VERSION "HNNBNNNYNNNNNNNNNNNNNNNNNNNNNNNNNNNNNNNNNN/4/%%%/4/'%**4NNN///"

NS_ :

BS_:

BU_: Airbag BAP_Tester ICAS1_Gateway ICAS1_KommunikationsServer LE1 LE2 Motor_BEV Schaltbetaetigung

BO_ 333 ACC_18: 32 ICAS1_Gateway
 SG_ ACC_18_CRC : 0|8@1+ (1,0) [0|255] "mietek ooo"  Motor_BEV
 SG_ ACC_18_BZ : 8|4@1+ (1,0) [0|15] ""  Motor_BEV
 SG_ ACC_limitierte_Anfahrdyn : 12|1@1+ (1.0,0.0) [0.0|1] ""  Motor_BEV
 SG_ ACC_nachtr_Stopp_Anf : 13|1@1+ (1.0,0.0) [0.0|1] ""  Vector__XXX
 SG_ ACC_DynErhoehung : 14|1@1+ (1.0,0.0) [0.0|1] ""  Motor_BEV
 SG_ ACC_Freilaufstrategie_TSK : 15|1@1+ (1.0,0.0) [0.0|1] ""  Motor_BEV
 SG_ ACC_zul_Regelabw_unten : 16|6@1+ (0.024,0) [0.000|1.512] "Unit_MeterPerSeconSquar"  Motor_BEV
 SG_ ACC_StartStopp_Info : 22|2@1+ (1.0,0.0) [0.0|3] ""  Vector__XXX
 SG_ ACC_Sollbeschleunigung_02 : 24|11@1+ (0.005,-7.22) [-7.220|3.005] "Unit_MeterPerSeconSquar"  Motor_BEV
 SG_ ACC_zul_Regelabw_oben : 35|5@1+ (0.0625,0) [0.0000|1.9375] "Unit_MeterPerSeconSquar"  Motor_BEV
 SG_ ACC_neg_Sollbeschl_Grad_02 : 40|8@1+ (0.05,0) [0.00|12.75] "Unit_MeterPerCubicSecon"  Motor_BEV
 SG_ ACC_pos_Sollbeschl_Grad_02 : 48|8@1+ (0.05,0) [0.00|12.75] "Unit_MeterPerCubicSecon"  Motor_BEV
 SG_ ACC_Anfahren : 56|1@1+ (1.0,0.0) [0.0|1] ""  Motor_BEV
 SG_ ACC_Anhalten : 57|1@1+ (1.0,0.0) [0.0|1] ""  Motor_BEV
 SG_ ACC_Typ : 58|2@1+ (1.0,0.0) [0.0|3] ""  Motor_BEV
 SG_ ACC_Status_ACC : 60|3@1+ (1.0,0.0) [0.0|7] ""  Motor_BEV
 SG_ ACC_Minimale_Bremsung : 63|1@1+ (1.0,0.0) [0.0|1] ""  Motor_BEV
 SG_ ACC_Anhalteweg : 64|11@1+ (0.01,0) [0.00|20.45] "Unit_Meter"  Vector__XXX
 SG_ ACC_Boost : 75|1@1+ (1.0,0.0) [0.0|1] ""  Vector__XXX
 SG_ ACC_Freilauf_Anf : 76|1@1+ (1.0,0.0) [0.0|1] ""  Vector__XXX
 SG_ ACC_Anforderung_HMS : 77|3@1+ (1.0,0.0) [0.0|7] ""  Vector__XXX
 SG_ ACC_Folgebeschl : 80|8@1+ (0.03,-4.6) [-4.60|2.99] "Unit_MeterPerSeconSquar"  Motor_BEV
 SG_ ACC_Freilauf_Info : 88|2@1+ (1.0,0.0) [0.0|3] ""  Motor_BEV
 SG_ ACC_Tempolimitassistent_Ein : 90|1@1+ (1.0,0.0) [0.0|1] ""  Vector__XXX
 SG_ ACC_FoD_Status : 91|2@1+ (1.0,0.0) [0.0|3] ""  Motor_BEV
 SG_ vESC_Verz_Anf : 232|4@1+ (0.5,0) [0.0|3.5] "Unit_MeterPerSeconSquar"  Vector__XXX
 SG_ RDR_v_ueber_Grund : 236|12@1+ (0.1,0) [0.0|409.0] "Unit_KiloMeterPerHour"  Vector__XXX
 SG_ RDR_v_ueber_Grund_Genauigkeit : 248|6@1+ (0.1,0) [0.0|6.0] "Unit_KiloMeterPerHour"  Vector__XXX
 SG_ RDR_v_ueber_Grund_Fahrtrichtung : 254|2@1+ (1.0,0.0) [0.0|3] ""  Vector__XXX

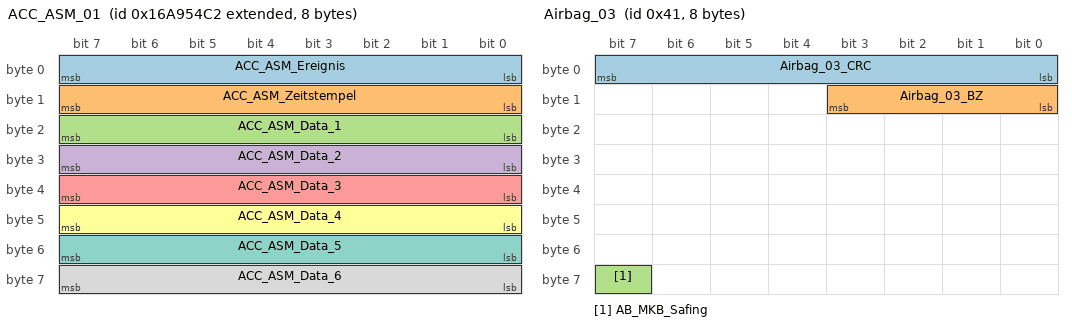
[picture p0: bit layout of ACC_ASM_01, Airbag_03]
BO_ 2527679682 ACC_ASM_01: 8 ICAS1_Gateway
 SG_ ACC_ASM_Ereignis : 0|8@1+ (1,0) [1|254] ""  Airbag
 SG_ ACC_ASM_Zeitstempel : 8|8@1+ (0.08,0) [0.00|20.32] "Unit_Secon"  Airbag
 SG_ ACC_ASM_Data_1 : 16|8@1+ (1,0) [0|255] ""  Airbag
 SG_ ACC_ASM_Data_2 : 24|8@1+ (1,0) [0|255] ""  Airbag
 SG_ ACC_ASM_Data_3 : 32|8@1+ (1,0) [0|255] ""  Airbag
 SG_ ACC_ASM_Data_4 : 40|8@1+ (1,0) [0|255] ""  Airbag
 SG_ ACC_ASM_Data_5 : 48|8@1+ (1,0) [0|255] ""  Airbag
 SG_ ACC_ASM_Data_6 : 56|8@1+ (1,0) [0|255] ""  Airbag

BO_ 64 Airbag_01: 8 Airbag
 SG_ Airbag_01_CRC : 0|8@1+ (1,0) [0|255] ""  ICAS1_Gateway,LE1,LE2,Motor_BEV
 SG_ Airbag_01_BZ : 8|4@1+ (1,0) [0|15] ""  ICAS1_Gateway,LE1,LE2,Motor_BEV
 SG_ AB_RGS_Anst : 12|4@1+ (1.0,0.0) [0.0|15] ""  ICAS1_Gateway,ICAS1_KommunikationsServer
 SG_ AB_Front_Crash : 16|1@1+ (1.0,0.0) [0.0|1] ""  ICAS1_Gateway
 SG_ AB_Heck_Crash : 17|1@1+ (1.0,0.0) [0.0|1] ""  ICAS1_Gateway
 SG_ AB_SF_Crash : 18|1@1+ (1.0,0.0) [0.0|1] ""  ICAS1_Gateway
 SG_ AB_SB_Crash : 19|1@1+ (1.0,0.0) [0.0|1] ""  ICAS1_Gateway
 SG_ AB_Rollover_Crash : 20|1@1+ (1.0,0.0) [0.0|1] ""  ICAS1_Gateway
 SG_ AB_Crash_Int : 21|3@1+ (1.0,0.0) [0.0|7] ""  ICAS1_Gateway,ICAS1_KommunikationsServer,Motor_BEV
 SG_ AB_Lampe : 24|1@1+ (1.0,0.0) [0.0|1] ""  ICAS1_Gateway,ICAS1_KommunikationsServer
 SG_ AB_Deaktiviert : 25|1@1+ (1.0,0.0) [0.0|1] ""  ICAS1_Gateway
 SG_ AB_VB_deaktiviert : 26|1@1+ (1.0,0.0) [0.0|1] ""  ICAS1_Gateway
 SG_ AB_Systemfehler : 27|1@1+ (1.0,0.0) [0.0|1] ""  ICAS1_Gateway,ICAS1_KommunikationsServer
 SG_ AB_Diagnose : 28|1@1+ (1.0,0.0) [0.0|1] ""  ICAS1_Gateway
 SG_ AB_Stellgliedtest : 29|1@1+ (1.0,0.0) [0.0|1] ""  ICAS1_Gateway
 SG_ AB_Erh_Auf_VB : 30|2@1+ (1.0,0.0) [0.0|3] ""  ICAS1_Gateway
 SG_ AB_Gurtwarn_VF : 32|1@1+ (1.0,0.0) [0.0|1] ""  ICAS1_Gateway,ICAS1_KommunikationsServer
 SG_ AB_Gurtwarn_VB : 33|1@1+ (1.0,0.0) [0.0|1] ""  ICAS1_Gateway,ICAS1_KommunikationsServer
 SG_ AB_Anzeige_Fussg : 34|2@1+ (1.0,0.0) [0.0|3] ""  ICAS1_Gateway
 SG_ AB_Texte_AKS : 36|2@1+ (1.0,0.0) [0.0|3] ""  ICAS1_Gateway
 SG_ AB_PAO_Leuchte_Anf : 38|1@1+ (1.0,0.0) [0.0|1] ""  ICAS1_Gateway
 SG_ AB_MKB_gueltig : 39|1@1+ (1.0,0.0) [0.0|1] ""  ICAS1_Gateway
 SG_ AB_MKB_Anforderung : 40|1@1+ (1.0,0.0) [0.0|1] ""  ICAS1_Gateway
 SG_ AB_Versorgungsspannung : 41|1@1+ (1.0,0.0) [0.0|1] ""  ICAS1_Gateway
 SG_ AB_Deaktivierung_HV : 42|3@1+ (1.0,0.0) [0.0|7] ""  ICAS1_Gateway,ICAS1_KommunikationsServer,LE1,LE2,Motor_BEV
 SG_ AB_EDR_Trigger : 45|2@1+ (1.0,0.0) [0.0|3] ""  ICAS1_Gateway
 SG_ AB_Belegung_VF : 47|2@1+ (1.0,0.0) [0.0|3] ""  ICAS1_Gateway
 SG_ AB_Gurtschloss_FA_ext : 49|3@1+ (1.0,0.0) [0.0|7] ""  ICAS1_Gateway
 SG_ AB_Belegung_VF_ext : 52|3@1+ (1.0,0.0) [0.0|7] ""  ICAS1_Gateway
 SG_ ASM_Masterzeit : 56|8@1+ (0.08,0) [0.00|20.32] "Unit_Secon"  ICAS1_Gateway

BO_ 1312 Airbag_02: 8 Airbag
 SG_ Airbag_02_CRC : 0|8@1+ (1,0) [0|255] ""  ICAS1_Gateway,Motor_BEV
 SG_ Airbag_02_BZ : 8|4@1+ (1,0) [0|15] ""  ICAS1_Gateway,Motor_BEV
 SG_ LoGeWa_Event_Kombiwarnung : 12|4@1+ (1.0,0.0) [0.0|15] ""  ICAS1_Gateway
 SG_ AB_Anforderung_eCall : 16|1@1+ (1.0,0.0) [0.0|1] ""  ICAS1_Gateway
 SG_ AB_Anprall_Seite_Beifahrer : 17|1@1+ (1.0,0.0) [0.0|1] ""  ICAS1_Gateway,ICAS1_KommunikationsServer
 SG_ AB_Anprall_Rollover : 18|1@1+ (1.0,0.0) [0.0|1] ""  ICAS1_Gateway,ICAS1_KommunikationsServer
 SG_ AB_Anprall_FGS : 19|1@1+ (1.0,0.0) [0.0|1] ""  ICAS1_Gateway,ICAS1_KommunikationsServer
 SG_ AB_Anprall_Front_Beifahrer : 20|1@1+ (1.0,0.0) [0.0|1] ""  ICAS1_Gateway,ICAS1_KommunikationsServer
 SG_ AB_Anprall_Front_Fahrer : 21|1@1+ (1.0,0.0) [0.0|1] ""  ICAS1_Gateway,ICAS1_KommunikationsServer
 SG_ AB_Anprall_Heck_Beifahrer : 22|1@1+ (1.0,0.0) [0.0|1] ""  ICAS1_Gateway,ICAS1_KommunikationsServer
 SG_ AB_Anprall_Heck_Fahrer : 23|1@1+ (1.0,0.0) [0.0|1] ""  ICAS1_Gateway,ICAS1_KommunikationsServer
 SG_ AB_Wickelklappung_Reihe2_MI : 24|2@1+ (1.0,0.0) [0.0|3] ""  ICAS1_Gateway
 SG_ AB_Belegung_VB : 26|2@1+ (1.0,0.0) [0.0|3] ""  ICAS1_Gateway
 SG_ AB_Abschaltanf_SIH_BF : 28|1@1+ (1.0,0.0) [0.0|1] ""  ICAS1_Gateway
 SG_ AB_Anprall_Seite_Fahrer : 29|1@1+ (1.0,0.0) [0.0|1] ""  ICAS1_Gateway,ICAS1_KommunikationsServer
 SG_ SC_PAO_Schriftzug_Anf : 30|2@1+ (1.0,0.0) [0.0|3] ""  ICAS1_Gateway
 SG_ SC_PAO_ON_Anf : 32|2@1+ (1.0,0.0) [0.0|3] ""  ICAS1_Gateway
 SG_ SC_PAO_OFF_Anf : 34|2@1+ (1.0,0.0) [0.0|3] ""  ICAS1_Gateway
 SG_ AB_Crashschwere : 36|3@1+ (1.0,0.0) [0.0|7] ""  ICAS1_Gateway,ICAS1_KommunikationsServer
 SG_ AB_Anforderung_USM : 39|1@1+ (1.0,0.0) [0.0|1] ""  ICAS1_Gateway
 SG_ AB_Gurtschloss_FA : 40|2@1+ (1.0,0.0) [0.0|3] ""  ICAS1_Gateway,ICAS1_KommunikationsServer,Motor_BEV
 SG_ AB_Gurtschloss_BF : 42|2@1+ (1.0,0.0) [0.0|3] ""  ICAS1_Gateway,ICAS1_KommunikationsServer
 SG_ AB_Gurtschloss_Reihe2_FA : 44|2@1+ (1.0,0.0) [0.0|3] ""  ICAS1_Gateway,ICAS1_KommunikationsServer
 SG_ AB_Gurtschloss_Reihe2_MI : 46|2@1+ (1.0,0.0) [0.0|3] ""  ICAS1_Gateway,ICAS1_KommunikationsServer
 SG_ AB_Gurtschloss_Reihe2_BF : 48|2@1+ (1.0,0.0) [0.0|3] ""  ICAS1_Gateway,ICAS1_KommunikationsServer
 SG_ AB_Gurtschloss_Reihe3_FA : 50|2@1+ (1.0,0.0) [0.0|3] ""  ICAS1_Gateway,ICAS1_KommunikationsServer
 SG_ AB_Gurtschloss_Reihe3_MI : 52|2@1+ (1.0,0.0) [0.0|3] ""  ICAS1_Gateway,ICAS1_KommunikationsServer
 SG_ AB_Gurtschloss_Reihe3_BF : 54|2@1+ (1.0,0.0) [0.0|3] ""  ICAS1_Gateway,ICAS1_KommunikationsServer
 SG_ AB_Sitzpos_Sens_FA : 56|2@1+ (1.0,0.0) [0.0|3] ""  ICAS1_Gateway
 SG_ AB_Sitzpos_Sens_BF : 58|2@1+ (1.0,0.0) [0.0|3] ""  ICAS1_Gateway
 SG_ AB_Wickelklappung_Reihe2_BF : 60|2@1+ (1.0,0.0) [0.0|3] ""  ICAS1_Gateway
 SG_ AB_Wickelklappung_Reihe2_FA : 62|2@1+ (1.0,0.0) [0.0|3] ""  ICAS1_Gateway

BO_ 65 Airbag_03: 8 Airbag
 SG_ Airbag_03_CRC : 0|8@1+ (1,0) [0|255] ""  ICAS1_Gateway
 SG_ Airbag_03_BZ : 8|4@1+ (1,0) [0|15] ""  ICAS1_Gateway
 SG_ AB_MKB_Safing : 63|1@1+ (1.0,0.0) [0.0|1] ""  ICAS1_Gateway

BO_ 1349 Airbag_04: 8 Airbag
 SG_ AB_Gurtwarn_Reihe4_FA : 14|2@1+ (1.0,0.0) [0.0|3] ""  ICAS1_Gateway,ICAS1_KommunikationsServer
 SG_ AB_Gurtwarn_Reihe4_BF : 16|2@1+ (1.0,0.0) [0.0|3] ""  ICAS1_Gateway,ICAS1_KommunikationsServer
 SG_ AB_Gurtwarn_Reihe4_MI : 18|2@1+ (1.0,0.0) [0.0|3] ""  ICAS1_Gateway,ICAS1_KommunikationsServer
 SG_ AB_Gurtwarn_Reihe2_FA : 20|2@1+ (1.0,0.0) [0.0|3] ""  ICAS1_Gateway,ICAS1_KommunikationsServer
 SG_ AB_Gurtwarn_Reihe2_BF : 22|2@1+ (1.0,0.0) [0.0|3] ""  ICAS1_Gateway,ICAS1_KommunikationsServer
 SG_ AbstWarn_MV_FAS_Fkt_Status : 24|2@1+ (1.0,0.0) [0.0|3] ""  ICAS1_Gateway
 SG_ WarnBrems_Charisma_Status : 26|2@1+ (1.0,0.0) [0.0|3] ""  ICAS1_Gateway
 SG_ WarnBrems_Charisma_FahrPr : 28|4@1+ (1.0,0.0) [0.0|15] ""  ICAS1_Gateway
 SG_ AB_Gurtwarn_Reihe2_MI : 32|2@1+ (1.0,0.0) [0.0|3] ""  ICAS1_Gateway,ICAS1_KommunikationsServer
 SG_ AB_Gurtwarn_Reihe3_FA : 34|2@1+ (1.0,0.0) [0.0|3] ""  ICAS1_Gateway,ICAS1_KommunikationsServer
 SG_ AB_Gurtwarn_Reihe3_MI : 36|2@1+ (1.0,0.0) [0.0|3] ""  ICAS1_Gateway,ICAS1_KommunikationsServer
 SG_ AB_Gurtwarn_Reihe3_BF : 38|2@1+ (1.0,0.0) [0.0|3] ""  ICAS1_Gateway,ICAS1_KommunikationsServer
 SG_ LGI_FAS_Fkt_Status : 40|2@1+ (1.0,0.0) [0.0|3] ""  ICAS1_Gateway
 SG_ PreCrash_FAS_Fkt_Status : 42|3@1+ (1.0,0.0) [0.0|7] ""  ICAS1_Gateway
 SG_ AB_SBR_hinten_verbau : 48|2@1+ (1.0,0.0) [0.0|3] ""  ICAS1_Gateway,ICAS1_KommunikationsServer
 SG_ AWV_Einstellung_System_ASG : 51|1@1+ (1.0,0.0) [0.0|1] ""  ICAS1_Gateway
 SG_ AWV_Einstellung_Warnung_ASG : 52|3@1+ (1.0,0.0) [0.0|7] ""  ICAS1_Gateway
 SG_ SC_PreSense_Modus_Warnung_NV : 55|3@1+ (1.0,0.0) [0.0|7] ""  ICAS1_Gateway
 SG_ SC_PreSense_Modus_Warnung_MV : 58|3@1+ (1.0,0.0) [0.0|7] ""  ICAS1_Gateway
 SG_ SC_PreSense_Modus_System_MV : 61|1@1+ (1.0,0.0) [0.0|1] ""  ICAS1_Gateway
 SG_ SC_PreSense_Modus_System_NV : 62|1@1+ (1.0,0.0) [0.0|1] ""  ICAS1_Gateway
 SG_ SC_PreSense_Modus_System_KAS : 63|1@1+ (1.0,0.0) [0.0|1] ""  ICAS1_Gateway

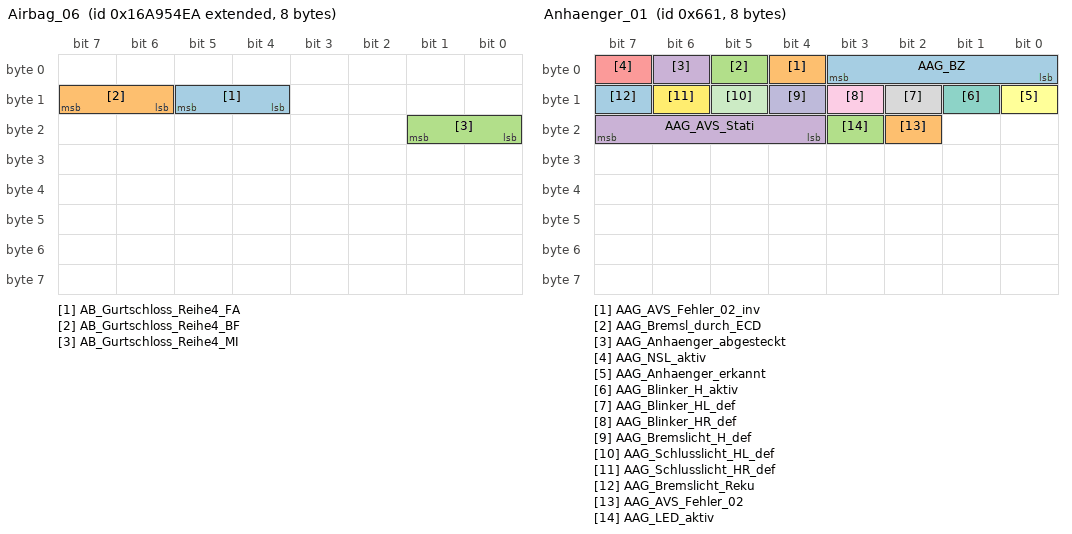
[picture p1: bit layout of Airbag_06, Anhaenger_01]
BO_ 2527679722 Airbag_06: 8 Airbag
 SG_ AB_Gurtschloss_Reihe4_FA : 12|2@1+ (1.0,0.0) [0.0|3] ""  ICAS1_Gateway,ICAS1_KommunikationsServer
 SG_ AB_Gurtschloss_Reihe4_BF : 14|2@1+ (1.0,0.0) [0.0|3] ""  ICAS1_Gateway,ICAS1_KommunikationsServer
 SG_ AB_Gurtschloss_Reihe4_MI : 16|2@1+ (1.0,0.0) [0.0|3] ""  ICAS1_Gateway,ICAS1_KommunikationsServer

BO_ 1633 Anhaenger_01: 8 ICAS1_Gateway
 SG_ AAG_BZ : 0|4@1+ (1,0) [0|15] ""  Vector__XXX
 SG_ AAG_AVS_Fehler_02_inv : 4|1@1+ (1.0,0.0) [0.0|1] ""  Vector__XXX
 SG_ AAG_Bremsl_durch_ECD : 5|1@1+ (1.0,0.0) [0.0|1] ""  Motor_BEV
 SG_ AAG_Anhaenger_abgesteckt : 6|1@1+ (1.0,0.0) [0.0|1] ""  Motor_BEV
 SG_ AAG_NSL_aktiv : 7|1@1+ (1.0,0.0) [0.0|1] ""  Vector__XXX
 SG_ AAG_Anhaenger_erkannt : 8|1@1+ (1.0,0.0) [0.0|1] ""  Motor_BEV
 SG_ AAG_Blinker_H_aktiv : 9|1@1+ (1.0,0.0) [0.0|1] ""  Vector__XXX
 SG_ AAG_Blinker_HL_def : 10|1@1+ (1.0,0.0) [0.0|1] ""  Vector__XXX
 SG_ AAG_Blinker_HR_def : 11|1@1+ (1.0,0.0) [0.0|1] ""  Vector__XXX
 SG_ AAG_Bremslicht_H_def : 12|1@1+ (1.0,0.0) [0.0|1] ""  Motor_BEV
 SG_ AAG_Schlusslicht_HL_def : 13|1@1+ (1.0,0.0) [0.0|1] ""  Vector__XXX
 SG_ AAG_Schlusslicht_HR_def : 14|1@1+ (1.0,0.0) [0.0|1] ""  Vector__XXX
 SG_ AAG_Bremslicht_Reku : 15|1@1+ (1.0,0.0) [0.0|1] ""  Vector__XXX
 SG_ AAG_AVS_Fehler_02 : 18|1@1+ (1.0,0.0) [0.0|1] ""  Vector__XXX
 SG_ AAG_LED_aktiv : 19|1@1+ (1.0,0.0) [0.0|1] ""  Vector__XXX
 SG_ AAG_AVS_Stati : 20|4@1+ (1.0,0.0) [0.0|15] ""  Vector__XXX

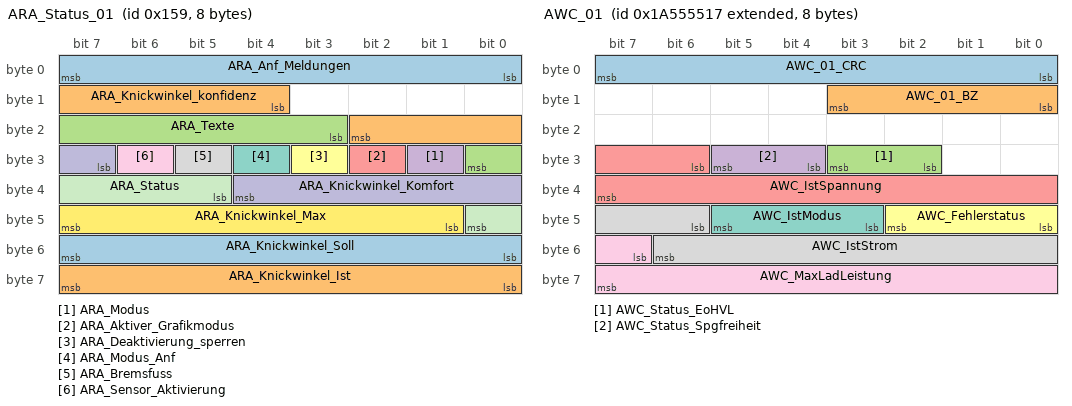
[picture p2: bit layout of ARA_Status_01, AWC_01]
BO_ 345 ARA_Status_01: 8 ICAS1_Gateway
 SG_ ARA_Anf_Meldungen : 0|8@1+ (1.0,0.0) [0.0|255] ""  Vector__XXX
 SG_ ARA_Knickwinkel_konfidenz : 12|7@1+ (1,0) [0|120] "Unit_DegreOfArc"  Vector__XXX
 SG_ ARA_Texte : 19|6@1+ (1.0,0.0) [0.0|63] ""  Vector__XXX
 SG_ ARA_Modus : 25|1@1+ (1.0,0.0) [0.0|1] ""  Vector__XXX
 SG_ ARA_Aktiver_Grafikmodus : 26|1@1+ (1.0,0.0) [0.0|1] ""  Vector__XXX
 SG_ ARA_Deaktivierung_sperren : 27|1@1+ (1.0,0.0) [0.0|1] ""  Vector__XXX
 SG_ ARA_Modus_Anf : 28|1@1+ (1.0,0.0) [0.0|1] ""  Vector__XXX
 SG_ ARA_Bremsfuss : 29|1@1+ (1.0,0.0) [0.0|1] ""  Vector__XXX
 SG_ ARA_Sensor_Aktivierung : 30|1@1+ (1.0,0.0) [0.0|1] ""  Vector__XXX
 SG_ ARA_Knickwinkel_Komfort : 31|6@1+ (1,0) [0|60] "Unit_DegreOfArc"  Vector__XXX
 SG_ ARA_Status : 37|4@1+ (1.0,0.0) [0.0|15] ""  Motor_BEV
 SG_ ARA_Knickwinkel_Max : 41|7@1+ (1,0) [0|120] "Unit_DegreOfArc"  Vector__XXX
 SG_ ARA_Knickwinkel_Soll : 48|8@1+ (1,-125) [-125|126] "Unit_DegreOfArc"  Vector__XXX
 SG_ ARA_Knickwinkel_Ist : 56|8@1+ (1,-125) [-125|126] "Unit_DegreOfArc"  Vector__XXX

BO_ 2589283607 AWC_01: 8 ICAS1_Gateway
 SG_ AWC_01_CRC : 0|8@1+ (1,0) [0|255] ""  Vector__XXX
 SG_ AWC_01_BZ : 8|4@1+ (1,0) [0|15] ""  Vector__XXX
 SG_ AWC_Status_EoHVL : 26|2@1+ (1.0,0.0) [0.0|3] ""  Motor_BEV
 SG_ AWC_Status_Spgfreiheit : 28|2@1+ (1.0,0.0) [0.0|3] ""  Vector__XXX
 SG_ AWC_IstSpannung : 30|10@1+ (1,0) [0|1021] "Unit_Volt"  Vector__XXX
 SG_ AWC_Fehlerstatus : 40|3@1+ (1.0,0.0) [0.0|7] ""  Vector__XXX
 SG_ AWC_IstModus : 43|3@1+ (1.0,0.0) [0.0|7] ""  Vector__XXX
 SG_ AWC_IstStrom : 46|9@1+ (0.1,0) [0.0|50.9] "Unit_Amper"  Vector__XXX
 SG_ AWC_MaxLadLeistung : 55|9@1+ (25,0) [0|12725] "Unit_Watt"  Vector__XXX

BO_ 219 AWV_03: 48 ICAS1_Gateway
 SG_ AWV_03_CRC : 0|8@1+ (1,0) [0|255] ""  Airbag
 SG_ AWV_03_BZ : 8|4@1+ (1,0) [0|15] ""  Airbag
 SG_ PCF_Freigabe : 12|1@1+ (1.0,0.0) [0.0|1] ""  Airbag
 SG_ SDF_PSF_Objektstatus : 13|3@1+ (1.0,0.0) [0.0|7] ""  Airbag
 SG_ SDF_PSF_CU_Status : 16|1@1+ (1.0,0.0) [0.0|1] ""  Airbag
 SG_ SDF_PSF_CW : 17|7@1+ (1,0) [0|100] ""  Airbag
 SG_ SDF_PSF_Fahrer_aktiv : 24|1@1+ (1.0,0.0) [0.0|1] ""  Airbag
 SG_ SDF_PSF_Guete : 25|2@1+ (1.0,0.0) [0.0|3] ""  Airbag
 SG_ SDF_PSF_Kollisionsueberdeckung : 27|5@1+ (0.1,0) [0.1|2.8] "Unit_Meter"  Airbag
 SG_ SDF_PSF_Time_To_Collision : 32|8@1+ (0.01,0) [0.00|2.50] "Unit_Secon"  Vector__XXX
 SG_ SDF_PSF_v_rel : 40|8@1+ (0.4,0) [0.4|101.2] "Unit_MeterPerSecon"  Airbag
 SG_ AWV_Eingriff_Sendeart : 64|1@1+ (1.0,0.0) [0.0|1] ""  Airbag
 SG_ AWV_Verz_Freigabe : 65|1@1+ (1.0,0.0) [0.0|1] ""  Airbag
 SG_ AWV_Verz_Anf : 66|10@1+ (0.024,-20.016) [-20.016|4.512] "Unit_MeterPerSeconSquar"  Airbag
 SG_ AWV_Anf_Prefill : 76|1@1+ (1.0,0.0) [0.0|1] ""  Airbag
 SG_ AWV_Ruckprofil : 77|3@1+ (1.0,0.0) [0.0|7] ""  Vector__XXX
 SG_ AWV_Time_to_collision : 80|8@1+ (0.01,0) [0.00|2.50] "Unit_Secon"  Airbag
 SG_ AWV_HBA_Param : 88|2@1+ (1.0,0.0) [0.0|3] ""  Vector__XXX
 SG_ AWV_Verz_Anf_ASIL : 90|3@1+ (1.0,0.0) [0.0|7] ""  Vector__XXX
 SG_ AWV_Time_to_brake : 93|7@1+ (10,0) [0|1240] "Unit_MilliSecon"  Vector__XXX
 SG_ AWV_Zielobjekttyp : 100|4@1+ (1.0,0.0) [0.0|15] ""  Airbag
 SG_ AWV_QFK_KruemmSoll : 104|15@1+ (0.0000067,0) [0E-7|0.2195389] "Unit_MeterInver"  Vector__XXX
 SG_ AWV_QFK_KruemmSoll_VZ : 119|1@1+ (1.0,0.0) [0.0|1] ""  Vector__XXX
 SG_ AWV_QFK_Spuerb : 120|8@1+ (0.4,0) [0.0|100.0] "Unit_PerCent"  Vector__XXX
 SG_ AWV_QFK_AnfStat : 128|4@1+ (1.0,0.0) [0.0|15] ""  Airbag
 SG_ AWV_QFK_Signal1 : 132|10@1+ (1,0) [0|1023] ""  Vector__XXX
 SG_ AWV_QFK_Art1 : 142|3@1+ (1,0) [0|7] ""  Vector__XXX
 SG_ AWV_QFK_Art2 : 145|3@1+ (1,0) [0|7] ""  Vector__XXX
 SG_ AWV_QFK_Signal2 : 148|10@1+ (1,0) [0|1023] ""  Vector__XXX

BO_ 2536767264 BAP_Debug_Cmd: 8 BAP_Tester
 SG_ BAP_Debug_Cmd : 0|16@1+ (1.0,0.0) [0.0|65535] ""  Motor_BEV

BO_ 2536767280 BAP_Debug_Data: 8 Motor_BEV
 SG_ BAP_Debug_Data : 0|64@1+ (1.0,0.0) [0.0|18446744073709551615] ""  BAP_Tester

BO_ 2536717313 BAP_EfficiencyAssist_ASG_02: 8 ICAS1_Gateway
 SG_ BAP_EfficAssist_ASG_02_Header : 0|64@1+ (1.0,0.0) [0.0|18446744073709551615] ""  Motor_BEV

BO_ 2536717314 BAP_EfficiencyAssist_ASG_03: 8 ICAS1_Gateway
 SG_ BAP_EfficAssist_ASG_03_Header : 0|8@1+ (1.0,0.0) [0.0|255] ""  Motor_BEV

BO_ 2536717328 BAP_EfficiencyAssist_FSG_01: 8 Motor_BEV
 SG_ BAP_EfficAssist_FSG_01_Header : 0|8@1+ (1.0,0.0) [0.0|255] ""  ICAS1_Gateway

BO_ 2536709120 BAP_Hybrid_ASG_01: 8 ICAS1_Gateway
 SG_ BAP_Hybrid_ASG_01_Header : 0|8@1+ (1.0,0.0) [0.0|255] ""  Motor_BEV

BO_ 2536709136 BAP_Hybrid_FSG_01: 8 Motor_BEV
 SG_ BAP_Hybrid_FSG_01_Header : 0|8@1+ (1.0,0.0) [0.0|255] ""  ICAS1_Gateway

BO_ 869 BEM_05: 8 ICAS1_Gateway
 SG_ BEM_UBDM : 0|8@1+ (0.05,5) [5.05|17.70] "Unit_Volt"  Vector__XXX
 SG_ NVEM_Ladefreigabe : 8|2@1+ (1.0,0.0) [0.0|3] ""  Vector__XXX
 SG_ NVEM_FMAus_Info : 10|2@1+ (1.0,0.0) [0.0|3] ""  Vector__XXX
 SG_ NVEM_PTC_Sollstufe : 12|2@1+ (1.0,0.0) [0.0|3] ""  Vector__XXX
 SG_ NVEM_P_Generator_Status : 15|1@1+ (1.0,0.0) [0.0|1] ""  Vector__XXX
 SG_ BEM_P_Generator : 16|8@1+ (50,0) [0|12700] "Unit_Watt"  Vector__XXX
 SG_ BEM_n_LLA : 24|2@1+ (1.0,0.0) [0.0|3] ""  Vector__XXX
 SG_ BEM_01_Abschaltstufen : 26|3@1+ (1.0,0.0) [0.0|7] ""  Vector__XXX
 SG_ BEM_Anf_KL : 29|1@1+ (1.0,0.0) [0.0|1] ""  Vector__XXX
 SG_ BEM_StartStopp_Info : 30|2@1+ (1.0,0.0) [0.0|3] ""  Vector__XXX
 SG_ BEM_DFM : 32|5@1+ (3.225,0.025) [0.025|100.000] ""  Vector__XXX
 SG_ BEM_EMLIN_ungueltig : 37|1@1+ (1.0,0.0) [0.0|1] ""  Vector__XXX
 SG_ BEM_Batt_Ab : 38|1@1+ (1.0,0.0) [0.0|1] ""  Motor_BEV
 SG_ NVEM_FMAus_I_Verbrauch : 39|5@1+ (5,0) [0|145] "Unit_Amper"  Vector__XXX
 SG_ NVEM_Freilauf_Info : 44|2@1+ (1.0,0.0) [0.0|3] ""  Vector__XXX
 SG_ BEM_NV_NachladAnf : 46|2@1+ (1.0,0.0) [0.0|3] ""  Vector__XXX
 SG_ BEM_Segel_Info : 48|2@1+ (1.0,0.0) [0.0|3] ""  Vector__XXX
 SG_ BEM_HYB_DC_uSollLV : 50|6@1+ (0.1,10.6) [10.6|16.0] "Unit_Volt"  Vector__XXX
 SG_ BEM_HYB_DC_uMinLV : 56|8@1+ (0.1,0) [0.0|25.3] "Unit_Volt"  Vector__XXX

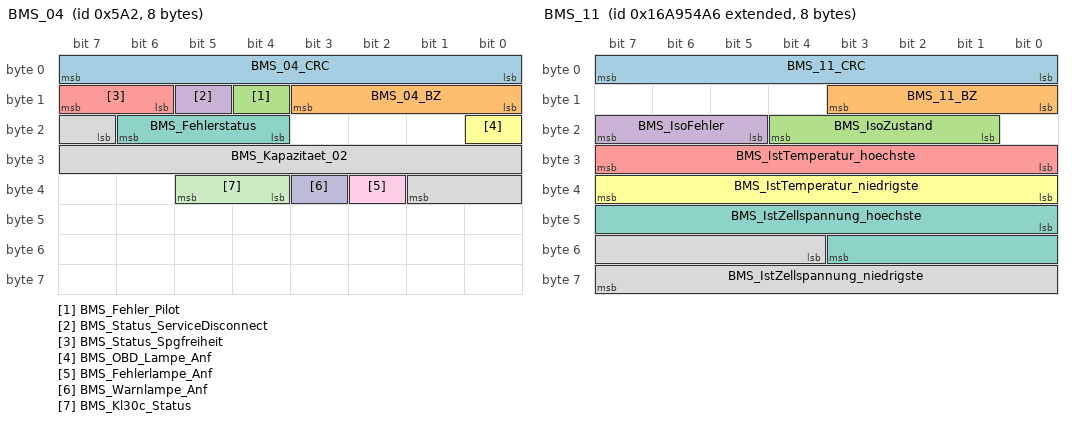
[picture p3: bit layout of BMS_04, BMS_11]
BO_ 1442 BMS_04: 8 ICAS1_Gateway
 SG_ BMS_04_CRC : 0|8@1+ (1,0) [0|255] ""  Vector__XXX
 SG_ BMS_04_BZ : 8|4@1+ (1,0) [0|15] ""  Vector__XXX
 SG_ BMS_Fehler_Pilot : 12|1@1+ (1.0,0.0) [0.0|1] ""  Vector__XXX
 SG_ BMS_Status_ServiceDisconnect : 13|1@1+ (1.0,0.0) [0.0|1] ""  Vector__XXX
 SG_ BMS_Status_Spgfreiheit : 14|2@1+ (1.0,0.0) [0.0|3] ""  Motor_BEV
 SG_ BMS_OBD_Lampe_Anf : 16|1@1+ (1.0,0.0) [0.0|1] ""  Motor_BEV
 SG_ BMS_Fehlerstatus : 20|3@1+ (1.0,0.0) [0.0|7] ""  Vector__XXX
 SG_ BMS_Kapazitaet_02 : 23|11@1+ (0.2,0) [0.0|409.2] "Unit_AmperHour"  Vector__XXX
 SG_ BMS_Fehlerlampe_Anf : 34|1@1+ (1.0,0.0) [0.0|1] ""  Motor_BEV
 SG_ BMS_Warnlampe_Anf : 35|1@1+ (1.0,0.0) [0.0|1] ""  Motor_BEV
 SG_ BMS_Kl30c_Status : 36|2@1+ (1.0,0.0) [0.0|3] ""  Motor_BEV

BO_ 2527679654 BMS_11: 8 ICAS1_Gateway
 SG_ BMS_11_CRC : 0|8@1+ (1,0) [0|255] ""  Motor_BEV
 SG_ BMS_11_BZ : 8|4@1+ (1,0) [0|15] ""  Motor_BEV
 SG_ BMS_IsoZustand : 17|4@1+ (1.0,0.0) [0.0|15] ""  Motor_BEV
 SG_ BMS_IsoFehler : 21|3@1+ (1.0,0.0) [0.0|7] ""  Motor_BEV
 SG_ BMS_IstTemperatur_hoechste : 24|8@1+ (0.5,-40) [-40.0|86.0] "Unit_DegreCelsi"  Vector__XXX
 SG_ BMS_IstTemperatur_niedrigste : 32|8@1+ (0.5,-40) [-40.0|86.0] "Unit_DegreCelsi"  Vector__XXX
 SG_ BMS_IstZellspannung_hoechste : 40|12@1+ (1,1000) [1000|5091] "Unit_MilliVolt"  Vector__XXX
 SG_ BMS_IstZellspannung_niedrigste : 52|12@1+ (1,1000) [1000|5091] "Unit_MilliVolt"  Vector__XXX

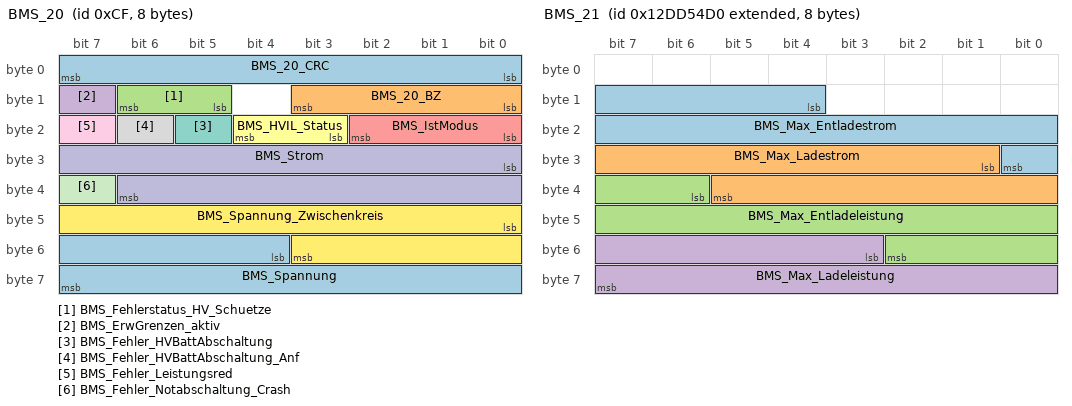
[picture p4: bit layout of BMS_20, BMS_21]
BO_ 207 BMS_20: 8 ICAS1_Gateway
 SG_ BMS_20_CRC : 0|8@1+ (1,0) [0|255] ""  Motor_BEV
 SG_ BMS_20_BZ : 8|4@1+ (1,0) [0|15] ""  Motor_BEV
 SG_ BMS_Fehlerstatus_HV_Schuetze : 13|2@1+ (1.0,0.0) [0.0|3] ""  Motor_BEV
 SG_ BMS_ErwGrenzen_aktiv : 15|1@1+ (1.0,0.0) [0.0|1] ""  Motor_BEV
 SG_ BMS_IstModus : 16|3@1+ (1.0,0.0) [0.0|7] ""  LE1,LE2,Motor_BEV
 SG_ BMS_HVIL_Status : 19|2@1+ (1.0,0.0) [0.0|3] ""  Motor_BEV
 SG_ BMS_Fehler_HVBattAbschaltung : 21|1@1+ (1.0,0.0) [0.0|1] ""  Motor_BEV
 SG_ BMS_Fehler_HVBattAbschaltung_Anf : 22|1@1+ (1.0,0.0) [0.0|1] ""  Motor_BEV
 SG_ BMS_Fehler_Leistungsred : 23|1@1+ (1.0,0.0) [0.0|1] ""  Motor_BEV
 SG_ BMS_Strom : 24|15@1+ (0.1,-1630) [-1630.0|1630.0] "Unit_Amper"  Motor_BEV
 SG_ BMS_Fehler_Notabschaltung_Crash : 39|1@1+ (1.0,0.0) [0.0|1] ""  Vector__XXX
 SG_ BMS_Spannung_Zwischenkreis : 40|12@1+ (0.5,-1000) [-1000.0|1000.0] "Unit_Volt"  Motor_BEV
 SG_ BMS_Spannung : 52|12@1+ (0.25,0) [0.00|1000.00] "Unit_Volt"  Motor_BEV

BO_ 2463978704 BMS_21: 8 ICAS1_Gateway
 SG_ BMS_Max_Entladestrom : 12|13@1+ (0.2,0) [0.0|1630.0] "Unit_Amper"  Motor_BEV
 SG_ BMS_Max_Ladestrom : 25|13@1+ (0.2,0) [0.0|1630.0] "Unit_Amper"  Motor_BEV
 SG_ BMS_Max_Entladeleistung : 38|13@1+ (100,0) [0|818000] "Unit_Watt"  Motor_BEV
 SG_ BMS_Max_Ladeleistung : 51|13@1+ (100,0) [0|818000] "Unit_Watt"  Motor_BEV

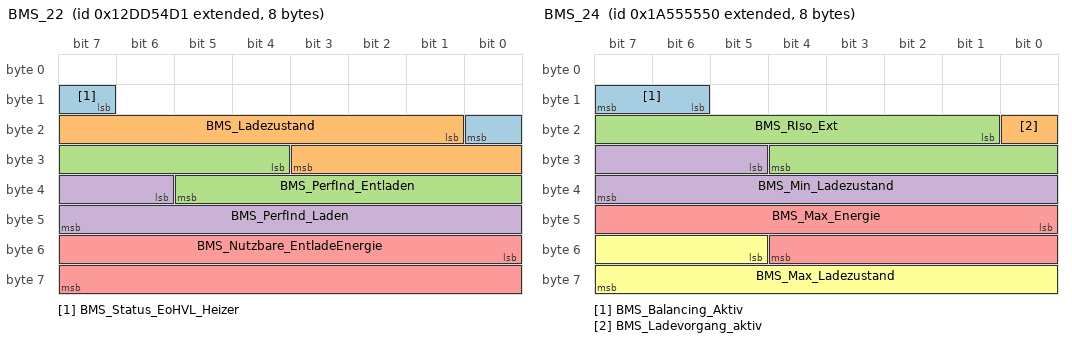
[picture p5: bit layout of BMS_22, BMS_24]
BO_ 2463978705 BMS_22: 8 ICAS1_Gateway
 SG_ BMS_Status_EoHVL_Heizer : 15|2@1+ (1.0,0.0) [0.0|3] ""  Motor_BEV
 SG_ BMS_Ladezustand : 17|11@1+ (0.05,0) [0.00|100.00] "Unit_PerCent"  Motor_BEV
 SG_ BMS_PerfInd_Entladen : 28|10@1+ (0.2,0) [0.0|200.0] "Unit_PerCent"  Motor_BEV
 SG_ BMS_PerfInd_Laden : 38|10@1+ (0.2,0) [0.0|200.0] "Unit_PerCent"  Motor_BEV
 SG_ BMS_Nutzbare_EntladeEnergie : 48|16@1+ (5,0) [0|327400] "Unit_WattHour"  Motor_BEV

BO_ 2589283664 BMS_24: 8 ICAS1_Gateway
 SG_ BMS_Balancing_Aktiv : 14|2@1+ (1.0,0.0) [0.0|3] ""  Vector__XXX
 SG_ BMS_Ladevorgang_aktiv : 16|1@1+ (1.0,0.0) [0.0|1] ""  Vector__XXX
 SG_ BMS_RIso_Ext : 17|12@1+ (5,0) [0|20465] "Unit_KiloOhm"  Motor_BEV
 SG_ BMS_Min_Ladezustand : 29|11@1+ (0.05,0) [0.00|100.00] "Unit_PerCent"  Motor_BEV
 SG_ BMS_Max_Energie : 40|13@1+ (40,0) [0|327400] "Unit_WattHour"  Motor_BEV
 SG_ BMS_Max_Ladezustand : 53|11@1+ (0.05,0) [0.00|100.00] "Unit_PerCent"  Motor_BEV

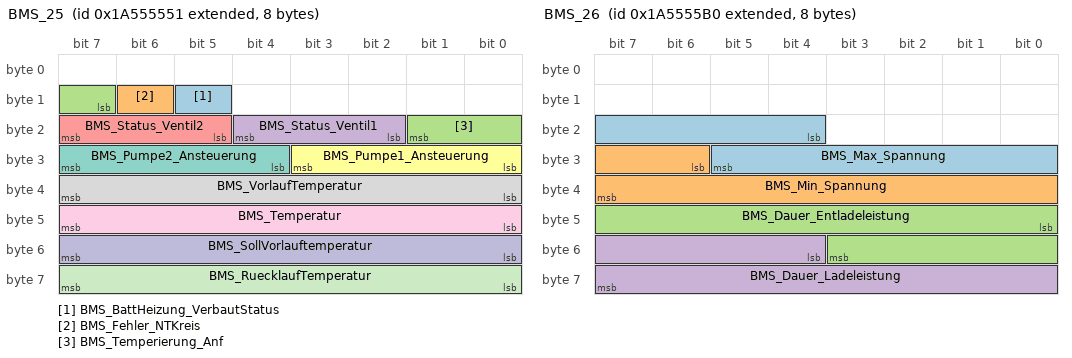
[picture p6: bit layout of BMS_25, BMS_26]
BO_ 2589283665 BMS_25: 8 ICAS1_Gateway
 SG_ BMS_BattHeizung_VerbautStatus : 13|1@1+ (1.0,0.0) [0.0|1] ""  Motor_BEV
 SG_ BMS_Fehler_NTKreis : 14|1@1+ (1.0,0.0) [0.0|1] ""  Vector__XXX
 SG_ BMS_Temperierung_Anf : 15|3@1+ (1.0,0.0) [0.0|7] ""  Motor_BEV
 SG_ BMS_Status_Ventil1 : 18|3@1+ (1.0,0.0) [0.0|7] ""  Motor_BEV
 SG_ BMS_Status_Ventil2 : 21|3@1+ (1.0,0.0) [0.0|7] ""  Motor_BEV
 SG_ BMS_Pumpe1_Ansteuerung : 24|4@1+ (10,0) [0|100] "Unit_PerCent"  Motor_BEV
 SG_ BMS_Pumpe2_Ansteuerung : 28|4@1+ (10,0) [0|100] "Unit_PerCent"  Motor_BEV
 SG_ BMS_VorlaufTemperatur : 32|8@1+ (0.5,-40) [-40.0|86.0] "Unit_DegreCelsi"  Motor_BEV
 SG_ BMS_Temperatur : 40|8@1+ (0.5,-40) [-40.0|86.5] "Unit_DegreCelsi"  Motor_BEV
 SG_ BMS_SollVorlauftemperatur : 48|8@1+ (0.5,-40) [-40.0|86.5] "Unit_DegreCelsi"  Motor_BEV
 SG_ BMS_RuecklaufTemperatur : 56|8@1+ (0.5,-40) [-40.0|86.0] "Unit_DegreCelsi"  Motor_BEV

BO_ 2589283760 BMS_26: 8 ICAS1_Gateway
 SG_ BMS_Max_Spannung : 20|10@1+ (1,0) [0|1000] "Unit_Volt"  Motor_BEV
 SG_ BMS_Min_Spannung : 30|10@1+ (1,0) [0|1000] "Unit_Volt"  Motor_BEV
 SG_ BMS_Dauer_Entladeleistung : 40|12@1+ (200,0) [0|818000] "Unit_Watt"  Motor_BEV
 SG_ BMS_Dauer_Ladeleistung : 52|12@1+ (200,0) [0|818000] "Unit_Watt"  Motor_BEV

BO_ 2463978646 Charisma_11: 24 ICAS1_Gateway
 SG_ CHA_Ziel_FahrPr_AGA : 0|4@1+ (1.0,0.0) [0.0|15] ""  Vector__XXX
 SG_ CHA_Ziel_FahrPr_ESP : 4|4@1+ (1.0,0.0) [0.0|15] ""  Motor_BEV
 SG_ CHA_Ziel_FahrPr_Freilauf : 8|4@1+ (1.0,0.0) [0.0|15] ""  Vector__XXX
 SG_ CHA_Fahrer_Umschaltung : 14|1@1+ (1.0,0.0) [0.0|1] ""  Motor_BEV
 SG_ CHA_Fahrer_Umschaltung_BMA : 15|1@1+ (1.0,0.0) [0.0|1] ""  Vector__XXX
 SG_ CHA_Ziel_FahrPr_MO : 16|4@1+ (1.0,0.0) [0.0|15] ""  Motor_BEV
 SG_ CHA_Ziel_FahrPr_GE : 20|4@1+ (1.0,0.0) [0.0|15] ""  Vector__XXX
 SG_ CHA_Ziel_FahrPr_ALR : 24|4@1+ (1.0,0.0) [0.0|15] ""  Motor_BEV
 SG_ CHA_Ziel_FahrPr_MO_BZS : 28|4@1+ (1.0,0.0) [0.0|15] ""  Vector__XXX
 SG_ CHA_Ziel_FahrPr_DR : 32|4@1+ (1.0,0.0) [0.0|15] ""  Vector__XXX
 SG_ CHA_Ziel_FahrPr_VAQ : 36|4@1+ (1.0,0.0) [0.0|15] ""  Vector__XXX
 SG_ CHA_Ziel_FahrPr_AFS : 40|4@1+ (1.0,0.0) [0.0|15] ""  Vector__XXX
 SG_ CHA_Ziel_FahrPr_PreCrash : 44|4@1+ (1.0,0.0) [0.0|15] ""  Airbag
 SG_ CHA_Ziel_FahrPr_EPS : 48|4@1+ (1.0,0.0) [0.0|15] ""  Vector__XXX
 SG_ CHA_Ziel_FahrPr_ACC : 52|4@1+ (1.0,0.0) [0.0|15] ""  Vector__XXX
 SG_ CHA_Ziel_FahrPr_SAK : 56|4@1+ (1.0,0.0) [0.0|15] ""  Vector__XXX
 SG_ CHA_Ziel_FahrPr_MO_StSt : 60|4@1+ (1.0,0.0) [0.0|15] ""  Vector__XXX
 SG_ CHA_Ziel_FahrPr_EBKV : 64|4@1+ (1.0,0.0) [0.0|15] ""  Vector__XXX
 SG_ CHA_Ziel_FahrPr_IL : 68|4@1+ (1.0,0.0) [0.0|15] ""  Vector__XXX
 SG_ CHA_Current_Mode : 72|4@1+ (1.0,0.0) [0.0|15] ""  Vector__XXX
 SG_ CHA_Ziel_FahrPr_QS : 80|4@1+ (1.0,0.0) [0.0|15] ""  Vector__XXX
 SG_ CHA_Ziel_FahrPr_SCU : 84|4@1+ (1.0,0.0) [0.0|15] ""  Vector__XXX
 SG_ CHA_Ziel_FahrPr_HAL : 88|4@1+ (1.0,0.0) [0.0|15] ""  Vector__XXX
 SG_ CHA_Ziel_FahrPr_NR : 92|4@1+ (1.0,0.0) [0.0|15] ""  Vector__XXX
 SG_ CHA_Ziel_FahrPr_AV : 96|4@1+ (1.0,0.0) [0.0|15] ""  Vector__XXX
 SG_ CHA_Ziel_FahrPr_MXB : 100|4@1+ (1.0,0.0) [0.0|15] ""  Vector__XXX
 SG_ CHA_Ziel_FahrPr_AFR : 104|4@1+ (1.0,0.0) [0.0|15] ""  Vector__XXX
 SG_ CHA_Ziel_FahrPr_HDC : 108|4@1+ (1.0,0.0) [0.0|15] ""  Vector__XXX
 SG_ CHA_Ziel_FahrPr_EAR : 112|4@1+ (1.0,0.0) [0.0|15] ""  Vector__XXX
 SG_ CHA_Ziel_FahrPr_AEB : 116|4@1+ (1.0,0.0) [0.0|15] ""  Vector__XXX
 SG_ CHA_Ziel_FahrPr_FCWO : 120|4@1+ (1.0,0.0) [0.0|15] ""  Vector__XXX
 SG_ CHA_Ziel_FahrPr_FCWP : 124|4@1+ (1.0,0.0) [0.0|15] ""  Vector__XXX
 SG_ CHA_Ziel_FahrPr_ToS_laengs : 144|4@1+ (1.0,0.0) [0.0|15] ""  Vector__XXX
 SG_ CHA_Ziel_FahrPr_ToS_quer : 148|4@1+ (1.0,0.0) [0.0|15] ""  Vector__XXX
 SG_ CHA_Ziel_FahrPr_mFDR : 152|4@1+ (1.0,0.0) [0.0|15] ""  Vector__XXX
 SG_ CHA_Ziel_FahrPr_Reku_ZwGas : 156|4@1+ (1.0,0.0) [0.0|15] ""  Vector__XXX
 SG_ CHA_Ziel_FahrPr_MO_Freilauf : 160|4@1+ (1.0,0.0) [0.0|15] ""  Vector__XXX
 SG_ CHA_Ziel_FahrPr_BMS : 164|4@1+ (1.0,0.0) [0.0|15] ""  Vector__XXX
 SG_ CHA_Current_Mode_BMA : 168|4@1+ (1.0,0.0) [0.0|15] ""  Vector__XXX
 SG_ CHA_Ziel_FahrPr_PDC : 172|4@1+ (1.0,0.0) [0.0|15] ""  Vector__XXX
 SG_ CHA_Ziel_FahrPr_HHC : 176|4@1+ (1.0,0.0) [0.0|15] ""  Vector__XXX
 SG_ CHA_Ziel_FahrPr_EDS : 180|4@1+ (1.0,0.0) [0.0|15] ""  Vector__XXX
 SG_ CHA_Ziel_FahrPr_PACC : 184|4@1+ (1.0,0.0) [0.0|15] ""  Vector__XXX
 SG_ CHA_Ziel_FahrPr_AGK : 188|4@1+ (1.0,0.0) [0.0|15] ""  Vector__XXX

CM_ "MEB_ACANFD_V10.04.03F Generated by BusNet_NG_Produktiv 9.9.3";
CM_ BU_ Airbag "Airbag MQB2020";
CM_ BU_ ICAS1_Gateway "ICAS1 MEB
DFL-Kürzel: Gateway";
CM_ BU_ LE1 "Leistungselektronik MQB2020 (BEV und PHEV)";
CM_ BU_ LE2 "Leistungselektronik 2 MQB2020 (BEV und PHEV)";
CM_ BU_ Motor_BEV "Motor-SG (Antriebs-SG) MQB2020 BEV";
CM_ BU_ Schaltbetaetigung "Monostabiler Wählhebel MQB2020";

CM_ BO_ 1633 "ab MQB 7.2";
CM_ BO_ 2536717313 "BAP ASG message EfficiencyAssist (PEA)<br>
Sender: Kombi
Receiver: MSG";
CM_ BO_ 2536717314 "BAP ASG message EfficiencyAssist (PEA)<br>
Sender: Kombi
Receiver: MSG";
CM_ BO_ 2536717328 "BAP FSG message EfficiencyAssist (PEA)<br>
Sender: MSG<br>
Receiver: HU (MIB)";
CM_ BO_ 869 "ab MQB";
CM_ BO_ 2463978646 "ab MQB ohne CHK und mit geänderter Sendeart";

CM_ SG_ 333 ACC_18_BZ "4bit Botschaftszähler, wird mit jeder Sendebotschaft inkrementiert";
CM_ SG_ 333 ACC_18_CRC "Für MLB:
Berechnung siehe Lastenheft 'Kommunikationsabsicherung für FlexRay und CAN'
Ab MQB und MLBevo:
Berechnung siehe Lastenheft 'End-to-End Kommunikationsabsicherung'

Endwerte siehe Begleitdokument 'S-PDU Kennungsfolgen'";
CM_ SG_ 333 ACC_Anfahren "Anforderung Anfahren";
CM_ SG_ 333 ACC_Anforderung_HMS "Bremsanforderung an den Haltemanager";
CM_ SG_ 333 ACC_Anhalten "Im Falle eines gesetzten Bits wird vom ACC ein Anhalten bis in den Stand gewünscht. Das Bit wird von ACC nur unterhalb einer appl. Geschwindigkeitsschwelle gesetzt. Notwendig für die ACCplus-Funktionalität. Nicht für Audi B8 relevant, jedoch im Vorgriff a";
CM_ SG_ 333 ACC_Anhalteweg "Verbleibender Weg bis zum Stillstand";
CM_ SG_ 333 ACC_Boost "Aktivität der Boost-Funktion des ACC";
CM_ SG_ 333 ACC_DynErhoehung "Ansteuerung einer erhöhten Dynamik im Verzögerungsfall (vor allem beim Motormomentenabbau)";
CM_ SG_ 333 ACC_FoD_Status "Informiert den TSK und Kombi, ob die ACC-Funktion freigeschaltet ist oder nicht.";
CM_ SG_ 333 ACC_Folgebeschl "Sollbeschleunigung des ACC-Folgeregler";
CM_ SG_ 333 ACC_Freilauf_Anf "Freilauf-Anforderung durch Energo/ACC";
CM_ SG_ 333 ACC_Freilauf_Info "Freilauf-Freigabe durch Aktiven Teilnehmer Freilauf";
CM_ SG_ 333 ACC_Freilaufstrategie_TSK "Das Signal definiert im aktiven ACC - Betrieb, ob ein Freilauf direkt über das ACC angefordert wird oder ein Freilauf über den Triebstrangkoordinator (TSK) angefordert wird, falls das ACC den Freilauf freigibt.";
CM_ SG_ 333 ACC_limitierte_Anfahrdyn "Info für den Motor, dass beim ACC-Anfahren mit Zielfahrzeug seitens ACC eine limitierte Fahrpedalkennlinie gefordert wird.";
CM_ SG_ 333 ACC_Minimale_Bremsung "Im Falle eines gesetzten Bits wird vom ACC dem TSK angezeigt, dass es sich im Resume_Suspend_Mode befindet. In diesem Mode darf der TSK keine ECD-Bremsung anfordern, unabhängig von der 'ACC_Sollbeschleunigungsanforderung'. Eine Fahrzeugverzögerung darf nu";
CM_ SG_ 333 ACC_nachtr_Stopp_Anf "Dieses Signal dient dem Motor als Trigger, dass ein nachträglicher Motorstopp eingeleitet werden kann, wenn es die Bedingungen des StSt Koordinators dies zulassen.";
CM_ SG_ 333 ACC_neg_Sollbeschl_Grad_02 "Empfehlung an den Triebstrangkoordinator , mit welchem betragsmäßig maximalen negativen Gradienten eine ACC-Anforderung 'ACC_Sollbeschleunigung_02' einzuregeln ist.";
CM_ SG_ 333 ACC_pos_Sollbeschl_Grad_02 "Empfehlung an den Triebstrangkoordinator , mit welchem betragsmäßig maximalen positiven Gradienten eine ACC-Anforderung 'ACC_Sollbeschleunigung_02' einzuregeln ist.";
CM_ SG_ 333 ACC_Sollbeschleunigung_02 "Anforderung an den Triebstrangkoordinator , eine 'ACC_Sollbeschleunigung' umzusetzen.";
CM_ SG_ 333 ACC_StartStopp_Info "Freigabe bzw. Startanforderung für Start/Stopp";
CM_ SG_ 333 ACC_Status_ACC "'ACC OFF' bedeutet ACC-Hauptschalter ist 'Gerastet Aus

'ACC Reversibler Fehler' bedeutet, daß das ACC aktuell einen 
reversiblen Fehler im ACC-SG selbst oder in einem zum 
ACC-System gehörenden SG erkennt.

'ACC irreversibler Fehler' bedeutet, daß ";
CM_ SG_ 333 ACC_Tempolimitassistent_Ein "Status ACC-Tempolimitassistent";
CM_ SG_ 333 ACC_Typ "Motor plausibilisiert seine eigene Kodierung";
CM_ SG_ 333 ACC_zul_Regelabw_oben "Anforderung an den Triebstrangkoordinator. Zulässiger Betrag der Abweichung zwischen angeforderter 'ACC_Sollbeschleunigung(_02)' und umzusetzender Sollbeschleunigung  im TSK. Im TSK wird, abhängig vom Arbeitspunkt die Toleranz und die Sollbeschleunigung f";
CM_ SG_ 333 ACC_zul_Regelabw_unten "Anforderung an den Triebstrangkoordinator. Zulässiger Betrag der Abweichung zwischen angeforderter 'ACC_Sollbeschleunigung(_02)' und umzusetzender Sollbeschleunigung  im TSK. Im TSK wird, abhängig vom Arbeitspunkt die Toleranz und die Sollbeschleunigung f";
CM_ SG_ 333 RDR_v_ueber_Grund "Das Signal V_ueber_Grund zeigt die Fahrzeuggeschwindigkeit über Grund in X-Richtung an.
Das Signal wird ausschließlich durch Auswertung von Radarsignalen erzeugt.";
CM_ SG_ 333 RDR_v_ueber_Grund_Fahrtrichtung "Das Signal zeigt die Fahrtrichtung des Fahrzeugs an.  
Das Signal wird ausschließlich durch Auswertung von Radarsignalen erzeugt.";
CM_ SG_ 333 RDR_v_ueber_Grund_Genauigkeit "Das Signal zeigt die Genauigkeit des Geschwindigkeitssignals RDR_v_ueber_Grund im 95%-Konfidenzintervall an.";
CM_ SG_ 333 vESC_Verz_Anf "Die Funktion vorausschauendes ESC fordert eine Verzögerung im VZM.";

CM_ SG_ 2527679682 ACC_ASM_Data_1 "Dieses Signal wird von ACC (LongRangeRadar) befüllt und an den Assistenzsystemmonitor ASM (Host SG: Safety Computer) gesendet.";
CM_ SG_ 2527679682 ACC_ASM_Data_2 "Dieses Signal wird von ACC (LongRangeRadar) befüllt und an den Assistenzsystemmonitor ASM (Host SG: Safety Computer) gesendet.";
CM_ SG_ 2527679682 ACC_ASM_Data_3 "Dieses Signal wird von ACC (LongRangeRadar) befüllt und an den Assistenzsystemmonitor ASM (Host SG: Safety Computer) gesendet.";
CM_ SG_ 2527679682 ACC_ASM_Data_4 "Dieses Signal wird von ACC (LongRangeRadar) befüllt und an den Assistenzsystemmonitor ASM (Host SG: Safety Computer) gesendet.";
CM_ SG_ 2527679682 ACC_ASM_Data_5 "Dieses Signal wird von ACC (LongRangeRadar) befüllt und an den Assistenzsystemmonitor ASM (Host SG: Safety Computer) gesendet.";
CM_ SG_ 2527679682 ACC_ASM_Data_6 "Dieses Signal wird von ACC (LongRangeRadar) befüllt und an den Assistenzsystemmonitor ASM (Host SG: Safety Computer) gesendet.";
CM_ SG_ 2527679682 ACC_ASM_Ereignis "Dieses Signal definiert, welche Funktion und welche Art von Aktivität das Senden der Botschaft an den Assistenzsystemmonitor ASM (Host SG: Safety Computer) veranlasst hat.";
CM_ SG_ 2527679682 ACC_ASM_Zeitstempel "Dieses Signal ermöglicht die zeitliche Zuordnung der von ACC an den Assistenzsystemmonitor ASM (Host SG: Safety Computer) gesendeten Statusbotschaften.";

CM_ SG_ 64 AB_Anzeige_Fussg "Anzeige für ausgelöste Fussgängerschutz-Aktuatorik";
CM_ SG_ 64 AB_Belegung_VF "Belegungserkennung vorne Fahrer.";
CM_ SG_ 64 AB_Belegung_VF_ext "Das Signal kommuniziert den Status des Sitzbelegsensors Fahrer incl. dauerhafter Zustände mit Signalqualität ASIL A.";
CM_ SG_ 64 AB_Crash_Int "Crash_Intensität_1 = fahrzeugabhängige Reaktionen im Crash
Crash_Intensität_2 = fahrzeugabhängige Reaktionen im Crash
Crash_Intensität_3 = fahrzeugabhängige Reaktionen im Crash

Die jeweiligen fahrzeugabhängigen Reaktionen im Crash sind in einem separ";
CM_ SG_ 64 AB_Deaktiviert "Airbag oder Gurtstraffer wurden per Anpassung deaktiviert: Aktualisierung erst nach Selbsttest";
CM_ SG_ 64 AB_Deaktivierung_HV "Deaktivierung des HV-Systems und der HV-Teilnehmer im Crash (u.a. Hybrid- und Elektrofahrzeuge)";
CM_ SG_ 64 AB_Diagnose "Airbag in Diagnose";
CM_ SG_ 64 AB_EDR_Trigger "Triggerbedingung zur dezentralen Aufzeichnung unfallrelevanter Daten im Event Data Recorder";
CM_ SG_ 64 AB_Erh_Auf_VB "Der Fahrer soll bei einem Statuswechsel des Beifahrerairbags (ausgelöst durch die Beifahrerinsassenerkennung oder den Schlüsselschloßschalter) aufmerksam gemacht werden durch eine Anzeige im Kombi. Nur Audi: gültig für: AB2 (4-Türer AU352), B7, C6, D3";
CM_ SG_ 64 AB_Front_Crash "Bit wird bei Überschreitung der Gurtstraffer-, US- und RdW-Schwelle gesetzt";
CM_ SG_ 64 AB_Gurtschloss_FA_ext "Das Ergebnis der Basisfunktion 'Plausibilisierung Gurtschloss' des Verlassenskonzepts wird im Signal dargestellt.";
CM_ SG_ 64 AB_Gurtwarn_VB "Beifahrer hat Gurt nicht gesteckt, Anzeige im Kombi";
CM_ SG_ 64 AB_Gurtwarn_VF "Fahrer hat Gurt nicht gesteckt, Anzeige im Kombi";
CM_ SG_ 64 AB_Heck_Crash "Wird für alle neu anlaufenden Projekte umgesetzt: AB8.4, Audi8/VW8";
CM_ SG_ 64 AB_Lampe "Sicherheitswarnlampe im Kombi wird vom Airbag-SG angesteuert; Zustand der Lampe wird auf dem CAN-Bus ausgegeben (auch Blinkinformation).";
CM_ SG_ 64 AB_MKB_Anforderung "Anforderung Multi-Kollisions-Bremsung";
CM_ SG_ 64 AB_MKB_gueltig "Multi-Kollisions-Bremsung im Airbag freigeschaltet";
CM_ SG_ 64 AB_PAO_Leuchte_Anf "Anforderung an die Passenger-Airbag-Off Leuchte in der Dachkonsole (ein / aus), Einsatz nur bei PAG";
CM_ SG_ 64 AB_RGS_Anst "PreCrash-Ansteuerung reversibler Gurtstraffer (Aktivierung und Kraftniveau)

10xx = deaktiviert";
CM_ SG_ 64 AB_Rollover_Crash "Wird im B6/B7 Cabrio und New Beetle Cabrio bedient. ";
CM_ SG_ 64 AB_SB_Crash "Z.Zt. nur in Verbindung mit Crash-Intensität >= 100b (Kraftstoffpumpenabschaltung) verwendet.
";
CM_ SG_ 64 AB_SF_Crash "Z.Zt. nur in Verbindung mit Crash-Intensität >= 100b (Kraftstoffpumpenabschaltung) verwendet.";
CM_ SG_ 64 AB_Stellgliedtest "Information, ob Airbag im Stellgliedtest ist, um eine Notrufauflösung beim Stellgliedtest zu verhindern";
CM_ SG_ 64 AB_Systemfehler "Systemfehler Ggf. wird Warnlampe dauernd eingeschaltet.";
CM_ SG_ 64 AB_Texte_AKS "Textanzeige für pyrotechnische Auslösung der aktiven Kopfstütze (AKS)";
CM_ SG_ 64 AB_VB_deaktiviert "Als Option vorgehalten, Beifahrerairbag wurden per Schlüsselschalter oder Insassenerkennung deaktiviert";
CM_ SG_ 64 AB_Versorgungsspannung "Übertragung der Plausibilitätsinformation Kl.15-Last vs. Kl.15-CAN.
Bedienung im Fall Kl.15-Last 'EIN' und Kl.15-CAN 'AUS' mit Ausgabe Warnung/Akustik im Kombi.";
CM_ SG_ 64 Airbag_01_CRC "Für MLB:
'Berechnung siehe Lastenheft 'Kommunikationsabsicherung für FlexRay und CAN''

Ab MQB und MLBevo:
'Berechnung siehe Lastenheft 'End-to-End Kommunikationsabsicherung''

Endwerte siehe Begleitdokument 'S-PDU Kennungsfolgen'";
CM_ SG_ 64 ASM_Masterzeit "Masterzeit für alle ASM Sender";

CM_ SG_ 1312 AB_Abschaltanf_SIH_BF "Die Insassenerkennung auf der Beifahrerseite fordert bei Übertemperatur eine Abschaltung der Sitzheizung an. Die Übertemperatur kann bei niederohmigen Nebenschlüssen der Sitzheizungsmatte als Folge von zu hohem resultierenden Strom auftreten.";
CM_ SG_ 1312 AB_Anforderung_eCall "Trigger für Car2X Steuergerät das ein eCall Ereignis erkannt wurde.";
CM_ SG_ 1312 AB_Anforderung_USM "Trigger für Gateway (OBDC) und MIB/MMI, dass ein USM-Ereignis erkannt wurde.";
CM_ SG_ 1312 AB_Anprall_FGS "Uebermittlung der Lage einer Kollision, Fussgaengerschutz-Aktorik";
CM_ SG_ 1312 AB_Anprall_Front_Beifahrer "Uebermittlung der Lage einer Kollision, Anprallzone Beifahrerseite vorne";
CM_ SG_ 1312 AB_Anprall_Front_Fahrer "Uebermittlung der Lage einer Kollision, Anprallzone Fahrerseite vorne";
CM_ SG_ 1312 AB_Anprall_Heck_Beifahrer "Uebermittlung der Lage einer Kollision, Anprallzone Beifahrerseite hinten";
CM_ SG_ 1312 AB_Anprall_Heck_Fahrer "Uebermittlung der Lage einer Kollision, Anprallzone Fahrerseite hinten";
CM_ SG_ 1312 AB_Anprall_Rollover "Uebermittlung der Lage einer Kollision, Rollover erkannt";
CM_ SG_ 1312 AB_Anprall_Seite_Beifahrer "Uebermittlung der Lage einer Kollision, Anprallzone Beifahrerseite Seite";
CM_ SG_ 1312 AB_Anprall_Seite_Fahrer "Uebermittlung der Lage einer Kollision, Anprallzone Fahrerseite Seite";
CM_ SG_ 1312 AB_Belegung_VB "Belegungserkennung vorne Beifahrer. Wird in US-Steuergeräten über Bladder-Matte bedient, optional bei RdW, falls SBE_EuroNCAP entschieden wird.";
CM_ SG_ 1312 AB_Crashschwere "Übermittlung der Crashschwere an das Gateway (OBDC)";
CM_ SG_ 1312 AB_Gurtschloss_BF "Gurtschlossstatus Beifahrerseite";
CM_ SG_ 1312 AB_Gurtschloss_FA "Gurtschlosstatatus Fahrerseite";
CM_ SG_ 1312 AB_Gurtschloss_Reihe2_BF "Gurtschlossstatus 2. Reihe Beifahrerseite,  Mehrausstattung";
CM_ SG_ 1312 AB_Gurtschloss_Reihe2_FA "Gurtschlossstatus 2. Reihe Fahrerseite, Mehrausstattung";
CM_ SG_ 1312 AB_Gurtschloss_Reihe2_MI "Gurtschlossstatus 2. Reihe Mitte,  Mehrausstattung";
CM_ SG_ 1312 AB_Gurtschloss_Reihe3_BF "Gurtschlossstatus 3. Reihe Beifahrerseite,  Mehrausstattung";
CM_ SG_ 1312 AB_Gurtschloss_Reihe3_FA "Gurtschlossstatus 3. Reihe Fahrerseite,  Mehrausstattung";
CM_ SG_ 1312 AB_Gurtschloss_Reihe3_MI "Gurtschlossstatus 3. Reihe Mitte,  Mehrausstattung";
CM_ SG_ 1312 AB_Sitzpos_Sens_BF "Ausgabe Sitzposition Beifahrer";
CM_ SG_ 1312 AB_Sitzpos_Sens_FA "Ausgabe Sitzposition Fahrer";
CM_ SG_ 1312 AB_Wickelklappung_Reihe2_BF "Status Wickelklappung 2. Reihe Beifahrerseite, Mehrausstattung";
CM_ SG_ 1312 AB_Wickelklappung_Reihe2_FA "Status Wickelklappung 2. Reihe Fahrerseite, Mehrausstattung";
CM_ SG_ 1312 AB_Wickelklappung_Reihe2_MI "Status Wickelklappung 2. Reihe Mitte, Mehrausstattung";
CM_ SG_ 1312 Airbag_02_CRC "Für MLB:
'Berechnung siehe Lastenheft 'Kommunikationsabsicherung für FlexRay und CAN''

Ab MQB und MLBevo:
'Berechnung siehe Lastenheft 'End-to-End Kommunikationsabsicherung''

Endwerte siehe Begleitdokument 'S-PDU Kennungsfolgen'";
CM_ SG_ 1312 LoGeWa_Event_Kombiwarnung "Event für Kombiwarnung";
CM_ SG_ 1312 SC_PAO_OFF_Anf "Sollwert für LED 'OFF' in Anzeige Passenger Airbag On/Off";
CM_ SG_ 1312 SC_PAO_ON_Anf "Sollwert für LED 'ON' in Anzeige Passenger Airbag On/Off";
CM_ SG_ 1312 SC_PAO_Schriftzug_Anf "Sollwert für LED 'PASSENGER AIRBAG' in Anzeige Passenger Airbag On/Off";

CM_ SG_ 65 AB_MKB_Safing "Safing für Multi-Kollisions-Bremsung";
CM_ SG_ 65 Airbag_03_CRC "Für MLB:
'Berechnung siehe Lastenheft 'Kommunikationsabsicherung für FlexRay und CAN''

Ab MQB und MLBevo:
'Berechnung siehe Lastenheft 'End-to-End Kommunikationsabsicherung''

Endwerte siehe Begleitdokument 'S-PDU Kennungsfolgen'";

CM_ SG_ 1349 AB_Gurtwarn_Reihe2_BF "Status Gurtwarnung 2. Sitzreihe Beifahrerseite";
CM_ SG_ 1349 AB_Gurtwarn_Reihe2_FA "Status Gurtwarnung 2. Sitzreihe Fahrerseite";
CM_ SG_ 1349 AB_Gurtwarn_Reihe2_MI "Status Gurtwarnung 2. Sitzreihe Mitte";
CM_ SG_ 1349 AB_Gurtwarn_Reihe3_BF "Status Gurtwarnung 3. Sitzreihe Beifahrerseite";
CM_ SG_ 1349 AB_Gurtwarn_Reihe3_FA "Status Gurtwarnung 3. Sitzreihe Fahrerseite";
CM_ SG_ 1349 AB_Gurtwarn_Reihe3_MI "Status Gurtwarnung 3. Sitzreihe Mitte";
CM_ SG_ 1349 AB_Gurtwarn_Reihe4_BF "Status Gurtwarnung 4. Sitzreihe Beifahrerseite";
CM_ SG_ 1349 AB_Gurtwarn_Reihe4_FA "Status Gurtwarnung 4. Sitzreihe Fahrerseite";
CM_ SG_ 1349 AB_Gurtwarn_Reihe4_MI "Status Gurtwarnung 4. Sitzreihe Mitte";
CM_ SG_ 1349 AB_SBR_hinten_verbau "Verbauinformation Sitzbelegungssensor hinten (2. und 3. Sitzreihe)";
CM_ SG_ 1349 AbstWarn_MV_FAS_Fkt_Status "FAS-ProfileMaster Iststatus der Kundenfunktion";
CM_ SG_ 1349 AWV_Einstellung_System_ASG "Signal zur Realisierung des BAP-Koordinators";
CM_ SG_ 1349 AWV_Einstellung_Warnung_ASG "Signal zur Realisierung des BAP-Koordinators";
CM_ SG_ 1349 LGI_FAS_Fkt_Status "FAS-ProfileMaster Iststatus der Kundenfunktion (LGI: Lokale Gefahreninformation)";
CM_ SG_ 1349 PreCrash_FAS_Fkt_Status "FAS-ProfileMaster Iststatus der Kundenfunktion";
CM_ SG_ 1349 SC_PreSense_Modus_System_KAS "BAP-Kommunikation zum Kreuzungsassistent";
CM_ SG_ 1349 SC_PreSense_Modus_System_MV "Signal zur Realisierung der BAP-Kommunikation für PreSense";
CM_ SG_ 1349 SC_PreSense_Modus_System_NV "Signal zur Realisierung der BAP-Kommunikation für PreSense";
CM_ SG_ 1349 SC_PreSense_Modus_Warnung_MV "Signal zur Realisierung der BAP-Kommunikation für PreSense";
CM_ SG_ 1349 SC_PreSense_Modus_Warnung_NV "Signal zur Realisierung der BAP-Kommunikation für PreSense";
CM_ SG_ 1349 WarnBrems_Charisma_FahrPr "Aktuell eingestelltes Fahrprogramm der Funktion Warn- und/oder Notbremsfunktion";
CM_ SG_ 1349 WarnBrems_Charisma_Status "Verfügbarkeit der Funktion Warn- und/oder Notbremsfunktion für die Ansteuerung durch den Charisma-Koordinator.";

CM_ SG_ 2527679722 AB_Gurtschloss_Reihe4_BF "Gurtschlossstatus 4. Reihe Beifahrerseite,  Mehrausstattung";
CM_ SG_ 2527679722 AB_Gurtschloss_Reihe4_FA "Gurtschlossstatus 4. Reihe Fahrerseite, Mehrausstattung";
CM_ SG_ 2527679722 AB_Gurtschloss_Reihe4_MI "Gurtschlossstatus 4. Reihe Mitte,  Mehrausstattung";

CM_ SG_ 1633 AAG_Anhaenger_abgesteckt "Anhaenger wurde bei Kl. 15 aus abgesteckt";
CM_ SG_ 1633 AAG_Anhaenger_erkannt "Erkennung Anhaenger ";
CM_ SG_ 1633 AAG_AVS_Fehler_02 "Fehler AVS";
CM_ SG_ 1633 AAG_AVS_Fehler_02_inv "Fehler AVS (inverses Signal)";
CM_ SG_ 1633 AAG_AVS_Stati "Status AVS (bei abnehmbarer oder mech.schwenkbarer Anhängerkupplung ist der Status immer 0)
";
CM_ SG_ 1633 AAG_Blinker_H_aktiv "Status: Anhaenger Blinker aktiv";
CM_ SG_ 1633 AAG_Blinker_HL_def "Anhaenger Blinker links defekt";
CM_ SG_ 1633 AAG_Blinker_HR_def "Anhaenger Blinker rechts defekt";
CM_ SG_ 1633 AAG_Bremsl_durch_ECD "Bremslicht durch ECD aktiv";
CM_ SG_ 1633 AAG_Bremslicht_H_def "Anhaenger Bremslicht defekt";
CM_ SG_ 1633 AAG_Bremslicht_Reku "AAG_Bremslicht_Reku meldet zyklisch den empfangenen Zustand des CAN-Signals MO_Bremslicht_Reku zurück.";
CM_ SG_ 1633 AAG_BZ "4bit-Botschaftszaehler, wird in jeder Sendebotschaft inkrementiert

";
CM_ SG_ 1633 AAG_LED_aktiv "Dieses Signal sendet der Beleuchtungsart des Anhängers (LED oder Lampe)
Bei LED aktiv erfolgt kein Kaltüberwachung";
CM_ SG_ 1633 AAG_NSL_aktiv "Anhaenger Nebelschlusslicht aktiv";
CM_ SG_ 1633 AAG_Schlusslicht_HL_def "Anhaenger Schlußlicht links defekt";
CM_ SG_ 1633 AAG_Schlusslicht_HR_def "Anhaenger Schlußlicht rechts defekt";

CM_ SG_ 345 ARA_Aktiver_Grafikmodus "Zeigt an  das eine Grafik für ARA aktiviert werden soll";
CM_ SG_ 345 ARA_Anf_Meldungen "Anforderung der Meldungen:
0 - Keine Meldung
1-127 niederprio. Meldungen
128-255 hochprio. Meldungen";
CM_ SG_ 345 ARA_Bremsfuss "Anforderung des Bremsfusssymbols im Kombi";
CM_ SG_ 345 ARA_Deaktivierung_sperren "Unterdrückt die Deaktivierung der ARA- Visualisierung";
CM_ SG_ 345 ARA_Knickwinkel_Ist "Gibt den aktuellen Knickwinkel zwischen Anhänger und Fahrzeug wieder";
CM_ SG_ 345 ARA_Knickwinkel_Komfort "Knickwinkelgrenze bis zu der, bei maximalem Lenkeinschlag, eine sofortige gerade Rückwärtsfahrt möglich ist.";
CM_ SG_ 345 ARA_Knickwinkel_konfidenz "Gibt einen Unschärfewinkel zur Darstellung der Visiualisierung in der RV-Ansicht bei Notregelung an";
CM_ SG_ 345 ARA_Knickwinkel_Max "Gibt den maximalen ausregelbaren Knickwinkel zwischen Anhänger und Fahrzeug wieder.";
CM_ SG_ 345 ARA_Knickwinkel_Soll "Vom Fahrer vorgegebener Knickwinkel.";
CM_ SG_ 345 ARA_Modus "Regelmodus ARA für Kombidarstellung";
CM_ SG_ 345 ARA_Modus_Anf "Anforderung des ARA-Modus im Türsteuergerät";
CM_ SG_ 345 ARA_Sensor_Aktivierung "Anforderung der Aktivierung des Knickwinkelsensors.";
CM_ SG_ 345 ARA_Status "Gibt den Status des ARA wieder";
CM_ SG_ 345 ARA_Texte "Anforderung für Kombianzeigetexte und Akustik";

CM_ SG_ 2589283607 AWC_01_BZ "Fortlaufender Botschaftszaehler";
CM_ SG_ 2589283607 AWC_01_CRC "Für MLB:
'Berechnung siehe Lastenheft 'Kommunikationsabsicherung für FlexRay und CAN''

Ab MQB und MLBevo:
'Berechnung siehe Lastenheft 'End-to-End Kommunikationsabsicherung''

Endwerte siehe Begleitdokument 'S-PDU Kennungsfolgen'";
CM_ SG_ 2589283607 AWC_Fehlerstatus "aktueller Fehlerstatus des Ladegerätes
0: Komponente IO (keine HVK relevanter Fehler)
1: Eingeschränkte_Komponentenfunktion AWC Laden nicht möglich
2: reserve
3: Eingeschr_Komponentenfunktion aufgrund HV-Interlock-Fehler (nur wenn LHVIL)
4- 5: reserv";
CM_ SG_ 2589283607 AWC_IstModus "momentaner AWC -Lademodus, d.h. aktueller Zustand der Energieübertragung (inaktiv, aktiv, verzögert oder deaktiviert)";
CM_ SG_ 2589283607 AWC_IstSpannung "Ausgangsspannung AWC Lader";
CM_ SG_ 2589283607 AWC_IstStrom "Ausgangsstrom AWC";
CM_ SG_ 2589283607 AWC_MaxLadLeistung "Maximale Leistung AWC-Ladegerät bezogen auf die maximale Leistung AWC-Infrastruktur (Kabel, Ladestation) und Berücksichtigung des AWC-Ladegerät-Wirkungsgrades";
CM_ SG_ 2589283607 AWC_Status_EoHVL "Erkennung einer offenen HV-Leitung (EoHVL), bewertet anhand einer Spannungsgrenze";
CM_ SG_ 2589283607 AWC_Status_Spgfreiheit "Information über Spannungsfreiheit der HV-Komponenten für Diagnose und Kundendienst.";

CM_ SG_ 219 AWV_03_BZ "4bit Botschaftszähler, wird mit jeder Sendebotschaft inkrementiert";
CM_ SG_ 219 AWV_03_CRC "Für MLB:
Berechnung siehe Lastenheft 'Kommunikationsabsicherung für FlexRay und CAN'
Ab MQB und MLBevo:
Berechnung siehe Lastenheft 'End-to-End Kommunikationsabsicherung'

Endwerte siehe Begleitdokument 'S-PDU Kennungsfolgen'";
CM_ SG_ 219 AWV_Anf_Prefill "Anforderung an VZM, dass die Prefill-Funktion aktiviert werden soll.";
CM_ SG_ 219 AWV_Eingriff_Sendeart "Umschalten zwischen langsamem und schnellem Zyklus der AWV_Eingriffs-Botschaft";
CM_ SG_ 219 AWV_HBA_Param "Anforderung an HBA zur Anpassung der HBA-Auslöseschwelle.";
CM_ SG_ 219 AWV_QFK_AnfStat "Statusinformationen des Anforderers";
CM_ SG_ 219 AWV_QFK_Art1 "Auswahlsignal für AWV_QFK_Signal1";
CM_ SG_ 219 AWV_QFK_Art2 "Auswahlsignal für AWV_QFK_Signal2";
CM_ SG_ 219 AWV_QFK_KruemmSoll "Krümmungsanforderung";
CM_ SG_ 219 AWV_QFK_KruemmSoll_VZ "Vorzeichen für die Krümmungsanforderung";
CM_ SG_ 219 AWV_QFK_Signal1 "Inhalt AWV_QFK_Signal1 wird durch das Signal AWV_QFK_Art1 gesteuert.
Nähere Informationen im LAH Querführungskoordinator.";
CM_ SG_ 219 AWV_QFK_Signal2 "Inhalt AWV_QFK_Signal2 wird durch das Signal AWV_QFK_Art2 gesteuert.
Nähere Informationen im LAH Querführungskoordinator.";
CM_ SG_ 219 AWV_QFK_Spuerb "Spürbarkeitsanforderung. Legt fest, mit welchem Handmoment die angeforderte Krümmung überlenkt werden muss.";
CM_ SG_ 219 AWV_Ruckprofil "Anforderung an VZM, welcher Ruck aus einer Auswahl von max. 7 verschiedenen Ruckprofilen verwendet werden soll.";
CM_ SG_ 219 AWV_Time_to_brake "Zeit in Millisekunden bs zu einer AWV Verzögerungsanforderung (ATB oder ZBR)";
CM_ SG_ 219 AWV_Time_to_collision "Prädizierter Aufprallzeitpunkt des relevanten Objektes aus der AWV-Funktion";
CM_ SG_ 219 AWV_Verz_Anf "Verzögerungsanforderung der Funktionen Zielbremsung und Teilbremsung an das VZM";
CM_ SG_ 219 AWV_Verz_Anf_ASIL "Definiert das Anforderungssignal von FKT an VZM mit dem dynamischen ASIL";
CM_ SG_ 219 AWV_Verz_Freigabe "Freigabe-Bit der AWV Verzögerung an das VZM";
CM_ SG_ 219 AWV_Zielobjekttyp "Definiert den Zielobjekttyp an VZM";
CM_ SG_ 219 PCF_Freigabe "Freigabe der Funktion PreCrash-Front";
CM_ SG_ 219 SDF_PSF_CU_Status "Kollisionsvermeidbarkeit";
CM_ SG_ 219 SDF_PSF_CW "Kollisionswahrscheinlichkeit";
CM_ SG_ 219 SDF_PSF_Fahrer_aktiv "Fahreraktivität";
CM_ SG_ 219 SDF_PSF_Guete "Guete des Objektes";
CM_ SG_ 219 SDF_PSF_Kollisionsueberdeckung "Kollisionsueberdeckung in y-Richtung";
CM_ SG_ 219 SDF_PSF_Objektstatus "Objektstatus";
CM_ SG_ 219 SDF_PSF_Time_To_Collision "Zeit bis zur Kollision";
CM_ SG_ 219 SDF_PSF_v_rel "Prädizierte Aufprallgeschwindigkeit";

CM_ SG_ 2536717313 BAP_EfficAssist_ASG_02_Header "EfficiencyAssist Anzeigesteuergeraet 2";

CM_ SG_ 2536717314 BAP_EfficAssist_ASG_03_Header "BAP Data dummy";

CM_ SG_ 2536717328 BAP_EfficAssist_FSG_01_Header "BAP dummy data";

CM_ SG_ 869 BEM_01_Abschaltstufen "Signal inhaltlich identisch mit BEM_02_Abschaltstufen. Namentliche Umbenennung wegen Standard-SW im Gateway-BEM im MLB (Handling gleicher Signalnamen im Source-Code).
Abschaltstufen des Ruhestrommanagements 
(Initialisierungswert aus EEPROM)";
CM_ SG_ 869 BEM_Anf_KL "Es gilt: Signalspec BEM_Anf_KL v1.1
Das BEM fordert über das MSG den Kühlerlüfter-Betrieb an; hierzu wird ein minimaler Leistungswert im MSG appliziert. 
Szenario: bei erkannter abgetrennten Batterie soll durch Ansteuerung des Kühlerlüfters das Energien";
CM_ SG_ 869 BEM_Batt_Ab "Batterieverbindungskontrolle:
0x0: Batterie am Bordnetz
0x1: Batterie ab erkannt";
CM_ SG_ 869 BEM_DFM "Generatorauslastungsgrad, vom Generator über LIN an das Gateway gesandt. Das Motorsteuergerät regelt auf dieses Signal die PTC, das Energiemanagement im BSG/BCM kalkuliert die Bordnetzauslastung";
CM_ SG_ 869 BEM_EMLIN_ungueltig "Energie-Lin - Signale sind ungültig vom Slave Batteriedatenmodul oder Generator
0 = Signale gültig
1 = Signale ungültig";
CM_ SG_ 869 BEM_HYB_DC_uMinLV "Abregelgrenze: minimal erlaubte Bordnetzspannung im Hochsetzbetrieb (Hybrid)";
CM_ SG_ 869 BEM_HYB_DC_uSollLV "Sollwert für die Bordnetzspannung im Tiefsetzbetrieb vom Traktionsnetz ins Bordnetz (Hybrid)";
CM_ SG_ 869 BEM_n_LLA "Es gilt: Signalspec BEM_n_LLA v1.0

Anforderung einer Leerlaufdrehzahlanhebung in drei Stufen. Die Höhe der jeweiligen LL-Drehzahlstufe ist im Motorsteuergerät appliziert.



";
CM_ SG_ 869 BEM_NV_NachladAnf "Bei Energiedefizit auf der Niedervoltseite wird der Lademanager aufgefordert, die Niedervoltseite nachzuladen.";
CM_ SG_ 869 BEM_P_Generator "Es gilt: Signalspec BEM_P_Generator v1.0

Mechanische Generatorleistung dient dem Motorsteuergerät zur Berechnung der Motorlast; Genauigkeit ca. +/- (500W + 20% vom Messwert)

MLBevo: Bei NVEM_P_Generator_Status = 1 wird das Signal ohne Filterung ausg";
CM_ SG_ 869 BEM_Segel_Info "0: keine Anforderung 
(Segeln ist ohne Einschänkung erlaubt)
1: Mindestdrehzahl 1 
(Segeln ist mit Einschänkung erlaubt)
2: Mindestdrehzahl 2
(Segeln ist mit Einschänkung erlaubt)
3: Segelveto
(Segeln ist nicht  erlaubt)";
CM_ SG_ 869 BEM_StartStopp_Info "Stopp-Freigabe und Start-Anforderung an den Start-Stopp-Koordinator";
CM_ SG_ 869 BEM_UBDM "Batteriespannung, gemessen vom Batteriedatenmodul";
CM_ SG_ 869 NVEM_FMAus_I_Verbrauch "Predezierter Bordneztstromverbrauch während der Freilauf Motor Aus Phase.";
CM_ SG_ 869 NVEM_FMAus_Info "Freilauf Informationssignal zum Freilaufkoordinator. 
Gilt nur für die Freilauf Phase. Verwendung im MicroHybrid.";
CM_ SG_ 869 NVEM_Freilauf_Info "Freilauf Informationssignal vom NVEM zum Freilaufkoordinator. Das NVEM kann über dieses Signal den Freilauf freigeben, verhindern bzw. explizit anfordern.";
CM_ SG_ 869 NVEM_Ladefreigabe "Freigabeemfehlung zur Ladung des FMA-Zusatzspeichers";
CM_ SG_ 869 NVEM_P_Generator_Status "Das Signal kennzeichnet ob BEM_P_Generator aktuell gefilterte oder ungefilterte Werte überträgt.";
CM_ SG_ 869 NVEM_PTC_Sollstufe "Vorgabe des BEM an das BCM zur Aktivierung der geforderten PTC - Stufe.
Das MSG kopiert dies auf das Signal MO_PTC_Status";

CM_ SG_ 1442 BMS_04_CRC "Für MLB:
'Berechnung siehe Lastenheft 'Kommunikationsabsicherung für FlexRay und CAN''

Ab MQB und MLBevo:
'Berechnung siehe Lastenheft 'End-to-End Kommunikationsabsicherung''

Endwerte siehe Begleitdokument 'S-PDU Kennungsfolgen'";
CM_ SG_ 1442 BMS_Fehler_Pilot "Signalisiert den Status der Pilotlinie BMS.";
CM_ SG_ 1442 BMS_Fehlerlampe_Anf "Anforderung der roten Hybrid-Warnlampe im Kombi";
CM_ SG_ 1442 BMS_Fehlerstatus "aktueller Fehlerstatus der Batterie";
CM_ SG_ 1442 BMS_Kapazitaet_02 "Nutzbare Kapazität der Batterie,
oder alterungsabhängige absolute Gesamtkapazität der Batterie.

Projektabhängig kann die Kapazität auf das nutzbare SOC-Fenster (zwischen oberer und unterer SOC-Grenze) bezogen sein, wobei sich dieses SOC-Fenster alteru";
CM_ SG_ 1442 BMS_Kl30c_Status "Stecker-Zustand des Service-Disconnect (Klemme 30c)";
CM_ SG_ 1442 BMS_OBD_Lampe_Anf "Anforderung MIL (MalfunctionIndicationLamp) von BMS (Motorsteuergerät reicht diese Info an Kombi weiter).";
CM_ SG_ 1442 BMS_Status_ServiceDisconnect "Status des Service Disconnect, ob dieser gesteckt oder gezogen ist.
Abhängigkeiten zu anderen Signalen: BMS_Fehler_Sicherung und BMS_Fehler_Pilot";
CM_ SG_ 1442 BMS_Status_Spgfreiheit "0=Init (ohne Funktion)
1=BMS Zwischenkreis spannungsfrei (U_Zwkr < 20V)
2=BMS Zwischenkreis nicht spannungsfrei (U_Zwkr >/= 25V, Hysterese)
3=Fehler (z.B. Fehler in der Sensorik)";
CM_ SG_ 1442 BMS_Warnlampe_Anf "Anforderung der gelben Hybrid-Warnlampe im Kombi";

CM_ SG_ 2527679654 BMS_11_BZ "4bit Botschaftszähler, wird mit jeder Sendebotschaft inkrementiert";
CM_ SG_ 2527679654 BMS_11_CRC "Für MLB:
Berechnung siehe Lastenheft 'Kommunikationsabsicherung für FlexRay und CAN'
Ab MQB und MLBevo:
Berechnung siehe Lastenheft 'End-to-End Kommunikationsabsicherung'

Endwerte siehe Begleitdokument 'S-PDU Kennungsfolgen'";
CM_ SG_ 2527679654 BMS_IsoFehler "Ergebnis der Isolationsmessung des BMS";
CM_ SG_ 2527679654 BMS_IsoZustand "Ergebnis des aktuellen/letzten Isolations-Meßzyklus: Messung läuft; Messung Batterie-intern oder Gesamtsystem; gemessener Wert unterschreitet Schwelle 1 / Schwelle 2.";
CM_ SG_ 2527679654 BMS_IstTemperatur_hoechste "aktuell höchste Temperatur in der Batterie";
CM_ SG_ 2527679654 BMS_IstTemperatur_niedrigste "aktuell niedrigsteTemperatur in der Batterie";
CM_ SG_ 2527679654 BMS_IstZellspannung_hoechste "höchster Wert aller Zellspannungen im BMS";
CM_ SG_ 2527679654 BMS_IstZellspannung_niedrigste "niedrigster Wert aller Zellspannungen im BMS";

CM_ SG_ 207 BMS_20_BZ "4bit Botschaftszähler, wird mit jeder Sendebotschaft inkrementiert";
CM_ SG_ 207 BMS_20_CRC "Für MLB:
Berechnung siehe Lastenheft 'Kommunikationsabsicherung für FlexRay und CAN'
Ab MQB und MLBevo:
Berechnung siehe Lastenheft 'End-to-End Kommunikationsabsicherung'

Endwerte siehe Begleitdokument 'S-PDU Kennungsfolgen'";
CM_ SG_ 207 BMS_ErwGrenzen_aktiv "die aktuellen Stromgrenzen der HV-Batterie sind zum Start des Verbrennungsmotors aufgeweitet / Bestätigung der Anforderung";
CM_ SG_ 207 BMS_Fehler_HVBattAbschaltung "Fehler: Fehlerzustand, erfordert das Öffnen der Batterieschütze
interner Batteriefehler, Batterieschütze ohne Vorankündigung durch das BMS geöffnet";
CM_ SG_ 207 BMS_Fehler_HVBattAbschaltung_Anf "Fehler: Fehlerzustand, erfordert das Öffnen der Batterieschütze
interner Batteriefehler; Vorankündigung eines bevorstehenden Öffnens der Batterieschütze durch das BMS";
CM_ SG_ 207 BMS_Fehler_Leistungsred "Fehler: Leistungsfähigkeit der Batterie ist eingeschränkt (z.B. aufgrund des Ausfalls von Sensoren oder des Lüfters)";
CM_ SG_ 207 BMS_Fehler_Notabschaltung_Crash "Fehler: Sicherheitskritischer Fehler (Crash-Erkennung)
Batterieschütze sind bereits geöffnet / werden sofort geöffnet
Signal wird direkt vom EMS gelesen und initiiert einen AKS des PWR und eine aktive Entladung des Zwischenkreises";
CM_ SG_ 207 BMS_Fehlerstatus_HV_Schuetze "Fehlerstatus der HV-Schütze, Verschweißt-Erkennung";
CM_ SG_ 207 BMS_HVIL_Status "Signalstatus HVIL/Pilotlinie";
CM_ SG_ 207 BMS_IstModus "Aktueller Betriebsmodus der Batterie
0: Standby; Schuetze geoeffnet; Kommunikation aktiv
1: Hauptschuetze geschlossen / HV-Netz aktiviert / normaler Fahrbetrieb
2: projektabhaengig belegt (z.B. Balancing, erweitertes DC-Schnelladen)
3: externes Laden ";
CM_ SG_ 207 BMS_Spannung "Aktuelle Spannung der Batterie.
Innerhalb der Batterie an den Zellmodulen gemessen, also _vor_ den Schützen und der Sicherung.";
CM_ SG_ 207 BMS_Spannung_Zwischenkreis "Aktuelle Spannung an den Batterie-HV-Anschlüssen; Abgang der Batterie zum Zwischenkreis / HV-Bordnetz / zur Leistungselektronik.";
CM_ SG_ 207 BMS_Strom "Aktueller Strom der Batterie.
Stromrichtung: Ladestrom wird mit positiven, Entladestrom mit negativen Werten angegeben.";

CM_ SG_ 2463978704 BMS_Max_Entladeleistung "Maximale Leistung, mit der die Batterie momentan belastet werden darf. 
Kurze Überschwinger aufgrund dynamischen Verhalten des Reglers sind nach Absprache möglich, aber
hierbei muss unbedingt auch der maximale Entladestrom berücksichtigt werden.";
CM_ SG_ 2463978704 BMS_Max_Entladestrom "Zwingend einzuhaltender Grenzwert für den Entladestrom der Batterie.
Darf aus Bauteilschutzgründen nicht überschritten werden.
Aus Lebensdauersicht muss zusätzlich die Leistungsgrenze eingehalten werden.";
CM_ SG_ 2463978704 BMS_Max_Ladeleistung "Maximale Leistung, mit der die Batterie aktuell geladen werden darf. 
Kurze Überschwinger aufgrund dynamischen Verhalten des Reglers sind nach Absprache möglich, aber
hierbei muss unbedingt auch der maximale Ladestrom berücksichtigt werden.";
CM_ SG_ 2463978704 BMS_Max_Ladestrom "Zwingend einzuhaltender Grenzwert für den Ladestrom der Batterie.
Darf aus Bauteilschutzgründen nicht überschritten werden.
Aus Lebensdauersicht muss zusätzlich die Leistungs- und SOC-Grenze eingehalten werden.";

CM_ SG_ 2463978705 BMS_Ladezustand "Aktueller Ladezustand (SOC) der Batterie. 
Es handelt sich NICHT um den dem Fahrer angezeigten Füllstand der Batterie, sondern um den technisch ermittelten, batterie-internen Ladezustand, bezogen auf die Brutto-Kapazität der Batterie.";
CM_ SG_ 2463978705 BMS_Nutzbare_EntladeEnergie "Aktuelle, verbleibende Energiemenge, die noch aus der Batterie entladen werden kann.
Diese hängt in erster Linie vom aktuellen Ladezustand der Batterie ab.

Projektabhängig kann die Energiemenge noch vom variablen SOC-Fenster, dem Alterungszustand, dem";
CM_ SG_ 2463978705 BMS_PerfInd_Entladen "Leistungsindikation in Entladerichtung.
Der Bereich 100...200% beschreibt die verbleibende Reserve, bis ein Derating der maximalen Entladeleistungsgrenze eintritt.
Werte von 0 bis 100% beschreiben, auf welchen Teil der potentiell möglichen maximalen Ent";
CM_ SG_ 2463978705 BMS_PerfInd_Laden "Leistungsindikation in Laderichtung.
Der Bereich 100...200% beschreibt die verbleibende Reserve, bis ein Derating der maximalen Ladeleistungsgrenze eintritt.
Werte von 0 bis 100% beschreiben, auf welchen Teil der potentiell möglichen maximalen Ladeleist";
CM_ SG_ 2463978705 BMS_Status_EoHVL_Heizer "Status Erkennung offener HV-Leitung (EoHVL) / offene Steckverbindung zum HV-Batterieheizer (PTC):
0=Init
1=Keine offene HV-Leitung erkannt
2=offene HV-Leitung erkannt
3=Fehler";

CM_ SG_ 2589283664 BMS_Balancing_Aktiv "Signal zeigt an, ob mindestens eine Zelle der HV Batterie balanciert wird";
CM_ SG_ 2589283664 BMS_Ladevorgang_aktiv "Signalisiert aktiven Ladevorgang, Ladegerät und DC/DC aktiv.
Signal bleibt nach Kl.15 ein aktiv, bis ESP_Stillstandsflag gelöscht.

Abhängigkeit zu BMS_Energieinhalt";
CM_ SG_ 2589283664 BMS_Max_Energie "Nutzbarer maximaler Entlade-Energieinhalt der vollgeladenen Batterie. 

Projektabhängig kann der Energiewert vom variablen SOC-Fenster (zwischen oberer und unterer SOC-Grenze), dem Alterungszustand, dem aktuellen Lastprofil sowie der Temperatur abhängen";
CM_ SG_ 2589283664 BMS_Max_Ladezustand "Obere Ladezustandsgrenze für das SOC-Fenster in der Betriebsstrategie. 
Der Wert kann sich über Lebensdauer und Alterung des Batteriesystems ändern; 
Erreicht der Wert 'BMS_Ladezustand' den hier übertragenen Wert, darf die Batterie nicht weiter geladen ";
CM_ SG_ 2589283664 BMS_Min_Ladezustand "Untere Ladezustandsgrenze für das SOC-Fenster in der Betriebsstrategie. 
Der Wert kann sich über Lebensdauer und Alterung des Batteriesystems ändern; 
Erreicht der Wert 'BMS_Ladezustand' nach unten hin den hier übertragenen Wert, darf die Batterie nicht";
CM_ SG_ 2589283664 BMS_RIso_Ext "Minimum des Isolationswiderstands zwischen Batteriegehäuse und HV+ bzw. Batteriegehäuse und HV- bei geschlossenen Schützen (externe Iso Messung)";

CM_ SG_ 2589283665 BMS_BattHeizung_VerbautStatus "Verbausignalisierung der optionalen HV-Batterieheizung";
CM_ SG_ 2589283665 BMS_Fehler_NTKreis "Fehler im NTKreis, HV-Batterie wird nicht klimatisiert
(Fehler, Fehlerfrei) ";
CM_ SG_ 2589283665 BMS_Pumpe1_Ansteuerung "Ansteuerung der Batterie-Kühlmittelpumpe.
0% = Pumpe abgeschaltet
100% = Pumpe maximal angesteuert";
CM_ SG_ 2589283665 BMS_Pumpe2_Ansteuerung "Ansteuerung einer zweiten Kühlmittelpumpe.
Projektabhängig für Systeme, die seitens Batterie zwei Pumpen ansteuern.
0% = Pumpe abgeschaltet
100% = Pumpe maximal angesteuert";
CM_ SG_ 2589283665 BMS_RuecklaufTemperatur "Aktueller Messwert der Kühlmittel-Rücklauftemperatur
am Kühlmittel-Auslass des Batteriesystems.";
CM_ SG_ 2589283665 BMS_SollVorlauftemperatur "Soll_Vorlauftemperatur_Kühlmedium in °C";
CM_ SG_ 2589283665 BMS_Status_Ventil1 "Status Ventil; wassergekühltes Batteriesystem.
Batteriekreis-Absperrventil.

nicht-angesteuert = Batterie im kleinen Kühlkreislauf, abgetrennt vom restlichen Kühlsystem
angesteuert = Batterie eingeschleift in großen Kühlkreislauf (Niedertemperatur-Küh";
CM_ SG_ 2589283665 BMS_Status_Ventil2 "Status des zweiten Ventils; wassergekühltes Batteriesystem.
Für Systeme, wo die Batterie ein zweites Ventil ansteuert.
Belegung projektabhängig.

nicht-angesteuert = großer Kühlkreislauf (Niedertemperatur-Kühlkreis) abgetrennt vom Batteriesystem oder ";
CM_ SG_ 2589283665 BMS_Temperatur "battery temperature / Momentanwert: Temperatur der Traktionsbatterie";
CM_ SG_ 2589283665 BMS_Temperierung_Anf "Temperierungsbedarf der HV-Batterie";
CM_ SG_ 2589283665 BMS_VorlaufTemperatur "Aktueller Messwert der Kühlmittel-Vorlauftemperatur
am Kühlmittel-Einlass des Batteriesystems.";

CM_ SG_ 2589283760 BMS_Dauer_Entladeleistung "ist die aktuelle Dauer-Leistungsfähigkeit der Batterie. 
Wenn dieser Wert überschritten wird, kann ein zeitliches Derating der maximalen Leistungsgrenzen stattfindet. Die Dauerleistung ändert sich mit Batterietemperatur und Ladezustand.";
CM_ SG_ 2589283760 BMS_Dauer_Ladeleistung "ist die aktuelle Dauer-Leistungsfähigkeit der Batterie. 
Wenn dieser Wert überschritten wird, kann ein zeitliches Derating der maximalen Leistungsgrenzen stattfindet. Die Dauerleistung ändert sich mit Batterietemperatur und Ladezustand.";
CM_ SG_ 2589283760 BMS_Max_Spannung "Maximal erlaubte Batteriespannung, zwingend einzuhaltender Grenzwert";
CM_ SG_ 2589283760 BMS_Min_Spannung "Minimal erlaubte Batteriespannung, zwingend einzuhaltender Grenzwert";

CM_ SG_ 2463978646 CHA_Current_Mode "Aktuell eingestelltes Charisma Fahrprogramm";
CM_ SG_ 2463978646 CHA_Current_Mode_BMA "Aktuell eingestellter Charisma Betriebsmodus";
CM_ SG_ 2463978646 CHA_Fahrer_Umschaltung "Die manuelle Umschaltung durch den Fahrer soll signalisiert werden, um zu automatischen Umschaltungen (z.B. Retries) differenzieren zu können.";
CM_ SG_ 2463978646 CHA_Fahrer_Umschaltung_BMA "Die manuelle Umschaltung der Betriebsmodusauswahl durch den Fahrer soll signalisiert werden, um zu automatischen Umschaltungen (z.B. Retries) differenzieren zu können.";
CM_ SG_ 2463978646 CHA_Ziel_FahrPr_ACC "MQB
Anforderung Ziel-Fahrprogramm ACC";
CM_ SG_ 2463978646 CHA_Ziel_FahrPr_AEB "Anforderung Ziel-Fahrprogramm AEB (Autonomous Emergency Braking)";
CM_ SG_ 2463978646 CHA_Ziel_FahrPr_AFR "Anforderung Ziel-Fahrprogramm Aktive Fahrwerk Regelung (eAWS und eABC)";
CM_ SG_ 2463978646 CHA_Ziel_FahrPr_AFS "Anforderung Ziel-Fahrprogramm AFS";
CM_ SG_ 2463978646 CHA_Ziel_FahrPr_AGA "Anforderung Ziel-Fahrprogramm AGA/SAK2 (Aussensound)";
CM_ SG_ 2463978646 CHA_Ziel_FahrPr_AGK "Signal zur Ansteuerung des Teilnehmers Abgasklappen durch den Charisma-Koordinator über das Motor-SG";
CM_ SG_ 2463978646 CHA_Ziel_FahrPr_ALR "Anforderung Ziel-Fahrprogramm Allrad";
CM_ SG_ 2463978646 CHA_Ziel_FahrPr_AV "Anforderung Ziel-Fahrprogramm AreaView2";
CM_ SG_ 2463978646 CHA_Ziel_FahrPr_BMS "Anforderung Ziel-Fahrprogramm BMS (nähere Spezifikation siehe Charisma-LH PAG)";
CM_ SG_ 2463978646 CHA_Ziel_FahrPr_DR "Anforderung Ziel-Fahrprogramm Dämpfer";
CM_ SG_ 2463978646 CHA_Ziel_FahrPr_EAR "Anforderung Zielfahrprogramm EAR (EFP Allrad Regelsysteme)";
CM_ SG_ 2463978646 CHA_Ziel_FahrPr_EBKV "Signal zur Ansteuerung des EBKV durch den Charisma-Koordinator";
CM_ SG_ 2463978646 CHA_Ziel_FahrPr_EDS "Anforderung Ziel-Fahrprogramm Elektronische Differentialsperre";
CM_ SG_ 2463978646 CHA_Ziel_FahrPr_EPS "Anforderung Ziel-Fahrprogramm Elektrische Lenkhilfe";
CM_ SG_ 2463978646 CHA_Ziel_FahrPr_ESP "Anforderung Ziel-Fahrprogramm ESP";
CM_ SG_ 2463978646 CHA_Ziel_FahrPr_FCWO "Anforderung Ziel-Fahrprogramm FCWO (Objektwarnung)";
CM_ SG_ 2463978646 CHA_Ziel_FahrPr_FCWP "Anforderung Ziel-Fahrprogramm FCWP (Personenwarnung)";
CM_ SG_ 2463978646 CHA_Ziel_FahrPr_Freilauf "Anforderung Ziel-Fahrprogramm Funktion Freilauf";
CM_ SG_ 2463978646 CHA_Ziel_FahrPr_GE "Anforderung Ziel-Fahrprogramm Getriebe";
CM_ SG_ 2463978646 CHA_Ziel_FahrPr_HAL "Anforderung Zielfahrprogramm Hinterachslenkung (HAL)";
CM_ SG_ 2463978646 CHA_Ziel_FahrPr_HDC "Anforderung Ziel-Fahrprogramm Hill Descent Control";
CM_ SG_ 2463978646 CHA_Ziel_FahrPr_HHC "Anforderung Ziel-Fahrprogramm Hill Hold Control";
CM_ SG_ 2463978646 CHA_Ziel_FahrPr_IL "Anforderung Ziel-Fahrprogramm Integrallenkung";
CM_ SG_ 2463978646 CHA_Ziel_FahrPr_mFDR "Signal zur Ansteuerung des mFDR durch den Charisma-Koordinator";
CM_ SG_ 2463978646 CHA_Ziel_FahrPr_MO "Anforderung Ziel-Fahrprogramm Motor";
CM_ SG_ 2463978646 CHA_Ziel_FahrPr_MO_BZS "Anforderung Zielfahrprogramm Motor-Betriebszusände";
CM_ SG_ 2463978646 CHA_Ziel_FahrPr_MO_Freilauf "Anforderung Ziel-Fahrprogramm Funktion Freilauf Motor aus";
CM_ SG_ 2463978646 CHA_Ziel_FahrPr_MO_StSt "Anforderung Ziel-Fahrprogramm Funktion Motor Start-Stopp";
CM_ SG_ 2463978646 CHA_Ziel_FahrPr_MXB "Anforderung Ziel-Fahrprogramm MXB";
CM_ SG_ 2463978646 CHA_Ziel_FahrPr_NR "Anforderung Ziel-Fahrprogramm Niveaureglierung";
CM_ SG_ 2463978646 CHA_Ziel_FahrPr_PACC "Anforderung Ziel-Fahrprogramm InnoDrive (PACCh)";
CM_ SG_ 2463978646 CHA_Ziel_FahrPr_PDC "Signal zur Ansteuerung des PDC/PLA durch den Charisma-Koordinator";
CM_ SG_ 2463978646 CHA_Ziel_FahrPr_PreCrash "Anforderung Ziel-Fahrprogramm PreCrash";
CM_ SG_ 2463978646 CHA_Ziel_FahrPr_QS "Anforderung Ziel-Fahrprogramm geregelte Hinterachsquersperre";
CM_ SG_ 2463978646 CHA_Ziel_FahrPr_Reku_ZwGas "Anforderung Ziel-Fahrprogramm für Rekuperation oder Zwischengas";
CM_ SG_ 2463978646 CHA_Ziel_FahrPr_SAK "Anforderung Ziel-Fahrprogramm Soundaktuator";
CM_ SG_ 2463978646 CHA_Ziel_FahrPr_SCU "Anforderung Ziel-Fahrprogramm SCU";
CM_ SG_ 2463978646 CHA_Ziel_FahrPr_ToS_laengs "Signal zur Ansteuerung des Torque Splitter längs durch den Charisma-Koordinator";
CM_ SG_ 2463978646 CHA_Ziel_FahrPr_ToS_quer "Signal zur Ansteuerung des Torque Splitter quer durch den Charisma-Koordinator";
CM_ SG_ 2463978646 CHA_Ziel_FahrPr_VAQ "Anforderung Ziel-Fahrprogramm VAQ";

BA_DEF_  "DBName" STRING;
BA_DEF_  "GenNWMApBusSleep" STRING;
BA_DEF_  "GenNWMApCanNormal" STRING;
BA_DEF_  "GenNWMApCanOff" STRING;
BA_DEF_  "GenNWMApCanOn" STRING;
BA_DEF_  "GenNWMApCanSleep" STRING;
BA_DEF_  "GenNWMApCanWakeUp" STRING;
BA_DEF_  "GenNWMGotoMode_Awake" STRING;
BA_DEF_  "GenNWMGotoMode_BusSleep" STRING;
BA_DEF_  "GenNWMSleepTime" INT 0 1000000;
BA_DEF_  "GenNWMTalkNM" STRING;
BA_DEF_  "Manufacturer" STRING;
BA_DEF_  "NmhBaseAddress" HEX 0 536870911;
BA_DEF_  "NmhMessageCount" INT 0 1024;
BA_DEF_  "NmType" STRING;
BA_DEF_  "VAGTP20_SetupMessageCount" INT 0 255;
BA_DEF_  "VAGTP20_SetupStartAddress" HEX 0 2047;
BA_DEF_  "VersionDay" INT 1 31;
BA_DEF_  "VersionMonth" INT 1 12;
BA_DEF_  "VersionWeek" INT 1 52;
BA_DEF_  "VersionYear" INT 0 99;
BA_DEF_  "VersionNumber" INT 0 65535;
BA_DEF_  "BusType" STRING;
BA_DEF_  "Baudrate" INT 1 1000000;
BA_DEF_  "BaudrateCANFD" INT 1 16000000;
BA_DEF_  "NmhTimeoutTimer" INT 0 65535;
BA_DEF_  "NmhWaitBusSleepTimer" INT 0 65535;
BA_DEF_  "NmhPrepareBusSleepTimer" INT 0 65535;
BA_DEF_  "NmhLongTimer" INT 0 65535;
BA_DEF_  "NmhNStart" INT 0 255;
BA_DEF_ BU_  "GenNodAutoGenDsp" ENUM "No", "Yes";
BA_DEF_ BU_  "GenNodAutoGenSnd" ENUM "No", "Yes";
BA_DEF_ BU_  "GenNodSleepTime" INT 0 1000000;
BA_DEF_ BU_  "ILUsed" ENUM "No", "Yes";
BA_DEF_ BU_  "ECUVariantDefault" ENUM "No", "Yes";
BA_DEF_ BU_  "ECUVariantGroup" STRING;
BA_DEF_ BU_  "NodeLayerModules" STRING;
BA_DEF_ BU_  "NmhNode" ENUM "No", "Yes";
BA_DEF_ BU_  "NmNode" ENUM "No", "Yes";
BA_DEF_ BU_  "SamplePointMin" FLOAT 50.0 99.9;
BA_DEF_ BU_  "SamplePointMax" FLOAT 50.0 99.9;
BA_DEF_ BU_  "SyncJumpWidthMin" FLOAT 0.0 50.0;
BA_DEF_ BU_  "SyncJumpWidthMax" FLOAT 0.0 50.0;
BA_DEF_ BU_  "SyncJumpWidthCANFDMin" FLOAT 0.0 50.0;
BA_DEF_ BU_  "SyncJumpWidthCANFDMax" FLOAT 0.0 50.0;
BA_DEF_ BU_  "SamplePointCANFDMin" FLOAT 50.0 99.9;
BA_DEF_ BU_  "SamplePointCANFDMax" FLOAT 50.0 99.9;
BA_DEF_ BU_  "SSPOffsetCANFDMin" FLOAT 50.0 99.9;
BA_DEF_ BU_  "SSPOffsetCANFDMax" FLOAT 50.0 99.9;
BA_DEF_ BU_  "TimeQuantaMin" INT 4 257;
BA_DEF_ BU_  "TimeQuantaMax" INT 4 257;
BA_DEF_ BU_  "TimeQuantaCANFDMin" INT 4 257;
BA_DEF_ BU_  "TimeQuantaCANFDMax" INT 4 257;
BA_DEF_REL_ BU_SG_REL_  "GenSigTimeoutTime" INT 0 65535;
BA_DEF_ BO_  "DiagRequest" ENUM "No", "Yes";
BA_DEF_ BO_  "DiagResponse" ENUM "No", "Yes";
BA_DEF_ BO_  "DiagState" ENUM "No", "Yes";
BA_DEF_ BO_  "GenMsgChkConstant" HEX 0 4095;
BA_DEF_ BO_  "GenMsgCycleTime" INT 0 65535;
BA_DEF_ BO_  "GenMsgCycleTimeFast" INT 0 65535;
BA_DEF_ BO_  "GenMsgDelayTime" INT 0 100000;
BA_DEF_ BO_  "GenMsgILSupport" ENUM "No", "Yes";
BA_DEF_ BO_  "GenMsgNrOfRepetition" INT 0 100;
BA_DEF_ BO_  "GenMsgPDUConstants" STRING;
BA_DEF_ BO_  "GenMsgSendType" ENUM "Cyclic", "not_used", "not_used", "not_used", "not_used", "not_used", "not_used", "IfActive", "NoMsgSendType";
BA_DEF_ BO_  "GenMsgStartDelayTime" INT 0 100000;
BA_DEF_ BO_  "NmMessage" ENUM "No", "Yes";
BA_DEF_ BO_  "NmhMessage" ENUM "No", "Yes";
BA_DEF_ BO_  "MsgType" ENUM "Application", "NM ", "NMH", "TP2.0", "ISO-TP ", "BAP", "EID", "KS";
BA_DEF_ BO_  "VAGTP20_API" HEX 0 255;
BA_DEF_ BO_  "VAGTP20_DynConnection" ENUM "No", "Yes";
BA_DEF_ BO_  "VAGTP20_DynSetup" ENUM "No", "Yes";
BA_DEF_ BO_  "VAGTP20_StatConnection" ENUM "No", "Yes";
BA_DEF_ BO_  "CANFD_BRS" ENUM "0", "1";
BA_DEF_ BO_  "VFrameFormat" ENUM "StandardCAN", "ExtendedCAN", "reserved", "reserved", "reserved", "reserved", "reserved", "reserved", "reserved", "reserved", "reserved", "reserved", "reserved", "reserved", "StandardCAN_FD", "ExtendedCAN_FD";
BA_DEF_ SG_  "GenSigActiveRepetitions" INT -2147483648 2147483647;
BA_DEF_ SG_  "GenSigInactiveValue" INT -2147483648 2147483647;
BA_DEF_ SG_  "GenSigSendType" ENUM "Cyclic", "OnWrite", "OnWriteWithRepetition", "OnChange", "OnChangeWithRepetition", "IfActive", "IfActiveWithRepetition", "NoSigSendType", "OnChangeAndIfActive", "OnChangeAndIfActiveWithRepetition";
BA_DEF_ SG_  "GenSigStartValue" INT -2147483648 2147483647;
BA_DEF_ SG_  "NWM-WakeupAllowed" ENUM "No", "Yes";
BA_DEF_ SG_  "GenSigFuncType" ENUM "NoFunction", "MsgCounter", "CRC-8", "XOR", "XOR-2", "DatedBit", "SW-Kl15", "CHK", "Constant", "Protocol", "CRC-8-SAE_J1850";
BA_DEF_ SG_  "GenSigSwitchedByIgnition" ENUM "No", "Yes";
BA_DEF_ SG_  "Fehlerwert" HEX 0 2147483647;
BA_DEF_ SG_  "GenSigMissingSourceValue" HEX 0 2147483647;
BA_DEF_DEF_  "DBName" "";
BA_DEF_DEF_  "GenNWMApBusSleep" "";
BA_DEF_DEF_  "GenNWMApCanNormal" "";
BA_DEF_DEF_  "GenNWMApCanOff" "";
BA_DEF_DEF_  "GenNWMApCanOn" "";
BA_DEF_DEF_  "GenNWMApCanSleep" "";
BA_DEF_DEF_  "GenNWMApCanWakeUp" "";
BA_DEF_DEF_  "GenNWMGotoMode_Awake" "";
BA_DEF_DEF_  "GenNWMGotoMode_BusSleep" "";
BA_DEF_DEF_  "GenNWMSleepTime" 0;
BA_DEF_DEF_  "GenNWMTalkNM" "";
BA_DEF_DEF_  "Manufacturer" "";
BA_DEF_DEF_  "NmhBaseAddress" 0;
BA_DEF_DEF_  "NmhMessageCount" 1;
BA_DEF_DEF_  "NmType" "None";
BA_DEF_DEF_  "VAGTP20_SetupMessageCount" 0;
BA_DEF_DEF_  "VAGTP20_SetupStartAddress" 0;
BA_DEF_DEF_  "VersionDay" 8;
BA_DEF_DEF_  "VersionMonth" 2;
BA_DEF_DEF_  "VersionWeek" 6;
BA_DEF_DEF_  "VersionYear" 18;
BA_DEF_DEF_  "VersionNumber" 0;
BA_DEF_DEF_  "BusType" "";
BA_DEF_DEF_  "Baudrate" 500000;
BA_DEF_DEF_  "BaudrateCANFD" 2000000;
BA_DEF_DEF_  "NmhTimeoutTimer" 0;
BA_DEF_DEF_  "NmhWaitBusSleepTimer" 0;
BA_DEF_DEF_  "NmhPrepareBusSleepTimer" 0;
BA_DEF_DEF_  "NmhLongTimer" 0;
BA_DEF_DEF_  "NmhNStart" 0;
BA_DEF_DEF_  "GenNodAutoGenDsp" "Yes";
BA_DEF_DEF_  "GenNodAutoGenSnd" "Yes";
BA_DEF_DEF_  "GenNodSleepTime" 0;
BA_DEF_DEF_  "ILUsed" "Yes";
BA_DEF_DEF_  "ECUVariantDefault" "Yes";
BA_DEF_DEF_  "ECUVariantGroup" "";
BA_DEF_DEF_  "NodeLayerModules" "";
BA_DEF_DEF_  "NmhNode" "Yes";
BA_DEF_DEF_  "NmNode" "No";
BA_DEF_DEF_  "SamplePointMin" 75;
BA_DEF_DEF_  "SamplePointMax" 75;
BA_DEF_DEF_  "SyncJumpWidthMin" 50;
BA_DEF_DEF_  "SyncJumpWidthMax" 50;
BA_DEF_DEF_  "SyncJumpWidthCANFDMin" 50;
BA_DEF_DEF_  "SyncJumpWidthCANFDMax" 50;
BA_DEF_DEF_  "SamplePointCANFDMin" 75;
BA_DEF_DEF_  "SamplePointCANFDMax" 75;
BA_DEF_DEF_  "SSPOffsetCANFDMin" 75;
BA_DEF_DEF_  "SSPOffsetCANFDMax" 75;
BA_DEF_DEF_  "TimeQuantaMin" 160;
BA_DEF_DEF_  "TimeQuantaMax" 160;
BA_DEF_DEF_  "TimeQuantaCANFDMin" 40;
BA_DEF_DEF_  "TimeQuantaCANFDMax" 40;
BA_DEF_DEF_REL_  "GenSigTimeoutTime" 0;
BA_DEF_DEF_  "DiagRequest" "No";
BA_DEF_DEF_  "DiagResponse" "No";
BA_DEF_DEF_  "DiagState" "No";
BA_DEF_DEF_  "GenMsgChkConstant" 0;
BA_DEF_DEF_  "GenMsgCycleTime" 0;
BA_DEF_DEF_  "GenMsgCycleTimeFast" 0;
BA_DEF_DEF_  "GenMsgDelayTime" 0;
BA_DEF_DEF_  "GenMsgILSupport" "No";
BA_DEF_DEF_  "GenMsgNrOfRepetition" 0;
BA_DEF_DEF_  "GenMsgPDUConstants" "";
BA_DEF_DEF_  "GenMsgSendType" "NoMsgSendType";
BA_DEF_DEF_  "GenMsgStartDelayTime" 0;
BA_DEF_DEF_  "NmMessage" "No";
BA_DEF_DEF_  "NmhMessage" "No";
BA_DEF_DEF_  "MsgType" "Application";
BA_DEF_DEF_  "VAGTP20_API" 0;
BA_DEF_DEF_  "VAGTP20_DynConnection" "No";
BA_DEF_DEF_  "VAGTP20_DynSetup" "No";
BA_DEF_DEF_  "VAGTP20_StatConnection" "No";
BA_DEF_DEF_  "CANFD_BRS" "1";
BA_DEF_DEF_  "VFrameFormat" "StandardCAN";
BA_DEF_DEF_  "GenSigActiveRepetitions" 0;
BA_DEF_DEF_  "GenSigInactiveValue" 0;
BA_DEF_DEF_  "GenSigSendType" "NoSigSendType";
BA_DEF_DEF_  "GenSigStartValue" 0;
BA_DEF_DEF_  "NWM-WakeupAllowed" "No";
BA_DEF_DEF_  "GenSigFuncType" "NoFunction";
BA_DEF_DEF_  "GenSigSwitchedByIgnition" "Yes";
BA_DEF_DEF_  "Fehlerwert" 0;
BA_DEF_DEF_  "GenSigMissingSourceValue" 0;
BA_  "DBName" "MEB_ACANFD";
BA_  "GenNWMApBusSleep" "NMIndNetSDN()";
BA_  "GenNWMApCanNormal" "apCanNormal()";
BA_  "GenNWMApCanOff" "NMIndnetOff()";
BA_  "GenNWMApCanOn" "NMIndnetOn()";
BA_  "GenNWMApCanSleep" "apCanSleep()";
BA_  "GenNWMApCanWakeUp" "apCanWakeUp()";
BA_  "GenNWMGotoMode_Awake" "Nmh_ReqNetOn()";
BA_  "GenNWMGotoMode_BusSleep" "Nmh_ReqNetOff()";
BA_  "GenNWMSleepTime" 4000;
BA_  "GenNWMTalkNM" "Nmh_ReqNetOn()";
BA_  "Manufacturer" "VAG";
BA_  "NmhBaseAddress" 452984832;
BA_  "NmhMessageCount" 1024;
BA_  "NmType" "NM-High";
BA_  "VAGTP20_SetupMessageCount" 128;
BA_  "VAGTP20_SetupStartAddress" 512;
BA_  "VersionNumber" 403;
BA_  "BusType" "CAN FD";
BA_  "NmhTimeoutTimer" 1000;
BA_  "NmhWaitBusSleepTimer" 750;
BA_  "NmhPrepareBusSleepTimer" 500;
BA_  "NmhLongTimer" 200;
BA_  "NmhNStart" 20;
BA_ "GenNodSleepTime" BU_ Airbag 4000;
BA_ "NodeLayerModules" BU_ Airbag "NMHigh.DLL";
BA_ "SamplePointMin" BU_ Airbag 80;
BA_ "SamplePointMax" BU_ Airbag 80;
BA_ "SyncJumpWidthMin" BU_ Airbag 16;
BA_ "SyncJumpWidthMax" BU_ Airbag 16;
BA_ "SyncJumpWidthCANFDMin" BU_ Airbag 6;
BA_ "SyncJumpWidthCANFDMax" BU_ Airbag 6;
BA_ "SamplePointCANFDMin" BU_ Airbag 70;
BA_ "SamplePointCANFDMax" BU_ Airbag 70;
BA_ "SSPOffsetCANFDMin" BU_ Airbag 70;
BA_ "SSPOffsetCANFDMax" BU_ Airbag 70;
BA_ "TimeQuantaMin" BU_ Airbag 80;
BA_ "TimeQuantaMax" BU_ Airbag 80;
BA_ "TimeQuantaCANFDMin" BU_ Airbag 20;
BA_ "TimeQuantaCANFDMax" BU_ Airbag 20;
BA_ "GenNodSleepTime" BU_ BAP_Tester 4000;
BA_ "ECUVariantGroup" BU_ BAP_Tester "BAP";
BA_ "NmhNode" BU_ BAP_Tester 0;
BA_ "SamplePointMin" BU_ BAP_Tester 80;
BA_ "SamplePointMax" BU_ BAP_Tester 80;
BA_ "SyncJumpWidthMin" BU_ BAP_Tester 16;
BA_ "SyncJumpWidthMax" BU_ BAP_Tester 16;
BA_ "SyncJumpWidthCANFDMin" BU_ BAP_Tester 6;
BA_ "SyncJumpWidthCANFDMax" BU_ BAP_Tester 6;
BA_ "SamplePointCANFDMin" BU_ BAP_Tester 70;
BA_ "SamplePointCANFDMax" BU_ BAP_Tester 70;
BA_ "SSPOffsetCANFDMin" BU_ BAP_Tester 70;
BA_ "SSPOffsetCANFDMax" BU_ BAP_Tester 70;
BA_ "TimeQuantaMin" BU_ BAP_Tester 80;
BA_ "TimeQuantaMax" BU_ BAP_Tester 80;
BA_ "TimeQuantaCANFDMin" BU_ BAP_Tester 20;
BA_ "TimeQuantaCANFDMax" BU_ BAP_Tester 20;
BA_ "GenNodSleepTime" BU_ ICAS1_Gateway 4000;
BA_ "ECUVariantGroup" BU_ ICAS1_Gateway "Gateway";
BA_ "NodeLayerModules" BU_ ICAS1_Gateway "NMHigh.DLL";
BA_ "SamplePointMin" BU_ ICAS1_Gateway 80;
BA_ "SamplePointMax" BU_ ICAS1_Gateway 80;
BA_ "SyncJumpWidthMin" BU_ ICAS1_Gateway 16;
BA_ "SyncJumpWidthMax" BU_ ICAS1_Gateway 16;
BA_ "SyncJumpWidthCANFDMin" BU_ ICAS1_Gateway 6;
BA_ "SyncJumpWidthCANFDMax" BU_ ICAS1_Gateway 6;
BA_ "SamplePointCANFDMin" BU_ ICAS1_Gateway 70;
BA_ "SamplePointCANFDMax" BU_ ICAS1_Gateway 70;
BA_ "SSPOffsetCANFDMin" BU_ ICAS1_Gateway 70;
BA_ "SSPOffsetCANFDMax" BU_ ICAS1_Gateway 70;
BA_ "TimeQuantaMin" BU_ ICAS1_Gateway 80;
BA_ "TimeQuantaMax" BU_ ICAS1_Gateway 80;
BA_ "TimeQuantaCANFDMin" BU_ ICAS1_Gateway 20;
BA_ "TimeQuantaCANFDMax" BU_ ICAS1_Gateway 20;
BA_ "GenNodSleepTime" BU_ ICAS1_KommunikationsServer 4000;
BA_ "NmhNode" BU_ ICAS1_KommunikationsServer 0;
BA_ "SamplePointMin" BU_ ICAS1_KommunikationsServer 80;
BA_ "SamplePointMax" BU_ ICAS1_KommunikationsServer 80;
BA_ "SyncJumpWidthMin" BU_ ICAS1_KommunikationsServer 16;
BA_ "SyncJumpWidthMax" BU_ ICAS1_KommunikationsServer 16;
BA_ "SyncJumpWidthCANFDMin" BU_ ICAS1_KommunikationsServer 6;
BA_ "SyncJumpWidthCANFDMax" BU_ ICAS1_KommunikationsServer 6;
BA_ "SamplePointCANFDMin" BU_ ICAS1_KommunikationsServer 70;
BA_ "SamplePointCANFDMax" BU_ ICAS1_KommunikationsServer 70;
BA_ "SSPOffsetCANFDMin" BU_ ICAS1_KommunikationsServer 70;
BA_ "SSPOffsetCANFDMax" BU_ ICAS1_KommunikationsServer 70;
BA_ "TimeQuantaMin" BU_ ICAS1_KommunikationsServer 80;
BA_ "TimeQuantaMax" BU_ ICAS1_KommunikationsServer 80;
BA_ "TimeQuantaCANFDMin" BU_ ICAS1_KommunikationsServer 20;
BA_ "TimeQuantaCANFDMax" BU_ ICAS1_KommunikationsServer 20;
BA_ "GenNodSleepTime" BU_ LE1 4000;
BA_ "ECUVariantDefault" BU_ LE1 0;
BA_ "ECUVariantGroup" BU_ LE1 "EMotor";
BA_ "NodeLayerModules" BU_ LE1 "NMHigh.DLL";
BA_ "SamplePointMin" BU_ LE1 80;
BA_ "SamplePointMax" BU_ LE1 80;
BA_ "SyncJumpWidthMin" BU_ LE1 16;
BA_ "SyncJumpWidthMax" BU_ LE1 16;
BA_ "SyncJumpWidthCANFDMin" BU_ LE1 6;
BA_ "SyncJumpWidthCANFDMax" BU_ LE1 6;
BA_ "SamplePointCANFDMin" BU_ LE1 70;
BA_ "SamplePointCANFDMax" BU_ LE1 70;
BA_ "SSPOffsetCANFDMin" BU_ LE1 70;
BA_ "SSPOffsetCANFDMax" BU_ LE1 70;
BA_ "TimeQuantaMin" BU_ LE1 80;
BA_ "TimeQuantaMax" BU_ LE1 80;
BA_ "TimeQuantaCANFDMin" BU_ LE1 20;
BA_ "TimeQuantaCANFDMax" BU_ LE1 20;
BA_ "GenNodSleepTime" BU_ LE2 4000;
BA_ "NodeLayerModules" BU_ LE2 "NMHigh.DLL";
BA_ "SamplePointMin" BU_ LE2 80;
BA_ "SamplePointMax" BU_ LE2 80;
BA_ "SyncJumpWidthMin" BU_ LE2 16;
BA_ "SyncJumpWidthMax" BU_ LE2 16;
BA_ "SyncJumpWidthCANFDMin" BU_ LE2 6;
BA_ "SyncJumpWidthCANFDMax" BU_ LE2 6;
BA_ "SamplePointCANFDMin" BU_ LE2 70;
BA_ "SamplePointCANFDMax" BU_ LE2 70;
BA_ "SSPOffsetCANFDMin" BU_ LE2 70;
BA_ "SSPOffsetCANFDMax" BU_ LE2 70;
BA_ "TimeQuantaMin" BU_ LE2 80;
BA_ "TimeQuantaMax" BU_ LE2 80;
BA_ "TimeQuantaCANFDMin" BU_ LE2 20;
BA_ "TimeQuantaCANFDMax" BU_ LE2 20;
BA_ "GenNodSleepTime" BU_ Motor_BEV 4000;
BA_ "ECUVariantGroup" BU_ Motor_BEV "Motor";
BA_ "NodeLayerModules" BU_ Motor_BEV "NMHigh.DLL";
BA_ "SamplePointMin" BU_ Motor_BEV 80;
BA_ "SamplePointMax" BU_ Motor_BEV 80;
BA_ "SyncJumpWidthMin" BU_ Motor_BEV 16;
BA_ "SyncJumpWidthMax" BU_ Motor_BEV 16;
BA_ "SyncJumpWidthCANFDMin" BU_ Motor_BEV 6;
BA_ "SyncJumpWidthCANFDMax" BU_ Motor_BEV 6;
BA_ "SamplePointCANFDMin" BU_ Motor_BEV 70;
BA_ "SamplePointCANFDMax" BU_ Motor_BEV 70;
BA_ "SSPOffsetCANFDMin" BU_ Motor_BEV 70;
BA_ "SSPOffsetCANFDMax" BU_ Motor_BEV 70;
BA_ "TimeQuantaMin" BU_ Motor_BEV 80;
BA_ "TimeQuantaMax" BU_ Motor_BEV 80;
BA_ "TimeQuantaCANFDMin" BU_ Motor_BEV 20;
BA_ "TimeQuantaCANFDMax" BU_ Motor_BEV 20;
BA_ "GenNodSleepTime" BU_ Schaltbetaetigung 4000;
BA_ "ECUVariantGroup" BU_ Schaltbetaetigung "Waehlhebel";
BA_ "NodeLayerModules" BU_ Schaltbetaetigung "NMHigh.DLL";
BA_ "SamplePointMin" BU_ Schaltbetaetigung 80;
BA_ "SamplePointMax" BU_ Schaltbetaetigung 80;
BA_ "SyncJumpWidthMin" BU_ Schaltbetaetigung 16;
BA_ "SyncJumpWidthMax" BU_ Schaltbetaetigung 16;
BA_ "SyncJumpWidthCANFDMin" BU_ Schaltbetaetigung 6;
BA_ "SyncJumpWidthCANFDMax" BU_ Schaltbetaetigung 6;
BA_ "SamplePointCANFDMin" BU_ Schaltbetaetigung 70;
BA_ "SamplePointCANFDMax" BU_ Schaltbetaetigung 70;
BA_ "SSPOffsetCANFDMin" BU_ Schaltbetaetigung 70;
BA_ "SSPOffsetCANFDMax" BU_ Schaltbetaetigung 70;
BA_ "TimeQuantaMin" BU_ Schaltbetaetigung 80;
BA_ "TimeQuantaMax" BU_ Schaltbetaetigung 80;
BA_ "TimeQuantaCANFDMin" BU_ Schaltbetaetigung 20;
BA_ "TimeQuantaCANFDMax" BU_ Schaltbetaetigung 20;
BA_ "GenMsgCycleTime" BO_ 333 20;
BA_ "GenMsgILSupport" BO_ 333 1;
BA_ "GenMsgPDUConstants" BO_ 333 "0x1a,0x65,0x81,0x96,0xc0,0xdf,0x11,0x92,0xd3,0x61,0xc6,0x95,0x8c,0x29,0x21,0xb5";
BA_ "GenMsgSendType" BO_ 333 0;
BA_ "VFrameFormat" BO_ 333 14;
BA_ "GenMsgCycleTime" BO_ 2527679682 2000;
BA_ "GenMsgDelayTime" BO_ 2527679682 100;
BA_ "GenMsgILSupport" BO_ 2527679682 1;
BA_ "GenMsgSendType" BO_ 2527679682 0;
BA_ "VFrameFormat" BO_ 2527679682 15;
BA_ "GenMsgChkConstant" BO_ 64 64;
BA_ "GenMsgCycleTime" BO_ 64 40;
BA_ "GenMsgCycleTimeFast" BO_ 64 10;
BA_ "GenMsgDelayTime" BO_ 64 10;
BA_ "GenMsgILSupport" BO_ 64 1;
BA_ "GenMsgNrOfRepetition" BO_ 64 5;
BA_ "GenMsgPDUConstants" BO_ 64 "0x40,0x40,0x40,0x40,0x40,0x40,0x40,0x40,0x40,0x40,0x40,0x40,0x40,0x40,0x40,0x40";
BA_ "GenMsgSendType" BO_ 64 0;
BA_ "CANFD_BRS" BO_ 64 0;
BA_ "GenMsgChkConstant" BO_ 1312 68;
BA_ "GenMsgCycleTime" BO_ 1312 200;
BA_ "GenMsgDelayTime" BO_ 1312 20;
BA_ "GenMsgILSupport" BO_ 1312 1;
BA_ "GenMsgPDUConstants" BO_ 1312 "0x44,0x44,0x44,0x44,0x44,0x44,0x44,0x44,0x44,0x44,0x44,0x44,0x44,0x44,0x44,0x44";
BA_ "GenMsgSendType" BO_ 1312 0;
BA_ "CANFD_BRS" BO_ 1312 0;
BA_ "GenMsgCycleTime" BO_ 65 1000;
BA_ "GenMsgCycleTimeFast" BO_ 65 10;
BA_ "GenMsgDelayTime" BO_ 65 10;
BA_ "GenMsgILSupport" BO_ 65 1;
BA_ "GenMsgNrOfRepetition" BO_ 65 5;
BA_ "GenMsgPDUConstants" BO_ 65 "0x93,0xb0,0x9d,0xf1,0x09,0xe8,0x88,0x5e,0x36,0xfa,0xa8,0xa1,0x67,0x84,0xca,0x4f";
BA_ "GenMsgSendType" BO_ 65 0;
BA_ "CANFD_BRS" BO_ 65 0;
BA_ "GenMsgCycleTime" BO_ 1349 200;
BA_ "GenMsgDelayTime" BO_ 1349 40;
BA_ "GenMsgILSupport" BO_ 1349 1;
BA_ "GenMsgSendType" BO_ 1349 0;
BA_ "CANFD_BRS" BO_ 1349 0;
BA_ "GenMsgCycleTime" BO_ 2527679722 200;
BA_ "GenMsgILSupport" BO_ 2527679722 1;
BA_ "GenMsgSendType" BO_ 2527679722 0;
BA_ "CANFD_BRS" BO_ 2527679722 0;
BA_ "VFrameFormat" BO_ 2527679722 1;
BA_ "GenMsgCycleTime" BO_ 1633 100;
BA_ "GenMsgILSupport" BO_ 1633 1;
BA_ "GenMsgSendType" BO_ 1633 0;
BA_ "VFrameFormat" BO_ 1633 14;
BA_ "GenMsgCycleTime" BO_ 345 100;
BA_ "GenMsgDelayTime" BO_ 345 10;
BA_ "GenMsgILSupport" BO_ 345 1;
BA_ "GenMsgSendType" BO_ 345 0;
BA_ "VFrameFormat" BO_ 345 14;
BA_ "GenMsgCycleTime" BO_ 2589283607 200;
BA_ "GenMsgDelayTime" BO_ 2589283607 100;
BA_ "GenMsgILSupport" BO_ 2589283607 1;
BA_ "GenMsgNrOfRepetition" BO_ 2589283607 5;
BA_ "GenMsgPDUConstants" BO_ 2589283607 "0xfb,0xee,0x5d,0x2d,0xfa,0x85,0x27,0xd4,0xc9,0xc4,0xa5,0x45,0x5f,0x76,0xa3,0x89";
BA_ "GenMsgSendType" BO_ 2589283607 0;
BA_ "VFrameFormat" BO_ 2589283607 15;
BA_ "GenMsgCycleTime" BO_ 219 1000;
BA_ "GenMsgCycleTimeFast" BO_ 219 20;
BA_ "GenMsgDelayTime" BO_ 219 20;
BA_ "GenMsgILSupport" BO_ 219 1;
BA_ "GenMsgNrOfRepetition" BO_ 219 5;
BA_ "GenMsgPDUConstants" BO_ 219 "0x09,0xfa,0xca,0x8e,0x62,0xd5,0xd1,0xf0,0x31,0xa0,0xaf,0xda,0x4d,0x1a,0x0a,0x97";
BA_ "GenMsgSendType" BO_ 219 0;
BA_ "VFrameFormat" BO_ 219 14;
BA_ "MsgType" BO_ 2536767264 5;
BA_ "VFrameFormat" BO_ 2536767264 15;
BA_ "MsgType" BO_ 2536767280 5;
BA_ "VFrameFormat" BO_ 2536767280 15;
BA_ "GenMsgCycleTimeFast" BO_ 2536717313 80;
BA_ "GenMsgSendType" BO_ 2536717313 7;
BA_ "MsgType" BO_ 2536717313 5;
BA_ "VFrameFormat" BO_ 2536717313 15;
BA_ "GenMsgCycleTimeFast" BO_ 2536717314 80;
BA_ "GenMsgSendType" BO_ 2536717314 7;
BA_ "MsgType" BO_ 2536717314 5;
BA_ "VFrameFormat" BO_ 2536717314 15;
BA_ "GenMsgCycleTime" BO_ 2536717328 1000;
BA_ "GenMsgCycleTimeFast" BO_ 2536717328 50;
BA_ "GenMsgSendType" BO_ 2536717328 7;
BA_ "MsgType" BO_ 2536717328 5;
BA_ "VFrameFormat" BO_ 2536717328 15;
BA_ "GenMsgCycleTimeFast" BO_ 2536709120 80;
BA_ "GenMsgSendType" BO_ 2536709120 7;
BA_ "MsgType" BO_ 2536709120 5;
BA_ "VFrameFormat" BO_ 2536709120 15;
BA_ "GenMsgCycleTime" BO_ 2536709136 1000;
BA_ "GenMsgCycleTimeFast" BO_ 2536709136 50;
BA_ "GenMsgSendType" BO_ 2536709136 7;
BA_ "MsgType" BO_ 2536709136 5;
BA_ "VFrameFormat" BO_ 2536709136 15;
BA_ "GenMsgCycleTime" BO_ 869 50;
BA_ "GenMsgILSupport" BO_ 869 1;
BA_ "GenMsgSendType" BO_ 869 0;
BA_ "VFrameFormat" BO_ 869 14;
BA_ "GenMsgCycleTime" BO_ 1442 500;
BA_ "GenMsgCycleTimeFast" BO_ 1442 100;
BA_ "GenMsgDelayTime" BO_ 1442 20;
BA_ "GenMsgILSupport" BO_ 1442 1;
BA_ "GenMsgNrOfRepetition" BO_ 1442 5;
BA_ "GenMsgPDUConstants" BO_ 1442 "0xeb,0x4c,0x44,0xaf,0x21,0x8d,0x01,0x58,0xfa,0x93,0xdb,0x89,0x15,0x10,0x4a,0x61";
BA_ "GenMsgSendType" BO_ 1442 0;
BA_ "VFrameFormat" BO_ 1442 14;
BA_ "GenMsgCycleTime" BO_ 2527679654 200;
BA_ "GenMsgILSupport" BO_ 2527679654 1;
BA_ "GenMsgPDUConstants" BO_ 2527679654 "0x79,0xb9,0x67,0xad,0xd5,0xf7,0x70,0xaa,0x44,0x61,0x5a,0xdc,0x26,0xb4,0xd2,0xc3";
BA_ "GenMsgSendType" BO_ 2527679654 0;
BA_ "VFrameFormat" BO_ 2527679654 15;
BA_ "GenMsgCycleTime" BO_ 207 10;
BA_ "GenMsgILSupport" BO_ 207 1;
BA_ "GenMsgPDUConstants" BO_ 207 "0xee,0x80,0x6e,0x4e,0x29,0xc6,0x92,0xc0,0x65,0xaa,0x3a,0xa1,0x8f,0xcd,0xe6,0x90";
BA_ "GenMsgSendType" BO_ 207 0;
BA_ "VFrameFormat" BO_ 207 14;
BA_ "GenMsgCycleTime" BO_ 2463978704 100;
BA_ "GenMsgILSupport" BO_ 2463978704 1;
BA_ "GenMsgSendType" BO_ 2463978704 0;
BA_ "VFrameFormat" BO_ 2463978704 15;
BA_ "GenMsgCycleTime" BO_ 2463978705 100;
BA_ "GenMsgILSupport" BO_ 2463978705 1;
BA_ "GenMsgSendType" BO_ 2463978705 0;
BA_ "VFrameFormat" BO_ 2463978705 15;
BA_ "GenMsgCycleTime" BO_ 2589283664 500;
BA_ "GenMsgILSupport" BO_ 2589283664 1;
BA_ "GenMsgSendType" BO_ 2589283664 0;
BA_ "VFrameFormat" BO_ 2589283664 15;
BA_ "GenMsgCycleTime" BO_ 2589283665 500;
BA_ "GenMsgILSupport" BO_ 2589283665 1;
BA_ "GenMsgSendType" BO_ 2589283665 0;
BA_ "VFrameFormat" BO_ 2589283665 15;
BA_ "GenMsgCycleTime" BO_ 2589283760 1000;
BA_ "GenMsgILSupport" BO_ 2589283760 1;
BA_ "GenMsgSendType" BO_ 2589283760 0;
BA_ "VFrameFormat" BO_ 2589283760 15;
BA_ "GenMsgCycleTime" BO_ 2463978646 1000;
BA_ "GenMsgDelayTime" BO_ 2463978646 50;
BA_ "GenMsgILSupport" BO_ 2463978646 1;
BA_ "GenMsgSendType" BO_ 2463978646 0;
BA_ "VFrameFormat" BO_ 2463978646 15;
BA_ "GenSigSendType" SG_ 333 ACC_18_BZ 0;
BA_ "GenSigFuncType" SG_ 333 ACC_18_BZ 1;
BA_ "GenSigSwitchedByIgnition" SG_ 333 ACC_18_BZ 0;
BA_ "GenSigSendType" SG_ 333 ACC_18_CRC 0;
BA_ "GenSigFuncType" SG_ 333 ACC_18_CRC 2;
BA_ "GenSigSwitchedByIgnition" SG_ 333 ACC_18_CRC 0;
BA_ "GenSigSendType" SG_ 333 ACC_Anfahren 0;
BA_ "GenSigSendType" SG_ 333 ACC_Anforderung_HMS 0;
BA_ "GenSigSendType" SG_ 333 ACC_Anhalten 0;
BA_ "GenSigSendType" SG_ 333 ACC_Anhalteweg 0;
BA_ "GenSigStartValue" SG_ 333 ACC_Anhalteweg 2046;
BA_ "Fehlerwert" SG_ 333 ACC_Anhalteweg 2047;
BA_ "GenSigSendType" SG_ 333 ACC_Boost 0;
BA_ "GenSigSendType" SG_ 333 ACC_DynErhoehung 0;
BA_ "GenSigSendType" SG_ 333 ACC_FoD_Status 0;
BA_ "GenSigSendType" SG_ 333 ACC_Folgebeschl 0;
BA_ "GenSigStartValue" SG_ 333 ACC_Folgebeschl 254;
BA_ "GenSigSendType" SG_ 333 ACC_Freilauf_Anf 0;
BA_ "GenSigSendType" SG_ 333 ACC_Freilauf_Info 0;
BA_ "GenSigSendType" SG_ 333 ACC_Freilaufstrategie_TSK 0;
BA_ "GenSigSendType" SG_ 333 ACC_limitierte_Anfahrdyn 0;
BA_ "GenSigSendType" SG_ 333 ACC_Minimale_Bremsung 0;
BA_ "GenSigSendType" SG_ 333 ACC_nachtr_Stopp_Anf 0;
BA_ "GenSigSwitchedByIgnition" SG_ 333 ACC_nachtr_Stopp_Anf 0;
BA_ "GenSigSendType" SG_ 333 ACC_neg_Sollbeschl_Grad_02 0;
BA_ "GenSigSendType" SG_ 333 ACC_pos_Sollbeschl_Grad_02 0;
BA_ "GenSigSendType" SG_ 333 ACC_Sollbeschleunigung_02 0;
BA_ "GenSigStartValue" SG_ 333 ACC_Sollbeschleunigung_02 2046;
BA_ "Fehlerwert" SG_ 333 ACC_Sollbeschleunigung_02 2047;
BA_ "GenSigSendType" SG_ 333 ACC_StartStopp_Info 0;
BA_ "GenSigSendType" SG_ 333 ACC_Status_ACC 0;
BA_ "GenSigSendType" SG_ 333 ACC_Tempolimitassistent_Ein 0;
BA_ "GenSigSendType" SG_ 333 ACC_Typ 0;
BA_ "GenSigFuncType" SG_ 333 ACC_Typ 8;
BA_ "GenSigSendType" SG_ 333 ACC_zul_Regelabw_oben 0;
BA_ "GenSigSendType" SG_ 333 ACC_zul_Regelabw_unten 0;
BA_ "GenSigSendType" SG_ 333 RDR_v_ueber_Grund 0;
BA_ "GenSigStartValue" SG_ 333 RDR_v_ueber_Grund 4091;
BA_ "Fehlerwert" SG_ 333 RDR_v_ueber_Grund 4093;
BA_ "GenSigSendType" SG_ 333 RDR_v_ueber_Grund_Fahrtrichtung 0;
BA_ "GenSigStartValue" SG_ 333 RDR_v_ueber_Grund_Fahrtrichtung 2;
BA_ "GenSigSendType" SG_ 333 RDR_v_ueber_Grund_Genauigkeit 0;
BA_ "GenSigStartValue" SG_ 333 RDR_v_ueber_Grund_Genauigkeit 62;
BA_ "Fehlerwert" SG_ 333 RDR_v_ueber_Grund_Genauigkeit 63;
BA_ "GenSigSendType" SG_ 333 vESC_Verz_Anf 0;
BA_ "GenSigStartValue" SG_ 333 vESC_Verz_Anf 9;
BA_ "Fehlerwert" SG_ 333 vESC_Verz_Anf 10;
BA_ "GenSigSendType" SG_ 2527679682 ACC_ASM_Data_1 0;
BA_ "GenSigSendType" SG_ 2527679682 ACC_ASM_Data_2 0;
BA_ "GenSigSendType" SG_ 2527679682 ACC_ASM_Data_3 0;
BA_ "GenSigSendType" SG_ 2527679682 ACC_ASM_Data_4 0;
BA_ "GenSigSendType" SG_ 2527679682 ACC_ASM_Data_5 0;
BA_ "GenSigSendType" SG_ 2527679682 ACC_ASM_Data_6 0;
BA_ "GenSigSendType" SG_ 2527679682 ACC_ASM_Ereignis 3;
BA_ "GenSigSendType" SG_ 2527679682 ACC_ASM_Zeitstempel 3;
BA_ "GenSigStartValue" SG_ 2527679682 ACC_ASM_Zeitstempel 255;
BA_ "GenSigSendType" SG_ 64 AB_Anzeige_Fussg 0;
BA_ "GenSigSwitchedByIgnition" SG_ 64 AB_Anzeige_Fussg 0;
BA_ "GenSigSendType" SG_ 64 AB_Belegung_VF 0;
BA_ "GenSigSwitchedByIgnition" SG_ 64 AB_Belegung_VF 0;
BA_ "Fehlerwert" SG_ 64 AB_Belegung_VF 1;
BA_ "GenSigSendType" SG_ 64 AB_Belegung_VF_ext 3;
BA_ "GenSigStartValue" SG_ 64 AB_Belegung_VF_ext 6;
BA_ "GenSigSwitchedByIgnition" SG_ 64 AB_Belegung_VF_ext 0;
BA_ "Fehlerwert" SG_ 64 AB_Belegung_VF_ext 7;
BA_ "GenSigSendType" SG_ 64 AB_Crash_Int 4;
BA_ "GenSigSwitchedByIgnition" SG_ 64 AB_Crash_Int 0;
BA_ "GenSigSendType" SG_ 64 AB_Deaktiviert 0;
BA_ "GenSigSwitchedByIgnition" SG_ 64 AB_Deaktiviert 0;
BA_ "GenSigSendType" SG_ 64 AB_Deaktivierung_HV 4;
BA_ "GenSigSwitchedByIgnition" SG_ 64 AB_Deaktivierung_HV 0;
BA_ "Fehlerwert" SG_ 64 AB_Deaktivierung_HV 7;
BA_ "GenSigSendType" SG_ 64 AB_Diagnose 0;
BA_ "GenSigSwitchedByIgnition" SG_ 64 AB_Diagnose 0;
BA_ "GenSigSendType" SG_ 64 AB_EDR_Trigger 3;
BA_ "GenSigSwitchedByIgnition" SG_ 64 AB_EDR_Trigger 0;
BA_ "GenSigSendType" SG_ 64 AB_Erh_Auf_VB 0;
BA_ "GenSigSwitchedByIgnition" SG_ 64 AB_Erh_Auf_VB 0;
BA_ "GenSigSendType" SG_ 64 AB_Front_Crash 4;
BA_ "GenSigSwitchedByIgnition" SG_ 64 AB_Front_Crash 0;
BA_ "GenSigSendType" SG_ 64 AB_Gurtschloss_FA_ext 3;
BA_ "GenSigStartValue" SG_ 64 AB_Gurtschloss_FA_ext 6;
BA_ "GenSigSwitchedByIgnition" SG_ 64 AB_Gurtschloss_FA_ext 0;
BA_ "Fehlerwert" SG_ 64 AB_Gurtschloss_FA_ext 7;
BA_ "GenSigSendType" SG_ 64 AB_Gurtwarn_VB 0;
BA_ "GenSigSwitchedByIgnition" SG_ 64 AB_Gurtwarn_VB 0;
BA_ "GenSigSendType" SG_ 64 AB_Gurtwarn_VF 0;
BA_ "GenSigSwitchedByIgnition" SG_ 64 AB_Gurtwarn_VF 0;
BA_ "GenSigSendType" SG_ 64 AB_Heck_Crash 4;
BA_ "GenSigSwitchedByIgnition" SG_ 64 AB_Heck_Crash 0;
BA_ "GenSigSendType" SG_ 64 AB_Lampe 0;
BA_ "GenSigStartValue" SG_ 64 AB_Lampe 1;
BA_ "GenSigSwitchedByIgnition" SG_ 64 AB_Lampe 0;
BA_ "GenSigSendType" SG_ 64 AB_MKB_Anforderung 4;
BA_ "GenSigSwitchedByIgnition" SG_ 64 AB_MKB_Anforderung 0;
BA_ "GenSigSendType" SG_ 64 AB_MKB_gueltig 0;
BA_ "GenSigSwitchedByIgnition" SG_ 64 AB_MKB_gueltig 0;
BA_ "GenSigSendType" SG_ 64 AB_PAO_Leuchte_Anf 0;
BA_ "GenSigStartValue" SG_ 64 AB_PAO_Leuchte_Anf 1;
BA_ "GenSigSwitchedByIgnition" SG_ 64 AB_PAO_Leuchte_Anf 0;
BA_ "GenSigSendType" SG_ 64 AB_RGS_Anst 3;
BA_ "GenSigStartValue" SG_ 64 AB_RGS_Anst 8;
BA_ "GenSigSwitchedByIgnition" SG_ 64 AB_RGS_Anst 0;
BA_ "GenSigSendType" SG_ 64 AB_Rollover_Crash 4;
BA_ "GenSigSwitchedByIgnition" SG_ 64 AB_Rollover_Crash 0;
BA_ "GenSigSendType" SG_ 64 AB_SB_Crash 4;
BA_ "GenSigSwitchedByIgnition" SG_ 64 AB_SB_Crash 0;
BA_ "GenSigSendType" SG_ 64 AB_SF_Crash 4;
BA_ "GenSigSwitchedByIgnition" SG_ 64 AB_SF_Crash 0;
BA_ "GenSigSendType" SG_ 64 AB_Stellgliedtest 0;
BA_ "GenSigSwitchedByIgnition" SG_ 64 AB_Stellgliedtest 0;
BA_ "GenSigSendType" SG_ 64 AB_Systemfehler 0;
BA_ "GenSigSwitchedByIgnition" SG_ 64 AB_Systemfehler 0;
BA_ "GenSigSendType" SG_ 64 AB_Texte_AKS 0;
BA_ "GenSigSwitchedByIgnition" SG_ 64 AB_Texte_AKS 0;
BA_ "GenSigSendType" SG_ 64 AB_VB_deaktiviert 0;
BA_ "GenSigStartValue" SG_ 64 AB_VB_deaktiviert 1;
BA_ "GenSigSwitchedByIgnition" SG_ 64 AB_VB_deaktiviert 0;
BA_ "GenSigSendType" SG_ 64 AB_Versorgungsspannung 0;
BA_ "GenSigSwitchedByIgnition" SG_ 64 AB_Versorgungsspannung 0;
BA_ "GenSigSendType" SG_ 64 Airbag_01_BZ 0;
BA_ "GenSigFuncType" SG_ 64 Airbag_01_BZ 1;
BA_ "GenSigSwitchedByIgnition" SG_ 64 Airbag_01_BZ 0;
BA_ "GenSigSendType" SG_ 64 Airbag_01_CRC 0;
BA_ "GenSigFuncType" SG_ 64 Airbag_01_CRC 2;
BA_ "GenSigSwitchedByIgnition" SG_ 64 Airbag_01_CRC 0;
BA_ "GenSigSendType" SG_ 64 ASM_Masterzeit 0;
BA_ "GenSigStartValue" SG_ 64 ASM_Masterzeit 255;
BA_ "GenSigSwitchedByIgnition" SG_ 64 ASM_Masterzeit 0;
BA_ "GenSigSendType" SG_ 1312 AB_Abschaltanf_SIH_BF 3;
BA_ "GenSigSendType" SG_ 1312 AB_Anforderung_eCall 0;
BA_ "GenSigSwitchedByIgnition" SG_ 1312 AB_Anforderung_eCall 0;
BA_ "GenSigSendType" SG_ 1312 AB_Anforderung_USM 0;
BA_ "GenSigSwitchedByIgnition" SG_ 1312 AB_Anforderung_USM 0;
BA_ "GenSigSendType" SG_ 1312 AB_Anprall_FGS 3;
BA_ "GenSigSendType" SG_ 1312 AB_Anprall_Front_Beifahrer 3;
BA_ "GenSigSendType" SG_ 1312 AB_Anprall_Front_Fahrer 3;
BA_ "GenSigSendType" SG_ 1312 AB_Anprall_Heck_Beifahrer 3;
BA_ "GenSigSendType" SG_ 1312 AB_Anprall_Heck_Fahrer 3;
BA_ "GenSigSendType" SG_ 1312 AB_Anprall_Rollover 3;
BA_ "GenSigSendType" SG_ 1312 AB_Anprall_Seite_Beifahrer 3;
BA_ "GenSigSendType" SG_ 1312 AB_Anprall_Seite_Fahrer 3;
BA_ "GenSigSendType" SG_ 1312 AB_Belegung_VB 0;
BA_ "GenSigSwitchedByIgnition" SG_ 1312 AB_Belegung_VB 0;
BA_ "Fehlerwert" SG_ 1312 AB_Belegung_VB 1;
BA_ "GenSigSendType" SG_ 1312 AB_Crashschwere 3;
BA_ "GenSigSwitchedByIgnition" SG_ 1312 AB_Crashschwere 0;
BA_ "Fehlerwert" SG_ 1312 AB_Crashschwere 7;
BA_ "GenSigSendType" SG_ 1312 AB_Gurtschloss_BF 3;
BA_ "GenSigStartValue" SG_ 1312 AB_Gurtschloss_BF 1;
BA_ "GenSigSwitchedByIgnition" SG_ 1312 AB_Gurtschloss_BF 0;
BA_ "GenSigSendType" SG_ 1312 AB_Gurtschloss_FA 3;
BA_ "GenSigStartValue" SG_ 1312 AB_Gurtschloss_FA 1;
BA_ "GenSigSwitchedByIgnition" SG_ 1312 AB_Gurtschloss_FA 0;
BA_ "GenSigSendType" SG_ 1312 AB_Gurtschloss_Reihe2_BF 3;
BA_ "GenSigStartValue" SG_ 1312 AB_Gurtschloss_Reihe2_BF 1;
BA_ "GenSigSwitchedByIgnition" SG_ 1312 AB_Gurtschloss_Reihe2_BF 0;
BA_ "GenSigSendType" SG_ 1312 AB_Gurtschloss_Reihe2_FA 3;
BA_ "GenSigStartValue" SG_ 1312 AB_Gurtschloss_Reihe2_FA 1;
BA_ "GenSigSwitchedByIgnition" SG_ 1312 AB_Gurtschloss_Reihe2_FA 0;
BA_ "GenSigSendType" SG_ 1312 AB_Gurtschloss_Reihe2_MI 3;
BA_ "GenSigStartValue" SG_ 1312 AB_Gurtschloss_Reihe2_MI 1;
BA_ "GenSigSwitchedByIgnition" SG_ 1312 AB_Gurtschloss_Reihe2_MI 0;
BA_ "GenSigSendType" SG_ 1312 AB_Gurtschloss_Reihe3_BF 3;
BA_ "GenSigStartValue" SG_ 1312 AB_Gurtschloss_Reihe3_BF 1;
BA_ "GenSigSwitchedByIgnition" SG_ 1312 AB_Gurtschloss_Reihe3_BF 0;
BA_ "GenSigSendType" SG_ 1312 AB_Gurtschloss_Reihe3_FA 3;
BA_ "GenSigStartValue" SG_ 1312 AB_Gurtschloss_Reihe3_FA 1;
BA_ "GenSigSwitchedByIgnition" SG_ 1312 AB_Gurtschloss_Reihe3_FA 0;
BA_ "GenSigSendType" SG_ 1312 AB_Gurtschloss_Reihe3_MI 3;
BA_ "GenSigStartValue" SG_ 1312 AB_Gurtschloss_Reihe3_MI 1;
BA_ "GenSigSwitchedByIgnition" SG_ 1312 AB_Gurtschloss_Reihe3_MI 0;
BA_ "GenSigSendType" SG_ 1312 AB_Sitzpos_Sens_BF 0;
BA_ "GenSigSwitchedByIgnition" SG_ 1312 AB_Sitzpos_Sens_BF 0;
BA_ "Fehlerwert" SG_ 1312 AB_Sitzpos_Sens_BF 1;
BA_ "GenSigSendType" SG_ 1312 AB_Sitzpos_Sens_FA 0;
BA_ "GenSigSwitchedByIgnition" SG_ 1312 AB_Sitzpos_Sens_FA 0;
BA_ "Fehlerwert" SG_ 1312 AB_Sitzpos_Sens_FA 1;
BA_ "GenSigSendType" SG_ 1312 AB_Wickelklappung_Reihe2_BF 3;
BA_ "GenSigStartValue" SG_ 1312 AB_Wickelklappung_Reihe2_BF 1;
BA_ "GenSigSwitchedByIgnition" SG_ 1312 AB_Wickelklappung_Reihe2_BF 0;
BA_ "GenSigSendType" SG_ 1312 AB_Wickelklappung_Reihe2_FA 3;
BA_ "GenSigStartValue" SG_ 1312 AB_Wickelklappung_Reihe2_FA 1;
BA_ "GenSigSwitchedByIgnition" SG_ 1312 AB_Wickelklappung_Reihe2_FA 0;
BA_ "GenSigSendType" SG_ 1312 AB_Wickelklappung_Reihe2_MI 3;
BA_ "GenSigStartValue" SG_ 1312 AB_Wickelklappung_Reihe2_MI 1;
BA_ "GenSigSwitchedByIgnition" SG_ 1312 AB_Wickelklappung_Reihe2_MI 0;
BA_ "GenSigSendType" SG_ 1312 Airbag_02_BZ 0;
BA_ "GenSigFuncType" SG_ 1312 Airbag_02_BZ 1;
BA_ "GenSigSwitchedByIgnition" SG_ 1312 Airbag_02_BZ 0;
BA_ "GenSigSendType" SG_ 1312 Airbag_02_CRC 0;
BA_ "GenSigFuncType" SG_ 1312 Airbag_02_CRC 2;
BA_ "GenSigSwitchedByIgnition" SG_ 1312 Airbag_02_CRC 0;
BA_ "GenSigSendType" SG_ 1312 LoGeWa_Event_Kombiwarnung 3;
BA_ "GenSigSwitchedByIgnition" SG_ 1312 LoGeWa_Event_Kombiwarnung 0;
BA_ "GenSigSendType" SG_ 1312 SC_PAO_OFF_Anf 3;
BA_ "GenSigSwitchedByIgnition" SG_ 1312 SC_PAO_OFF_Anf 0;
BA_ "GenSigSendType" SG_ 1312 SC_PAO_ON_Anf 3;
BA_ "GenSigSwitchedByIgnition" SG_ 1312 SC_PAO_ON_Anf 0;
BA_ "GenSigSendType" SG_ 1312 SC_PAO_Schriftzug_Anf 3;
BA_ "GenSigSwitchedByIgnition" SG_ 1312 SC_PAO_Schriftzug_Anf 0;
BA_ "GenSigSendType" SG_ 65 AB_MKB_Safing 4;
BA_ "GenSigSwitchedByIgnition" SG_ 65 AB_MKB_Safing 0;
BA_ "GenSigSendType" SG_ 65 Airbag_03_BZ 0;
BA_ "GenSigFuncType" SG_ 65 Airbag_03_BZ 1;
BA_ "GenSigSwitchedByIgnition" SG_ 65 Airbag_03_BZ 0;
BA_ "GenSigSendType" SG_ 65 Airbag_03_CRC 0;
BA_ "GenSigFuncType" SG_ 65 Airbag_03_CRC 2;
BA_ "GenSigSwitchedByIgnition" SG_ 65 Airbag_03_CRC 0;
BA_ "GenSigSendType" SG_ 1349 AB_Gurtwarn_Reihe2_BF 0;
BA_ "GenSigSwitchedByIgnition" SG_ 1349 AB_Gurtwarn_Reihe2_BF 0;
BA_ "GenSigSendType" SG_ 1349 AB_Gurtwarn_Reihe2_FA 0;
BA_ "GenSigSwitchedByIgnition" SG_ 1349 AB_Gurtwarn_Reihe2_FA 0;
BA_ "GenSigSendType" SG_ 1349 AB_Gurtwarn_Reihe2_MI 0;
BA_ "GenSigSwitchedByIgnition" SG_ 1349 AB_Gurtwarn_Reihe2_MI 0;
BA_ "GenSigSendType" SG_ 1349 AB_Gurtwarn_Reihe3_BF 0;
BA_ "GenSigSwitchedByIgnition" SG_ 1349 AB_Gurtwarn_Reihe3_BF 0;
BA_ "GenSigSendType" SG_ 1349 AB_Gurtwarn_Reihe3_FA 0;
BA_ "GenSigSwitchedByIgnition" SG_ 1349 AB_Gurtwarn_Reihe3_FA 0;
BA_ "GenSigSendType" SG_ 1349 AB_Gurtwarn_Reihe3_MI 0;
BA_ "GenSigSwitchedByIgnition" SG_ 1349 AB_Gurtwarn_Reihe3_MI 0;
BA_ "GenSigSendType" SG_ 1349 AB_Gurtwarn_Reihe4_BF 0;
BA_ "GenSigSwitchedByIgnition" SG_ 1349 AB_Gurtwarn_Reihe4_BF 0;
BA_ "GenSigSendType" SG_ 1349 AB_Gurtwarn_Reihe4_FA 0;
BA_ "GenSigSwitchedByIgnition" SG_ 1349 AB_Gurtwarn_Reihe4_FA 0;
BA_ "GenSigSendType" SG_ 1349 AB_Gurtwarn_Reihe4_MI 0;
BA_ "GenSigSwitchedByIgnition" SG_ 1349 AB_Gurtwarn_Reihe4_MI 0;
BA_ "GenSigSendType" SG_ 1349 AB_SBR_hinten_verbau 0;
BA_ "GenSigStartValue" SG_ 1349 AB_SBR_hinten_verbau 3;
BA_ "GenSigSwitchedByIgnition" SG_ 1349 AB_SBR_hinten_verbau 0;
BA_ "GenSigSendType" SG_ 1349 AbstWarn_MV_FAS_Fkt_Status 3;
BA_ "GenSigSwitchedByIgnition" SG_ 1349 AbstWarn_MV_FAS_Fkt_Status 0;
BA_ "Fehlerwert" SG_ 1349 AbstWarn_MV_FAS_Fkt_Status 3;
BA_ "GenSigSendType" SG_ 1349 AWV_Einstellung_System_ASG 3;
BA_ "GenSigSwitchedByIgnition" SG_ 1349 AWV_Einstellung_System_ASG 0;
BA_ "GenSigSendType" SG_ 1349 AWV_Einstellung_Warnung_ASG 3;
BA_ "GenSigSwitchedByIgnition" SG_ 1349 AWV_Einstellung_Warnung_ASG 0;
BA_ "GenSigSendType" SG_ 1349 LGI_FAS_Fkt_Status 3;
BA_ "GenSigSwitchedByIgnition" SG_ 1349 LGI_FAS_Fkt_Status 0;
BA_ "Fehlerwert" SG_ 1349 LGI_FAS_Fkt_Status 3;
BA_ "GenSigSendType" SG_ 1349 PreCrash_FAS_Fkt_Status 3;
BA_ "GenSigSwitchedByIgnition" SG_ 1349 PreCrash_FAS_Fkt_Status 0;
BA_ "Fehlerwert" SG_ 1349 PreCrash_FAS_Fkt_Status 3;
BA_ "GenSigSendType" SG_ 1349 SC_PreSense_Modus_System_KAS 3;
BA_ "GenSigSwitchedByIgnition" SG_ 1349 SC_PreSense_Modus_System_KAS 0;
BA_ "GenSigSendType" SG_ 1349 SC_PreSense_Modus_System_MV 3;
BA_ "GenSigSwitchedByIgnition" SG_ 1349 SC_PreSense_Modus_System_MV 0;
BA_ "GenSigSendType" SG_ 1349 SC_PreSense_Modus_System_NV 3;
BA_ "GenSigSwitchedByIgnition" SG_ 1349 SC_PreSense_Modus_System_NV 0;
BA_ "GenSigSendType" SG_ 1349 SC_PreSense_Modus_Warnung_MV 3;
BA_ "GenSigSwitchedByIgnition" SG_ 1349 SC_PreSense_Modus_Warnung_MV 0;
BA_ "GenSigSendType" SG_ 1349 SC_PreSense_Modus_Warnung_NV 3;
BA_ "GenSigSwitchedByIgnition" SG_ 1349 SC_PreSense_Modus_Warnung_NV 0;
BA_ "GenSigSendType" SG_ 1349 WarnBrems_Charisma_FahrPr 0;
BA_ "GenSigSendType" SG_ 1349 WarnBrems_Charisma_Status 0;
BA_ "GenSigSendType" SG_ 2527679722 AB_Gurtschloss_Reihe4_BF 0;
BA_ "GenSigStartValue" SG_ 2527679722 AB_Gurtschloss_Reihe4_BF 1;
BA_ "GenSigSwitchedByIgnition" SG_ 2527679722 AB_Gurtschloss_Reihe4_BF 0;
BA_ "GenSigSendType" SG_ 2527679722 AB_Gurtschloss_Reihe4_FA 0;
BA_ "GenSigStartValue" SG_ 2527679722 AB_Gurtschloss_Reihe4_FA 1;
BA_ "GenSigSwitchedByIgnition" SG_ 2527679722 AB_Gurtschloss_Reihe4_FA 0;
BA_ "GenSigSendType" SG_ 2527679722 AB_Gurtschloss_Reihe4_MI 0;
BA_ "GenSigStartValue" SG_ 2527679722 AB_Gurtschloss_Reihe4_MI 1;
BA_ "GenSigSwitchedByIgnition" SG_ 2527679722 AB_Gurtschloss_Reihe4_MI 0;
BA_ "GenSigSendType" SG_ 1633 AAG_Anhaenger_abgesteckt 0;
BA_ "GenSigSwitchedByIgnition" SG_ 1633 AAG_Anhaenger_abgesteckt 0;
BA_ "GenSigSendType" SG_ 1633 AAG_Anhaenger_erkannt 0;
BA_ "NWM-WakeupAllowed" SG_ 1633 AAG_Anhaenger_erkannt 1;
BA_ "GenSigSwitchedByIgnition" SG_ 1633 AAG_Anhaenger_erkannt 0;
BA_ "GenSigSendType" SG_ 1633 AAG_AVS_Fehler_02 0;
BA_ "GenSigSwitchedByIgnition" SG_ 1633 AAG_AVS_Fehler_02 0;
BA_ "Fehlerwert" SG_ 1633 AAG_AVS_Fehler_02 1;
BA_ "GenSigSendType" SG_ 1633 AAG_AVS_Fehler_02_inv 0;
BA_ "GenSigStartValue" SG_ 1633 AAG_AVS_Fehler_02_inv 1;
BA_ "GenSigSwitchedByIgnition" SG_ 1633 AAG_AVS_Fehler_02_inv 0;
BA_ "GenSigSendType" SG_ 1633 AAG_AVS_Stati 0;
BA_ "GenSigSwitchedByIgnition" SG_ 1633 AAG_AVS_Stati 0;
BA_ "GenSigSendType" SG_ 1633 AAG_Blinker_H_aktiv 0;
BA_ "GenSigSwitchedByIgnition" SG_ 1633 AAG_Blinker_H_aktiv 0;
BA_ "GenSigSendType" SG_ 1633 AAG_Blinker_HL_def 0;
BA_ "GenSigSwitchedByIgnition" SG_ 1633 AAG_Blinker_HL_def 0;
BA_ "GenSigSendType" SG_ 1633 AAG_Blinker_HR_def 0;
BA_ "GenSigSwitchedByIgnition" SG_ 1633 AAG_Blinker_HR_def 0;
BA_ "GenSigSendType" SG_ 1633 AAG_Bremsl_durch_ECD 0;
BA_ "GenSigSwitchedByIgnition" SG_ 1633 AAG_Bremsl_durch_ECD 0;
BA_ "GenSigSendType" SG_ 1633 AAG_Bremslicht_H_def 0;
BA_ "GenSigSwitchedByIgnition" SG_ 1633 AAG_Bremslicht_H_def 0;
BA_ "GenSigSendType" SG_ 1633 AAG_Bremslicht_Reku 0;
BA_ "GenSigSwitchedByIgnition" SG_ 1633 AAG_Bremslicht_Reku 0;
BA_ "GenSigSendType" SG_ 1633 AAG_BZ 0;
BA_ "GenSigFuncType" SG_ 1633 AAG_BZ 1;
BA_ "GenSigSwitchedByIgnition" SG_ 1633 AAG_BZ 0;
BA_ "GenSigSendType" SG_ 1633 AAG_LED_aktiv 0;
BA_ "GenSigSwitchedByIgnition" SG_ 1633 AAG_LED_aktiv 0;
BA_ "GenSigSendType" SG_ 1633 AAG_NSL_aktiv 0;
BA_ "GenSigSwitchedByIgnition" SG_ 1633 AAG_NSL_aktiv 0;
BA_ "GenSigSendType" SG_ 1633 AAG_Schlusslicht_HL_def 0;
BA_ "GenSigSwitchedByIgnition" SG_ 1633 AAG_Schlusslicht_HL_def 0;
BA_ "GenSigSendType" SG_ 1633 AAG_Schlusslicht_HR_def 0;
BA_ "GenSigSwitchedByIgnition" SG_ 1633 AAG_Schlusslicht_HR_def 0;
BA_ "GenSigSendType" SG_ 345 ARA_Aktiver_Grafikmodus 0;
BA_ "GenSigSendType" SG_ 345 ARA_Anf_Meldungen 0;
BA_ "GenSigSendType" SG_ 345 ARA_Bremsfuss 0;
BA_ "GenSigSendType" SG_ 345 ARA_Deaktivierung_sperren 3;
BA_ "GenSigSendType" SG_ 345 ARA_Knickwinkel_Ist 3;
BA_ "GenSigStartValue" SG_ 345 ARA_Knickwinkel_Ist 254;
BA_ "Fehlerwert" SG_ 345 ARA_Knickwinkel_Ist 255;
BA_ "GenSigSendType" SG_ 345 ARA_Knickwinkel_Komfort 3;
BA_ "GenSigStartValue" SG_ 345 ARA_Knickwinkel_Komfort 62;
BA_ "GenSigSendType" SG_ 345 ARA_Knickwinkel_konfidenz 0;
BA_ "GenSigStartValue" SG_ 345 ARA_Knickwinkel_konfidenz 126;
BA_ "Fehlerwert" SG_ 345 ARA_Knickwinkel_konfidenz 127;
BA_ "GenSigSendType" SG_ 345 ARA_Knickwinkel_Max 3;
BA_ "GenSigStartValue" SG_ 345 ARA_Knickwinkel_Max 126;
BA_ "Fehlerwert" SG_ 345 ARA_Knickwinkel_Max 127;
BA_ "GenSigSendType" SG_ 345 ARA_Knickwinkel_Soll 3;
BA_ "GenSigStartValue" SG_ 345 ARA_Knickwinkel_Soll 254;
BA_ "Fehlerwert" SG_ 345 ARA_Knickwinkel_Soll 255;
BA_ "GenSigSendType" SG_ 345 ARA_Modus 0;
BA_ "GenSigSendType" SG_ 345 ARA_Modus_Anf 0;
BA_ "GenSigSendType" SG_ 345 ARA_Sensor_Aktivierung 3;
BA_ "GenSigSendType" SG_ 345 ARA_Status 3;
BA_ "GenSigStartValue" SG_ 345 ARA_Status 1;
BA_ "Fehlerwert" SG_ 345 ARA_Status 2;
BA_ "GenSigSendType" SG_ 345 ARA_Texte 0;
BA_ "Fehlerwert" SG_ 345 ARA_Texte 63;
BA_ "GenSigSendType" SG_ 2589283607 AWC_01_BZ 0;
BA_ "GenSigFuncType" SG_ 2589283607 AWC_01_BZ 1;
BA_ "GenSigSwitchedByIgnition" SG_ 2589283607 AWC_01_BZ 0;
BA_ "GenSigSendType" SG_ 2589283607 AWC_01_CRC 0;
BA_ "GenSigFuncType" SG_ 2589283607 AWC_01_CRC 2;
BA_ "GenSigSwitchedByIgnition" SG_ 2589283607 AWC_01_CRC 0;
BA_ "GenSigSendType" SG_ 2589283607 AWC_Fehlerstatus 3;
BA_ "GenSigStartValue" SG_ 2589283607 AWC_Fehlerstatus 7;
BA_ "GenSigSwitchedByIgnition" SG_ 2589283607 AWC_Fehlerstatus 0;
BA_ "GenSigSendType" SG_ 2589283607 AWC_IstModus 3;
BA_ "GenSigStartValue" SG_ 2589283607 AWC_IstModus 6;
BA_ "GenSigSwitchedByIgnition" SG_ 2589283607 AWC_IstModus 0;
BA_ "GenSigSendType" SG_ 2589283607 AWC_IstSpannung 0;
BA_ "GenSigStartValue" SG_ 2589283607 AWC_IstSpannung 1022;
BA_ "GenSigSwitchedByIgnition" SG_ 2589283607 AWC_IstSpannung 0;
BA_ "Fehlerwert" SG_ 2589283607 AWC_IstSpannung 1023;
BA_ "GenSigSendType" SG_ 2589283607 AWC_IstStrom 0;
BA_ "GenSigStartValue" SG_ 2589283607 AWC_IstStrom 510;
BA_ "GenSigSwitchedByIgnition" SG_ 2589283607 AWC_IstStrom 0;
BA_ "Fehlerwert" SG_ 2589283607 AWC_IstStrom 511;
BA_ "GenSigSendType" SG_ 2589283607 AWC_MaxLadLeistung 0;
BA_ "GenSigStartValue" SG_ 2589283607 AWC_MaxLadLeistung 510;
BA_ "GenSigSwitchedByIgnition" SG_ 2589283607 AWC_MaxLadLeistung 0;
BA_ "Fehlerwert" SG_ 2589283607 AWC_MaxLadLeistung 511;
BA_ "GenSigSendType" SG_ 2589283607 AWC_Status_EoHVL 4;
BA_ "GenSigSwitchedByIgnition" SG_ 2589283607 AWC_Status_EoHVL 0;
BA_ "Fehlerwert" SG_ 2589283607 AWC_Status_EoHVL 3;
BA_ "GenSigSendType" SG_ 2589283607 AWC_Status_Spgfreiheit 4;
BA_ "GenSigSwitchedByIgnition" SG_ 2589283607 AWC_Status_Spgfreiheit 0;
BA_ "GenSigSendType" SG_ 219 AWV_03_BZ 0;
BA_ "GenSigFuncType" SG_ 219 AWV_03_BZ 1;
BA_ "GenSigSwitchedByIgnition" SG_ 219 AWV_03_BZ 0;
BA_ "GenSigSendType" SG_ 219 AWV_03_CRC 0;
BA_ "GenSigFuncType" SG_ 219 AWV_03_CRC 2;
BA_ "GenSigSwitchedByIgnition" SG_ 219 AWV_03_CRC 0;
BA_ "GenSigSendType" SG_ 219 AWV_Anf_Prefill 0;
BA_ "GenSigSendType" SG_ 219 AWV_Eingriff_Sendeart 6;
BA_ "GenSigSendType" SG_ 219 AWV_HBA_Param 0;
BA_ "GenSigSendType" SG_ 219 AWV_QFK_AnfStat 0;
BA_ "GenSigStartValue" SG_ 219 AWV_QFK_AnfStat 1;
BA_ "GenSigSendType" SG_ 219 AWV_QFK_Art1 0;
BA_ "GenSigSendType" SG_ 219 AWV_QFK_Art2 0;
BA_ "GenSigSendType" SG_ 219 AWV_QFK_KruemmSoll 0;
BA_ "GenSigSendType" SG_ 219 AWV_QFK_KruemmSoll_VZ 0;
BA_ "GenSigSendType" SG_ 219 AWV_QFK_Signal1 0;
BA_ "GenSigSendType" SG_ 219 AWV_QFK_Signal2 0;
BA_ "GenSigSendType" SG_ 219 AWV_QFK_Spuerb 0;
BA_ "GenSigSendType" SG_ 219 AWV_Ruckprofil 0;
BA_ "GenSigSendType" SG_ 219 AWV_Time_to_brake 0;
BA_ "GenSigStartValue" SG_ 219 AWV_Time_to_brake 127;
BA_ "GenSigSendType" SG_ 219 AWV_Time_to_collision 0;
BA_ "GenSigStartValue" SG_ 219 AWV_Time_to_collision 255;
BA_ "GenSigSwitchedByIgnition" SG_ 219 AWV_Time_to_collision 0;
BA_ "GenSigSendType" SG_ 219 AWV_Verz_Anf 0;
BA_ "GenSigStartValue" SG_ 219 AWV_Verz_Anf 1023;
BA_ "GenSigSendType" SG_ 219 AWV_Verz_Anf_ASIL 0;
BA_ "GenSigSendType" SG_ 219 AWV_Verz_Freigabe 0;
BA_ "GenSigSendType" SG_ 219 AWV_Zielobjekttyp 0;
BA_ "GenSigStartValue" SG_ 219 AWV_Zielobjekttyp 15;
BA_ "GenSigSendType" SG_ 219 PCF_Freigabe 0;
BA_ "GenSigSendType" SG_ 219 SDF_PSF_CU_Status 0;
BA_ "GenSigSendType" SG_ 219 SDF_PSF_CW 0;
BA_ "GenSigStartValue" SG_ 219 SDF_PSF_CW 126;
BA_ "Fehlerwert" SG_ 219 SDF_PSF_CW 127;
BA_ "GenSigSendType" SG_ 219 SDF_PSF_Fahrer_aktiv 0;
BA_ "GenSigStartValue" SG_ 219 SDF_PSF_Fahrer_aktiv 1;
BA_ "GenSigSendType" SG_ 219 SDF_PSF_Guete 0;
BA_ "GenSigSendType" SG_ 219 SDF_PSF_Kollisionsueberdeckung 0;
BA_ "GenSigStartValue" SG_ 219 SDF_PSF_Kollisionsueberdeckung 30;
BA_ "Fehlerwert" SG_ 219 SDF_PSF_Kollisionsueberdeckung 31;
BA_ "GenSigSendType" SG_ 219 SDF_PSF_Objektstatus 0;
BA_ "Fehlerwert" SG_ 219 SDF_PSF_Objektstatus 7;
BA_ "GenSigSendType" SG_ 219 SDF_PSF_Time_To_Collision 0;
BA_ "GenSigStartValue" SG_ 219 SDF_PSF_Time_To_Collision 254;
BA_ "Fehlerwert" SG_ 219 SDF_PSF_Time_To_Collision 255;
BA_ "GenSigSendType" SG_ 219 SDF_PSF_v_rel 0;
BA_ "GenSigStartValue" SG_ 219 SDF_PSF_v_rel 254;
BA_ "Fehlerwert" SG_ 219 SDF_PSF_v_rel 255;
BA_ "GenSigSendType" SG_ 2536767264 BAP_Debug_Cmd 3;
BA_ "GenSigSwitchedByIgnition" SG_ 2536767264 BAP_Debug_Cmd 0;
BA_ "GenSigSendType" SG_ 2536767280 BAP_Debug_Data 3;
BA_ "GenSigSwitchedByIgnition" SG_ 2536767280 BAP_Debug_Data 0;
BA_ "GenSigSendType" SG_ 2536717313 BAP_EfficAssist_ASG_02_Header 3;
BA_ "GenSigSwitchedByIgnition" SG_ 2536717313 BAP_EfficAssist_ASG_02_Header 0;
BA_ "GenSigSendType" SG_ 2536717314 BAP_EfficAssist_ASG_03_Header 3;
BA_ "GenSigSwitchedByIgnition" SG_ 2536717314 BAP_EfficAssist_ASG_03_Header 0;
BA_ "GenSigSendType" SG_ 2536717328 BAP_EfficAssist_FSG_01_Header 3;
BA_ "GenSigSwitchedByIgnition" SG_ 2536717328 BAP_EfficAssist_FSG_01_Header 0;
BA_ "GenSigSendType" SG_ 2536709120 BAP_Hybrid_ASG_01_Header 3;
BA_ "GenSigSwitchedByIgnition" SG_ 2536709120 BAP_Hybrid_ASG_01_Header 0;
BA_ "GenSigSendType" SG_ 2536709136 BAP_Hybrid_FSG_01_Header 3;
BA_ "GenSigSwitchedByIgnition" SG_ 2536709136 BAP_Hybrid_FSG_01_Header 0;
BA_ "GenSigSendType" SG_ 869 BEM_01_Abschaltstufen 0;
BA_ "GenSigSwitchedByIgnition" SG_ 869 BEM_01_Abschaltstufen 0;
BA_ "GenSigSendType" SG_ 869 BEM_Anf_KL 0;
BA_ "GenSigSwitchedByIgnition" SG_ 869 BEM_Anf_KL 0;
BA_ "GenSigSendType" SG_ 869 BEM_Batt_Ab 0;
BA_ "GenSigSwitchedByIgnition" SG_ 869 BEM_Batt_Ab 0;
BA_ "GenSigSendType" SG_ 869 BEM_DFM 0;
BA_ "GenSigSwitchedByIgnition" SG_ 869 BEM_DFM 0;
BA_ "GenSigSendType" SG_ 869 BEM_EMLIN_ungueltig 0;
BA_ "GenSigSwitchedByIgnition" SG_ 869 BEM_EMLIN_ungueltig 0;
BA_ "GenSigSendType" SG_ 869 BEM_HYB_DC_uMinLV 0;
BA_ "GenSigStartValue" SG_ 869 BEM_HYB_DC_uMinLV 254;
BA_ "GenSigSwitchedByIgnition" SG_ 869 BEM_HYB_DC_uMinLV 0;
BA_ "Fehlerwert" SG_ 869 BEM_HYB_DC_uMinLV 255;
BA_ "GenSigSendType" SG_ 869 BEM_HYB_DC_uSollLV 0;
BA_ "GenSigStartValue" SG_ 869 BEM_HYB_DC_uSollLV 37;
BA_ "GenSigSwitchedByIgnition" SG_ 869 BEM_HYB_DC_uSollLV 0;
BA_ "GenSigSendType" SG_ 869 BEM_n_LLA 0;
BA_ "GenSigSwitchedByIgnition" SG_ 869 BEM_n_LLA 0;
BA_ "GenSigSendType" SG_ 869 BEM_NV_NachladAnf 0;
BA_ "GenSigSwitchedByIgnition" SG_ 869 BEM_NV_NachladAnf 0;
BA_ "Fehlerwert" SG_ 869 BEM_NV_NachladAnf 3;
BA_ "GenSigSendType" SG_ 869 BEM_P_Generator 0;
BA_ "GenSigSwitchedByIgnition" SG_ 869 BEM_P_Generator 0;
BA_ "Fehlerwert" SG_ 869 BEM_P_Generator 255;
BA_ "GenSigSendType" SG_ 869 BEM_Segel_Info 0;
BA_ "GenSigSwitchedByIgnition" SG_ 869 BEM_Segel_Info 0;
BA_ "GenSigSendType" SG_ 869 BEM_StartStopp_Info 0;
BA_ "GenSigSwitchedByIgnition" SG_ 869 BEM_StartStopp_Info 0;
BA_ "GenSigSendType" SG_ 869 BEM_UBDM 0;
BA_ "GenSigSwitchedByIgnition" SG_ 869 BEM_UBDM 0;
BA_ "Fehlerwert" SG_ 869 BEM_UBDM 255;
BA_ "GenSigSendType" SG_ 869 NVEM_FMAus_I_Verbrauch 0;
BA_ "GenSigStartValue" SG_ 869 NVEM_FMAus_I_Verbrauch 30;
BA_ "GenSigSwitchedByIgnition" SG_ 869 NVEM_FMAus_I_Verbrauch 0;
BA_ "Fehlerwert" SG_ 869 NVEM_FMAus_I_Verbrauch 31;
BA_ "GenSigSendType" SG_ 869 NVEM_FMAus_Info 0;
BA_ "GenSigStartValue" SG_ 869 NVEM_FMAus_Info 1;
BA_ "GenSigSwitchedByIgnition" SG_ 869 NVEM_FMAus_Info 0;
BA_ "GenSigSendType" SG_ 869 NVEM_Freilauf_Info 0;
BA_ "GenSigSwitchedByIgnition" SG_ 869 NVEM_Freilauf_Info 0;
BA_ "GenSigSendType" SG_ 869 NVEM_Ladefreigabe 0;
BA_ "GenSigSwitchedByIgnition" SG_ 869 NVEM_Ladefreigabe 0;
BA_ "GenSigSendType" SG_ 869 NVEM_P_Generator_Status 0;
BA_ "GenSigSwitchedByIgnition" SG_ 869 NVEM_P_Generator_Status 0;
BA_ "GenSigSendType" SG_ 869 NVEM_PTC_Sollstufe 0;
BA_ "GenSigSwitchedByIgnition" SG_ 869 NVEM_PTC_Sollstufe 0;
BA_ "GenSigSendType" SG_ 1442 BMS_04_BZ 0;
BA_ "GenSigFuncType" SG_ 1442 BMS_04_BZ 1;
BA_ "GenSigSwitchedByIgnition" SG_ 1442 BMS_04_BZ 0;
BA_ "GenSigSendType" SG_ 1442 BMS_04_CRC 0;
BA_ "GenSigFuncType" SG_ 1442 BMS_04_CRC 2;
BA_ "GenSigSwitchedByIgnition" SG_ 1442 BMS_04_CRC 0;
BA_ "GenSigSendType" SG_ 1442 BMS_Fehler_Pilot 0;
BA_ "GenSigSwitchedByIgnition" SG_ 1442 BMS_Fehler_Pilot 0;
BA_ "GenSigSendType" SG_ 1442 BMS_Fehlerlampe_Anf 0;
BA_ "GenSigSwitchedByIgnition" SG_ 1442 BMS_Fehlerlampe_Anf 0;
BA_ "GenSigSendType" SG_ 1442 BMS_Fehlerstatus 3;
BA_ "GenSigStartValue" SG_ 1442 BMS_Fehlerstatus 7;
BA_ "GenSigSwitchedByIgnition" SG_ 1442 BMS_Fehlerstatus 0;
BA_ "GenSigSendType" SG_ 1442 BMS_Kapazitaet_02 0;
BA_ "GenSigStartValue" SG_ 1442 BMS_Kapazitaet_02 2047;
BA_ "GenSigSwitchedByIgnition" SG_ 1442 BMS_Kapazitaet_02 0;
BA_ "GenSigSendType" SG_ 1442 BMS_Kl30c_Status 4;
BA_ "GenSigSwitchedByIgnition" SG_ 1442 BMS_Kl30c_Status 0;
BA_ "Fehlerwert" SG_ 1442 BMS_Kl30c_Status 3;
BA_ "GenSigSendType" SG_ 1442 BMS_OBD_Lampe_Anf 0;
BA_ "GenSigSwitchedByIgnition" SG_ 1442 BMS_OBD_Lampe_Anf 0;
BA_ "GenSigSendType" SG_ 1442 BMS_Status_ServiceDisconnect 0;
BA_ "GenSigSwitchedByIgnition" SG_ 1442 BMS_Status_ServiceDisconnect 0;
BA_ "GenSigSendType" SG_ 1442 BMS_Status_Spgfreiheit 0;
BA_ "GenSigSwitchedByIgnition" SG_ 1442 BMS_Status_Spgfreiheit 0;
BA_ "GenSigSendType" SG_ 1442 BMS_Warnlampe_Anf 0;
BA_ "GenSigSwitchedByIgnition" SG_ 1442 BMS_Warnlampe_Anf 0;
BA_ "GenSigSendType" SG_ 2527679654 BMS_11_BZ 0;
BA_ "GenSigFuncType" SG_ 2527679654 BMS_11_BZ 1;
BA_ "GenSigSwitchedByIgnition" SG_ 2527679654 BMS_11_BZ 0;
BA_ "GenSigSendType" SG_ 2527679654 BMS_11_CRC 0;
BA_ "GenSigFuncType" SG_ 2527679654 BMS_11_CRC 2;
BA_ "GenSigSwitchedByIgnition" SG_ 2527679654 BMS_11_CRC 0;
BA_ "GenSigSendType" SG_ 2527679654 BMS_IsoFehler 0;
BA_ "GenSigSwitchedByIgnition" SG_ 2527679654 BMS_IsoFehler 0;
BA_ "GenSigSendType" SG_ 2527679654 BMS_IsoZustand 0;
BA_ "GenSigSwitchedByIgnition" SG_ 2527679654 BMS_IsoZustand 0;
BA_ "GenSigSendType" SG_ 2527679654 BMS_IstTemperatur_hoechste 0;
BA_ "GenSigStartValue" SG_ 2527679654 BMS_IstTemperatur_hoechste 254;
BA_ "GenSigSwitchedByIgnition" SG_ 2527679654 BMS_IstTemperatur_hoechste 0;
BA_ "Fehlerwert" SG_ 2527679654 BMS_IstTemperatur_hoechste 255;
BA_ "GenSigSendType" SG_ 2527679654 BMS_IstTemperatur_niedrigste 0;
BA_ "GenSigStartValue" SG_ 2527679654 BMS_IstTemperatur_niedrigste 254;
BA_ "GenSigSwitchedByIgnition" SG_ 2527679654 BMS_IstTemperatur_niedrigste 0;
BA_ "Fehlerwert" SG_ 2527679654 BMS_IstTemperatur_niedrigste 255;
BA_ "GenSigSendType" SG_ 2527679654 BMS_IstZellspannung_hoechste 0;
BA_ "GenSigStartValue" SG_ 2527679654 BMS_IstZellspannung_hoechste 4094;
BA_ "GenSigSwitchedByIgnition" SG_ 2527679654 BMS_IstZellspannung_hoechste 0;
BA_ "Fehlerwert" SG_ 2527679654 BMS_IstZellspannung_hoechste 4095;
BA_ "GenSigSendType" SG_ 2527679654 BMS_IstZellspannung_niedrigste 0;
BA_ "GenSigStartValue" SG_ 2527679654 BMS_IstZellspannung_niedrigste 4094;
BA_ "GenSigSwitchedByIgnition" SG_ 2527679654 BMS_IstZellspannung_niedrigste 0;
BA_ "Fehlerwert" SG_ 2527679654 BMS_IstZellspannung_niedrigste 4095;
BA_ "GenSigSendType" SG_ 207 BMS_20_BZ 0;
BA_ "GenSigFuncType" SG_ 207 BMS_20_BZ 1;
BA_ "GenSigSwitchedByIgnition" SG_ 207 BMS_20_BZ 0;
BA_ "GenSigSendType" SG_ 207 BMS_20_CRC 0;
BA_ "GenSigFuncType" SG_ 207 BMS_20_CRC 2;
BA_ "GenSigSwitchedByIgnition" SG_ 207 BMS_20_CRC 0;
BA_ "GenSigSendType" SG_ 207 BMS_ErwGrenzen_aktiv 0;
BA_ "GenSigSwitchedByIgnition" SG_ 207 BMS_ErwGrenzen_aktiv 0;
BA_ "GenSigSendType" SG_ 207 BMS_Fehler_HVBattAbschaltung 0;
BA_ "GenSigSwitchedByIgnition" SG_ 207 BMS_Fehler_HVBattAbschaltung 0;
BA_ "GenSigSendType" SG_ 207 BMS_Fehler_HVBattAbschaltung_Anf 0;
BA_ "GenSigSwitchedByIgnition" SG_ 207 BMS_Fehler_HVBattAbschaltung_Anf 0;
BA_ "GenSigSendType" SG_ 207 BMS_Fehler_Leistungsred 0;
BA_ "GenSigSwitchedByIgnition" SG_ 207 BMS_Fehler_Leistungsred 0;
BA_ "GenSigSendType" SG_ 207 BMS_Fehler_Notabschaltung_Crash 0;
BA_ "GenSigSwitchedByIgnition" SG_ 207 BMS_Fehler_Notabschaltung_Crash 0;
BA_ "GenSigSendType" SG_ 207 BMS_Fehlerstatus_HV_Schuetze 0;
BA_ "GenSigSwitchedByIgnition" SG_ 207 BMS_Fehlerstatus_HV_Schuetze 0;
BA_ "GenSigSendType" SG_ 207 BMS_HVIL_Status 0;
BA_ "GenSigSwitchedByIgnition" SG_ 207 BMS_HVIL_Status 0;
BA_ "Fehlerwert" SG_ 207 BMS_HVIL_Status 3;
BA_ "GenSigSendType" SG_ 207 BMS_IstModus 0;
BA_ "GenSigStartValue" SG_ 207 BMS_IstModus 7;
BA_ "GenSigSwitchedByIgnition" SG_ 207 BMS_IstModus 0;
BA_ "GenSigSendType" SG_ 207 BMS_Spannung 0;
BA_ "GenSigStartValue" SG_ 207 BMS_Spannung 4094;
BA_ "GenSigSwitchedByIgnition" SG_ 207 BMS_Spannung 0;
BA_ "Fehlerwert" SG_ 207 BMS_Spannung 4095;
BA_ "GenSigSendType" SG_ 207 BMS_Spannung_Zwischenkreis 0;
BA_ "GenSigStartValue" SG_ 207 BMS_Spannung_Zwischenkreis 4094;
BA_ "GenSigSwitchedByIgnition" SG_ 207 BMS_Spannung_Zwischenkreis 0;
BA_ "Fehlerwert" SG_ 207 BMS_Spannung_Zwischenkreis 4095;
BA_ "GenSigSendType" SG_ 207 BMS_Strom 0;
BA_ "GenSigStartValue" SG_ 207 BMS_Strom 32766;
BA_ "GenSigSwitchedByIgnition" SG_ 207 BMS_Strom 0;
BA_ "Fehlerwert" SG_ 207 BMS_Strom 32767;
BA_ "GenSigSendType" SG_ 2463978704 BMS_Max_Entladeleistung 0;
BA_ "GenSigStartValue" SG_ 2463978704 BMS_Max_Entladeleistung 8190;
BA_ "GenSigSwitchedByIgnition" SG_ 2463978704 BMS_Max_Entladeleistung 0;
BA_ "GenSigSendType" SG_ 2463978704 BMS_Max_Entladestrom 0;
BA_ "GenSigStartValue" SG_ 2463978704 BMS_Max_Entladestrom 8190;
BA_ "GenSigSwitchedByIgnition" SG_ 2463978704 BMS_Max_Entladestrom 0;
BA_ "GenSigSendType" SG_ 2463978704 BMS_Max_Ladeleistung 0;
BA_ "GenSigStartValue" SG_ 2463978704 BMS_Max_Ladeleistung 8190;
BA_ "GenSigSwitchedByIgnition" SG_ 2463978704 BMS_Max_Ladeleistung 0;
BA_ "GenSigSendType" SG_ 2463978704 BMS_Max_Ladestrom 0;
BA_ "GenSigStartValue" SG_ 2463978704 BMS_Max_Ladestrom 8190;
BA_ "GenSigSwitchedByIgnition" SG_ 2463978704 BMS_Max_Ladestrom 0;
BA_ "GenSigSendType" SG_ 2463978705 BMS_Ladezustand 0;
BA_ "GenSigStartValue" SG_ 2463978705 BMS_Ladezustand 2046;
BA_ "GenSigSwitchedByIgnition" SG_ 2463978705 BMS_Ladezustand 0;
BA_ "Fehlerwert" SG_ 2463978705 BMS_Ladezustand 2047;
BA_ "GenSigSendType" SG_ 2463978705 BMS_Nutzbare_EntladeEnergie 0;
BA_ "GenSigStartValue" SG_ 2463978705 BMS_Nutzbare_EntladeEnergie 65534;
BA_ "GenSigSwitchedByIgnition" SG_ 2463978705 BMS_Nutzbare_EntladeEnergie 0;
BA_ "Fehlerwert" SG_ 2463978705 BMS_Nutzbare_EntladeEnergie 65535;
BA_ "GenSigSendType" SG_ 2463978705 BMS_PerfInd_Entladen 0;
BA_ "GenSigStartValue" SG_ 2463978705 BMS_PerfInd_Entladen 1022;
BA_ "GenSigSwitchedByIgnition" SG_ 2463978705 BMS_PerfInd_Entladen 0;
BA_ "GenSigSendType" SG_ 2463978705 BMS_PerfInd_Laden 0;
BA_ "GenSigStartValue" SG_ 2463978705 BMS_PerfInd_Laden 1022;
BA_ "GenSigSwitchedByIgnition" SG_ 2463978705 BMS_PerfInd_Laden 0;
BA_ "GenSigSendType" SG_ 2463978705 BMS_Status_EoHVL_Heizer 0;
BA_ "GenSigSwitchedByIgnition" SG_ 2463978705 BMS_Status_EoHVL_Heizer 0;
BA_ "Fehlerwert" SG_ 2463978705 BMS_Status_EoHVL_Heizer 3;
BA_ "GenSigSendType" SG_ 2589283664 BMS_Balancing_Aktiv 0;
BA_ "GenSigSwitchedByIgnition" SG_ 2589283664 BMS_Balancing_Aktiv 0;
BA_ "GenSigSendType" SG_ 2589283664 BMS_Ladevorgang_aktiv 0;
BA_ "GenSigSwitchedByIgnition" SG_ 2589283664 BMS_Ladevorgang_aktiv 0;
BA_ "GenSigSendType" SG_ 2589283664 BMS_Max_Energie 0;
BA_ "GenSigStartValue" SG_ 2589283664 BMS_Max_Energie 8190;
BA_ "GenSigSwitchedByIgnition" SG_ 2589283664 BMS_Max_Energie 0;
BA_ "GenSigSendType" SG_ 2589283664 BMS_Max_Ladezustand 0;
BA_ "GenSigStartValue" SG_ 2589283664 BMS_Max_Ladezustand 2046;
BA_ "GenSigSwitchedByIgnition" SG_ 2589283664 BMS_Max_Ladezustand 0;
BA_ "GenSigSendType" SG_ 2589283664 BMS_Min_Ladezustand 0;
BA_ "GenSigStartValue" SG_ 2589283664 BMS_Min_Ladezustand 2046;
BA_ "GenSigSwitchedByIgnition" SG_ 2589283664 BMS_Min_Ladezustand 0;
BA_ "GenSigSendType" SG_ 2589283664 BMS_RIso_Ext 0;
BA_ "GenSigStartValue" SG_ 2589283664 BMS_RIso_Ext 4094;
BA_ "GenSigSwitchedByIgnition" SG_ 2589283664 BMS_RIso_Ext 0;
BA_ "Fehlerwert" SG_ 2589283664 BMS_RIso_Ext 4095;
BA_ "GenSigSendType" SG_ 2589283665 BMS_BattHeizung_VerbautStatus 0;
BA_ "GenSigSwitchedByIgnition" SG_ 2589283665 BMS_BattHeizung_VerbautStatus 0;
BA_ "GenSigSendType" SG_ 2589283665 BMS_Fehler_NTKreis 0;
BA_ "GenSigSwitchedByIgnition" SG_ 2589283665 BMS_Fehler_NTKreis 0;
BA_ "Fehlerwert" SG_ 2589283665 BMS_Fehler_NTKreis 1;
BA_ "GenSigSendType" SG_ 2589283665 BMS_Pumpe1_Ansteuerung 0;
BA_ "GenSigStartValue" SG_ 2589283665 BMS_Pumpe1_Ansteuerung 14;
BA_ "GenSigSwitchedByIgnition" SG_ 2589283665 BMS_Pumpe1_Ansteuerung 0;
BA_ "Fehlerwert" SG_ 2589283665 BMS_Pumpe1_Ansteuerung 15;
BA_ "GenSigSendType" SG_ 2589283665 BMS_Pumpe2_Ansteuerung 0;
BA_ "GenSigStartValue" SG_ 2589283665 BMS_Pumpe2_Ansteuerung 14;
BA_ "GenSigSwitchedByIgnition" SG_ 2589283665 BMS_Pumpe2_Ansteuerung 0;
BA_ "Fehlerwert" SG_ 2589283665 BMS_Pumpe2_Ansteuerung 15;
BA_ "GenSigSendType" SG_ 2589283665 BMS_RuecklaufTemperatur 0;
BA_ "GenSigStartValue" SG_ 2589283665 BMS_RuecklaufTemperatur 254;
BA_ "GenSigSwitchedByIgnition" SG_ 2589283665 BMS_RuecklaufTemperatur 0;
BA_ "Fehlerwert" SG_ 2589283665 BMS_RuecklaufTemperatur 255;
BA_ "GenSigSendType" SG_ 2589283665 BMS_SollVorlauftemperatur 0;
BA_ "GenSigStartValue" SG_ 2589283665 BMS_SollVorlauftemperatur 254;
BA_ "GenSigSwitchedByIgnition" SG_ 2589283665 BMS_SollVorlauftemperatur 0;
BA_ "Fehlerwert" SG_ 2589283665 BMS_SollVorlauftemperatur 255;
BA_ "GenSigSendType" SG_ 2589283665 BMS_Status_Ventil1 0;
BA_ "GenSigStartValue" SG_ 2589283665 BMS_Status_Ventil1 6;
BA_ "GenSigSwitchedByIgnition" SG_ 2589283665 BMS_Status_Ventil1 0;
BA_ "Fehlerwert" SG_ 2589283665 BMS_Status_Ventil1 7;
BA_ "GenSigSendType" SG_ 2589283665 BMS_Status_Ventil2 0;
BA_ "GenSigStartValue" SG_ 2589283665 BMS_Status_Ventil2 6;
BA_ "GenSigSwitchedByIgnition" SG_ 2589283665 BMS_Status_Ventil2 0;
BA_ "Fehlerwert" SG_ 2589283665 BMS_Status_Ventil2 7;
BA_ "GenSigSendType" SG_ 2589283665 BMS_Temperatur 0;
BA_ "GenSigStartValue" SG_ 2589283665 BMS_Temperatur 254;
BA_ "GenSigSwitchedByIgnition" SG_ 2589283665 BMS_Temperatur 0;
BA_ "Fehlerwert" SG_ 2589283665 BMS_Temperatur 255;
BA_ "GenSigSendType" SG_ 2589283665 BMS_Temperierung_Anf 0;
BA_ "GenSigStartValue" SG_ 2589283665 BMS_Temperierung_Anf 3;
BA_ "GenSigSwitchedByIgnition" SG_ 2589283665 BMS_Temperierung_Anf 0;
BA_ "GenSigSendType" SG_ 2589283665 BMS_VorlaufTemperatur 0;
BA_ "GenSigStartValue" SG_ 2589283665 BMS_VorlaufTemperatur 254;
BA_ "GenSigSwitchedByIgnition" SG_ 2589283665 BMS_VorlaufTemperatur 0;
BA_ "Fehlerwert" SG_ 2589283665 BMS_VorlaufTemperatur 255;
BA_ "GenSigSendType" SG_ 2589283760 BMS_Dauer_Entladeleistung 0;
BA_ "GenSigStartValue" SG_ 2589283760 BMS_Dauer_Entladeleistung 4094;
BA_ "GenSigSwitchedByIgnition" SG_ 2589283760 BMS_Dauer_Entladeleistung 0;
BA_ "GenSigSendType" SG_ 2589283760 BMS_Dauer_Ladeleistung 0;
BA_ "GenSigStartValue" SG_ 2589283760 BMS_Dauer_Ladeleistung 4094;
BA_ "GenSigSwitchedByIgnition" SG_ 2589283760 BMS_Dauer_Ladeleistung 0;
BA_ "GenSigSendType" SG_ 2589283760 BMS_Max_Spannung 0;
BA_ "GenSigStartValue" SG_ 2589283760 BMS_Max_Spannung 1022;
BA_ "GenSigSwitchedByIgnition" SG_ 2589283760 BMS_Max_Spannung 0;
BA_ "GenSigSendType" SG_ 2589283760 BMS_Min_Spannung 0;
BA_ "GenSigStartValue" SG_ 2589283760 BMS_Min_Spannung 1022;
BA_ "GenSigSwitchedByIgnition" SG_ 2589283760 BMS_Min_Spannung 0;
BA_ "GenSigSendType" SG_ 2463978646 CHA_Current_Mode 3;
BA_ "GenSigSwitchedByIgnition" SG_ 2463978646 CHA_Current_Mode 0;
BA_ "GenSigSendType" SG_ 2463978646 CHA_Current_Mode_BMA 3;
BA_ "GenSigSwitchedByIgnition" SG_ 2463978646 CHA_Current_Mode_BMA 0;
BA_ "GenSigSendType" SG_ 2463978646 CHA_Fahrer_Umschaltung 3;
BA_ "GenSigSwitchedByIgnition" SG_ 2463978646 CHA_Fahrer_Umschaltung 0;
BA_ "GenSigSendType" SG_ 2463978646 CHA_Fahrer_Umschaltung_BMA 3;
BA_ "GenSigSwitchedByIgnition" SG_ 2463978646 CHA_Fahrer_Umschaltung_BMA 0;
BA_ "GenSigSendType" SG_ 2463978646 CHA_Ziel_FahrPr_ACC 3;
BA_ "GenSigSwitchedByIgnition" SG_ 2463978646 CHA_Ziel_FahrPr_ACC 0;
BA_ "GenSigSendType" SG_ 2463978646 CHA_Ziel_FahrPr_AEB 3;
BA_ "GenSigSwitchedByIgnition" SG_ 2463978646 CHA_Ziel_FahrPr_AEB 0;
BA_ "GenSigSendType" SG_ 2463978646 CHA_Ziel_FahrPr_AFR 3;
BA_ "GenSigSwitchedByIgnition" SG_ 2463978646 CHA_Ziel_FahrPr_AFR 0;
BA_ "GenSigSendType" SG_ 2463978646 CHA_Ziel_FahrPr_AFS 3;
BA_ "GenSigSwitchedByIgnition" SG_ 2463978646 CHA_Ziel_FahrPr_AFS 0;
BA_ "GenSigSendType" SG_ 2463978646 CHA_Ziel_FahrPr_AGA 3;
BA_ "GenSigSwitchedByIgnition" SG_ 2463978646 CHA_Ziel_FahrPr_AGA 0;
BA_ "GenSigSendType" SG_ 2463978646 CHA_Ziel_FahrPr_AGK 3;
BA_ "GenSigSwitchedByIgnition" SG_ 2463978646 CHA_Ziel_FahrPr_AGK 0;
BA_ "GenSigSendType" SG_ 2463978646 CHA_Ziel_FahrPr_ALR 3;
BA_ "GenSigSwitchedByIgnition" SG_ 2463978646 CHA_Ziel_FahrPr_ALR 0;
BA_ "GenSigSendType" SG_ 2463978646 CHA_Ziel_FahrPr_AV 3;
BA_ "GenSigSwitchedByIgnition" SG_ 2463978646 CHA_Ziel_FahrPr_AV 0;
BA_ "GenSigSendType" SG_ 2463978646 CHA_Ziel_FahrPr_BMS 3;
BA_ "GenSigSwitchedByIgnition" SG_ 2463978646 CHA_Ziel_FahrPr_BMS 0;
BA_ "GenSigSendType" SG_ 2463978646 CHA_Ziel_FahrPr_DR 3;
BA_ "GenSigSwitchedByIgnition" SG_ 2463978646 CHA_Ziel_FahrPr_DR 0;
BA_ "GenSigSendType" SG_ 2463978646 CHA_Ziel_FahrPr_EAR 3;
BA_ "GenSigSwitchedByIgnition" SG_ 2463978646 CHA_Ziel_FahrPr_EAR 0;
BA_ "GenSigSendType" SG_ 2463978646 CHA_Ziel_FahrPr_EBKV 3;
BA_ "GenSigSwitchedByIgnition" SG_ 2463978646 CHA_Ziel_FahrPr_EBKV 0;
BA_ "GenSigSendType" SG_ 2463978646 CHA_Ziel_FahrPr_EDS 3;
BA_ "GenSigSwitchedByIgnition" SG_ 2463978646 CHA_Ziel_FahrPr_EDS 0;
BA_ "GenSigSendType" SG_ 2463978646 CHA_Ziel_FahrPr_EPS 3;
BA_ "GenSigSwitchedByIgnition" SG_ 2463978646 CHA_Ziel_FahrPr_EPS 0;
BA_ "GenSigSendType" SG_ 2463978646 CHA_Ziel_FahrPr_ESP 3;
BA_ "GenSigSwitchedByIgnition" SG_ 2463978646 CHA_Ziel_FahrPr_ESP 0;
BA_ "GenSigSendType" SG_ 2463978646 CHA_Ziel_FahrPr_FCWO 3;
BA_ "GenSigSwitchedByIgnition" SG_ 2463978646 CHA_Ziel_FahrPr_FCWO 0;
BA_ "GenSigSendType" SG_ 2463978646 CHA_Ziel_FahrPr_FCWP 3;
BA_ "GenSigSwitchedByIgnition" SG_ 2463978646 CHA_Ziel_FahrPr_FCWP 0;
BA_ "GenSigSendType" SG_ 2463978646 CHA_Ziel_FahrPr_Freilauf 3;
BA_ "GenSigSwitchedByIgnition" SG_ 2463978646 CHA_Ziel_FahrPr_Freilauf 0;
BA_ "GenSigSendType" SG_ 2463978646 CHA_Ziel_FahrPr_GE 3;
BA_ "GenSigSwitchedByIgnition" SG_ 2463978646 CHA_Ziel_FahrPr_GE 0;
BA_ "GenSigSendType" SG_ 2463978646 CHA_Ziel_FahrPr_HAL 3;
BA_ "GenSigSwitchedByIgnition" SG_ 2463978646 CHA_Ziel_FahrPr_HAL 0;
BA_ "GenSigSendType" SG_ 2463978646 CHA_Ziel_FahrPr_HDC 3;
BA_ "GenSigSwitchedByIgnition" SG_ 2463978646 CHA_Ziel_FahrPr_HDC 0;
BA_ "GenSigSendType" SG_ 2463978646 CHA_Ziel_FahrPr_HHC 3;
BA_ "GenSigSwitchedByIgnition" SG_ 2463978646 CHA_Ziel_FahrPr_HHC 0;
BA_ "GenSigSendType" SG_ 2463978646 CHA_Ziel_FahrPr_IL 3;
BA_ "GenSigSwitchedByIgnition" SG_ 2463978646 CHA_Ziel_FahrPr_IL 0;
BA_ "GenSigSendType" SG_ 2463978646 CHA_Ziel_FahrPr_mFDR 3;
BA_ "GenSigSwitchedByIgnition" SG_ 2463978646 CHA_Ziel_FahrPr_mFDR 0;
BA_ "GenSigSendType" SG_ 2463978646 CHA_Ziel_FahrPr_MO 3;
BA_ "GenSigSwitchedByIgnition" SG_ 2463978646 CHA_Ziel_FahrPr_MO 0;
BA_ "GenSigSendType" SG_ 2463978646 CHA_Ziel_FahrPr_MO_BZS 3;
BA_ "GenSigSwitchedByIgnition" SG_ 2463978646 CHA_Ziel_FahrPr_MO_BZS 0;
BA_ "GenSigSendType" SG_ 2463978646 CHA_Ziel_FahrPr_MO_Freilauf 3;
BA_ "GenSigSwitchedByIgnition" SG_ 2463978646 CHA_Ziel_FahrPr_MO_Freilauf 0;
BA_ "GenSigSendType" SG_ 2463978646 CHA_Ziel_FahrPr_MO_StSt 3;
BA_ "GenSigSwitchedByIgnition" SG_ 2463978646 CHA_Ziel_FahrPr_MO_StSt 0;
BA_ "GenSigSendType" SG_ 2463978646 CHA_Ziel_FahrPr_MXB 3;
BA_ "GenSigSwitchedByIgnition" SG_ 2463978646 CHA_Ziel_FahrPr_MXB 0;
BA_ "GenSigSendType" SG_ 2463978646 CHA_Ziel_FahrPr_NR 3;
BA_ "GenSigSwitchedByIgnition" SG_ 2463978646 CHA_Ziel_FahrPr_NR 0;
BA_ "GenSigSendType" SG_ 2463978646 CHA_Ziel_FahrPr_PACC 3;
BA_ "GenSigSwitchedByIgnition" SG_ 2463978646 CHA_Ziel_FahrPr_PACC 0;
BA_ "GenSigSendType" SG_ 2463978646 CHA_Ziel_FahrPr_PDC 3;
BA_ "GenSigSwitchedByIgnition" SG_ 2463978646 CHA_Ziel_FahrPr_PDC 0;
BA_ "GenSigSendType" SG_ 2463978646 CHA_Ziel_FahrPr_PreCrash 3;
BA_ "GenSigSwitchedByIgnition" SG_ 2463978646 CHA_Ziel_FahrPr_PreCrash 0;
BA_ "GenSigSendType" SG_ 2463978646 CHA_Ziel_FahrPr_QS 3;
BA_ "GenSigSwitchedByIgnition" SG_ 2463978646 CHA_Ziel_FahrPr_QS 0;
BA_ "GenSigSendType" SG_ 2463978646 CHA_Ziel_FahrPr_Reku_ZwGas 3;
BA_ "GenSigSwitchedByIgnition" SG_ 2463978646 CHA_Ziel_FahrPr_Reku_ZwGas 0;
BA_ "GenSigSendType" SG_ 2463978646 CHA_Ziel_FahrPr_SAK 3;
BA_ "GenSigSwitchedByIgnition" SG_ 2463978646 CHA_Ziel_FahrPr_SAK 0;
BA_ "GenSigSendType" SG_ 2463978646 CHA_Ziel_FahrPr_SCU 3;
BA_ "GenSigSwitchedByIgnition" SG_ 2463978646 CHA_Ziel_FahrPr_SCU 0;
BA_ "GenSigSendType" SG_ 2463978646 CHA_Ziel_FahrPr_ToS_laengs 3;
BA_ "GenSigSwitchedByIgnition" SG_ 2463978646 CHA_Ziel_FahrPr_ToS_laengs 0;
BA_ "GenSigSendType" SG_ 2463978646 CHA_Ziel_FahrPr_ToS_quer 3;
BA_ "GenSigSwitchedByIgnition" SG_ 2463978646 CHA_Ziel_FahrPr_ToS_quer 0;
BA_ "GenSigSendType" SG_ 2463978646 CHA_Ziel_FahrPr_VAQ 3;
BA_ "GenSigSwitchedByIgnition" SG_ 2463978646 CHA_Ziel_FahrPr_VAQ 0;
BA_REL_ "GenSigTimeoutTime" BU_SG_REL_ Airbag SG_ 2527679682 ACC_ASM_Ereignis 5000;
BA_REL_ "GenSigTimeoutTime" BU_SG_REL_ Airbag SG_ 2527679682 ACC_ASM_Zeitstempel 5000;
BA_REL_ "GenSigTimeoutTime" BU_SG_REL_ Airbag SG_ 2527679682 ACC_ASM_Data_1 5000;
BA_REL_ "GenSigTimeoutTime" BU_SG_REL_ Airbag SG_ 2527679682 ACC_ASM_Data_2 5000;
BA_REL_ "GenSigTimeoutTime" BU_SG_REL_ Airbag SG_ 2527679682 ACC_ASM_Data_3 5000;
BA_REL_ "GenSigTimeoutTime" BU_SG_REL_ Airbag SG_ 2527679682 ACC_ASM_Data_4 5000;
BA_REL_ "GenSigTimeoutTime" BU_SG_REL_ Airbag SG_ 2527679682 ACC_ASM_Data_5 5000;
BA_REL_ "GenSigTimeoutTime" BU_SG_REL_ Airbag SG_ 2527679682 ACC_ASM_Data_6 5000;
BA_REL_ "GenSigTimeoutTime" BU_SG_REL_ Airbag SG_ 219 AWV_03_CRC 5000;
BA_REL_ "GenSigTimeoutTime" BU_SG_REL_ Airbag SG_ 219 AWV_03_BZ 5000;
BA_REL_ "GenSigTimeoutTime" BU_SG_REL_ Airbag SG_ 219 PCF_Freigabe 5000;
BA_REL_ "GenSigTimeoutTime" BU_SG_REL_ Airbag SG_ 219 SDF_PSF_Objektstatus 5000;
BA_REL_ "GenSigTimeoutTime" BU_SG_REL_ Airbag SG_ 219 SDF_PSF_CU_Status 5000;
BA_REL_ "GenSigTimeoutTime" BU_SG_REL_ Airbag SG_ 219 SDF_PSF_CW 5000;
BA_REL_ "GenSigTimeoutTime" BU_SG_REL_ Airbag SG_ 219 SDF_PSF_Fahrer_aktiv 5000;
BA_REL_ "GenSigTimeoutTime" BU_SG_REL_ Airbag SG_ 219 SDF_PSF_Guete 5000;
BA_REL_ "GenSigTimeoutTime" BU_SG_REL_ Airbag SG_ 219 SDF_PSF_Kollisionsueberdeckung 5000;
BA_REL_ "GenSigTimeoutTime" BU_SG_REL_ Airbag SG_ 219 SDF_PSF_v_rel 5000;
BA_REL_ "GenSigTimeoutTime" BU_SG_REL_ Airbag SG_ 219 AWV_Eingriff_Sendeart 5000;
BA_REL_ "GenSigTimeoutTime" BU_SG_REL_ Airbag SG_ 219 AWV_Verz_Freigabe 5000;
BA_REL_ "GenSigTimeoutTime" BU_SG_REL_ Airbag SG_ 219 AWV_Verz_Anf 5000;
BA_REL_ "GenSigTimeoutTime" BU_SG_REL_ Airbag SG_ 219 AWV_Anf_Prefill 5000;
BA_REL_ "GenSigTimeoutTime" BU_SG_REL_ Airbag SG_ 219 AWV_Time_to_collision 5000;
BA_REL_ "GenSigTimeoutTime" BU_SG_REL_ Airbag SG_ 219 AWV_Zielobjekttyp 5000;
BA_REL_ "GenSigTimeoutTime" BU_SG_REL_ Airbag SG_ 219 AWV_QFK_AnfStat 5000;
BA_REL_ "GenSigTimeoutTime" BU_SG_REL_ Airbag SG_ 2463978646 CHA_Ziel_FahrPr_PreCrash 5000;
BA_REL_ "GenSigTimeoutTime" BU_SG_REL_ ICAS1_Gateway SG_ 64 AB_Front_Crash 500;
BA_REL_ "GenSigTimeoutTime" BU_SG_REL_ ICAS1_Gateway SG_ 64 AB_Heck_Crash 500;
BA_REL_ "GenSigTimeoutTime" BU_SG_REL_ ICAS1_Gateway SG_ 64 AB_SF_Crash 500;
BA_REL_ "GenSigTimeoutTime" BU_SG_REL_ ICAS1_Gateway SG_ 64 AB_SB_Crash 500;
BA_REL_ "GenSigTimeoutTime" BU_SG_REL_ ICAS1_Gateway SG_ 64 AB_Rollover_Crash 500;
BA_REL_ "GenSigTimeoutTime" BU_SG_REL_ ICAS1_Gateway SG_ 64 AB_Crash_Int 500;
BA_REL_ "GenSigTimeoutTime" BU_SG_REL_ ICAS1_Gateway SG_ 64 AB_Deaktivierung_HV 500;
BA_REL_ "GenSigTimeoutTime" BU_SG_REL_ ICAS1_Gateway SG_ 64 AB_Belegung_VF 500;
BA_REL_ "GenSigTimeoutTime" BU_SG_REL_ ICAS1_Gateway SG_ 64 AB_Gurtschloss_FA_ext 500;
BA_REL_ "GenSigTimeoutTime" BU_SG_REL_ ICAS1_Gateway SG_ 64 AB_Belegung_VF_ext 500;
BA_REL_ "GenSigTimeoutTime" BU_SG_REL_ ICAS1_Gateway SG_ 1312 AB_Crashschwere 2000;
BA_REL_ "GenSigTimeoutTime" BU_SG_REL_ ICAS1_Gateway SG_ 1312 AB_Anforderung_USM 2000;
BA_REL_ "GenSigTimeoutTime" BU_SG_REL_ ICAS1_Gateway SG_ 1312 AB_Gurtschloss_FA 2000;
BA_REL_ "GenSigTimeoutTime" BU_SG_REL_ ICAS1_Gateway SG_ 1312 AB_Gurtschloss_BF 2000;
BA_REL_ "GenSigTimeoutTime" BU_SG_REL_ ICAS1_Gateway SG_ 1312 AB_Gurtschloss_Reihe2_FA 2000;
BA_REL_ "GenSigTimeoutTime" BU_SG_REL_ ICAS1_Gateway SG_ 1312 AB_Gurtschloss_Reihe2_MI 2000;
BA_REL_ "GenSigTimeoutTime" BU_SG_REL_ ICAS1_Gateway SG_ 1312 AB_Gurtschloss_Reihe2_BF 2000;
BA_REL_ "GenSigTimeoutTime" BU_SG_REL_ ICAS1_Gateway SG_ 1312 AB_Gurtschloss_Reihe3_FA 2000;
BA_REL_ "GenSigTimeoutTime" BU_SG_REL_ ICAS1_Gateway SG_ 1312 AB_Gurtschloss_Reihe3_MI 2000;
BA_REL_ "GenSigTimeoutTime" BU_SG_REL_ ICAS1_Gateway SG_ 1312 AB_Gurtschloss_Reihe3_BF 2000;
BA_REL_ "GenSigTimeoutTime" BU_SG_REL_ ICAS1_Gateway SG_ 2527679722 AB_Gurtschloss_Reihe4_FA 2000;
BA_REL_ "GenSigTimeoutTime" BU_SG_REL_ ICAS1_Gateway SG_ 2527679722 AB_Gurtschloss_Reihe4_BF 2000;
BA_REL_ "GenSigTimeoutTime" BU_SG_REL_ ICAS1_Gateway SG_ 2527679722 AB_Gurtschloss_Reihe4_MI 2000;
BA_REL_ "GenSigTimeoutTime" BU_SG_REL_ ICAS1_KommunikationsServer SG_ 64 AB_RGS_Anst 500;
BA_REL_ "GenSigTimeoutTime" BU_SG_REL_ ICAS1_KommunikationsServer SG_ 64 AB_Crash_Int 500;
BA_REL_ "GenSigTimeoutTime" BU_SG_REL_ ICAS1_KommunikationsServer SG_ 64 AB_Lampe 500;
BA_REL_ "GenSigTimeoutTime" BU_SG_REL_ ICAS1_KommunikationsServer SG_ 64 AB_Systemfehler 500;
BA_REL_ "GenSigTimeoutTime" BU_SG_REL_ ICAS1_KommunikationsServer SG_ 64 AB_Gurtwarn_VF 500;
BA_REL_ "GenSigTimeoutTime" BU_SG_REL_ ICAS1_KommunikationsServer SG_ 64 AB_Gurtwarn_VB 500;
BA_REL_ "GenSigTimeoutTime" BU_SG_REL_ ICAS1_KommunikationsServer SG_ 64 AB_Deaktivierung_HV 500;
BA_REL_ "GenSigTimeoutTime" BU_SG_REL_ ICAS1_KommunikationsServer SG_ 1312 AB_Anprall_Seite_Beifahrer 2000;
BA_REL_ "GenSigTimeoutTime" BU_SG_REL_ ICAS1_KommunikationsServer SG_ 1312 AB_Anprall_Rollover 2000;
BA_REL_ "GenSigTimeoutTime" BU_SG_REL_ ICAS1_KommunikationsServer SG_ 1312 AB_Anprall_FGS 2000;
BA_REL_ "GenSigTimeoutTime" BU_SG_REL_ ICAS1_KommunikationsServer SG_ 1312 AB_Anprall_Front_Beifahrer 2000;
BA_REL_ "GenSigTimeoutTime" BU_SG_REL_ ICAS1_KommunikationsServer SG_ 1312 AB_Anprall_Front_Fahrer 2000;
BA_REL_ "GenSigTimeoutTime" BU_SG_REL_ ICAS1_KommunikationsServer SG_ 1312 AB_Anprall_Heck_Beifahrer 2000;
BA_REL_ "GenSigTimeoutTime" BU_SG_REL_ ICAS1_KommunikationsServer SG_ 1312 AB_Anprall_Heck_Fahrer 2000;
BA_REL_ "GenSigTimeoutTime" BU_SG_REL_ ICAS1_KommunikationsServer SG_ 1312 AB_Anprall_Seite_Fahrer 2000;
BA_REL_ "GenSigTimeoutTime" BU_SG_REL_ ICAS1_KommunikationsServer SG_ 1312 AB_Crashschwere 2000;
BA_REL_ "GenSigTimeoutTime" BU_SG_REL_ ICAS1_KommunikationsServer SG_ 1312 AB_Gurtschloss_FA 2000;
BA_REL_ "GenSigTimeoutTime" BU_SG_REL_ ICAS1_KommunikationsServer SG_ 1312 AB_Gurtschloss_BF 2000;
BA_REL_ "GenSigTimeoutTime" BU_SG_REL_ ICAS1_KommunikationsServer SG_ 1312 AB_Gurtschloss_Reihe2_FA 2000;
BA_REL_ "GenSigTimeoutTime" BU_SG_REL_ ICAS1_KommunikationsServer SG_ 1312 AB_Gurtschloss_Reihe2_MI 2000;
BA_REL_ "GenSigTimeoutTime" BU_SG_REL_ ICAS1_KommunikationsServer SG_ 1312 AB_Gurtschloss_Reihe2_BF 2000;
BA_REL_ "GenSigTimeoutTime" BU_SG_REL_ ICAS1_KommunikationsServer SG_ 1312 AB_Gurtschloss_Reihe3_FA 2000;
BA_REL_ "GenSigTimeoutTime" BU_SG_REL_ ICAS1_KommunikationsServer SG_ 1312 AB_Gurtschloss_Reihe3_MI 2000;
BA_REL_ "GenSigTimeoutTime" BU_SG_REL_ ICAS1_KommunikationsServer SG_ 1312 AB_Gurtschloss_Reihe3_BF 2000;
BA_REL_ "GenSigTimeoutTime" BU_SG_REL_ ICAS1_KommunikationsServer SG_ 1349 AB_Gurtwarn_Reihe4_FA 2000;
BA_REL_ "GenSigTimeoutTime" BU_SG_REL_ ICAS1_KommunikationsServer SG_ 1349 AB_Gurtwarn_Reihe4_BF 2000;
BA_REL_ "GenSigTimeoutTime" BU_SG_REL_ ICAS1_KommunikationsServer SG_ 1349 AB_Gurtwarn_Reihe4_MI 2000;
BA_REL_ "GenSigTimeoutTime" BU_SG_REL_ ICAS1_KommunikationsServer SG_ 1349 AB_Gurtwarn_Reihe2_FA 2000;
BA_REL_ "GenSigTimeoutTime" BU_SG_REL_ ICAS1_KommunikationsServer SG_ 1349 AB_Gurtwarn_Reihe2_BF 2000;
BA_REL_ "GenSigTimeoutTime" BU_SG_REL_ ICAS1_KommunikationsServer SG_ 1349 AB_Gurtwarn_Reihe2_MI 2000;
BA_REL_ "GenSigTimeoutTime" BU_SG_REL_ ICAS1_KommunikationsServer SG_ 1349 AB_Gurtwarn_Reihe3_FA 2000;
BA_REL_ "GenSigTimeoutTime" BU_SG_REL_ ICAS1_KommunikationsServer SG_ 1349 AB_Gurtwarn_Reihe3_MI 2000;
BA_REL_ "GenSigTimeoutTime" BU_SG_REL_ ICAS1_KommunikationsServer SG_ 1349 AB_Gurtwarn_Reihe3_BF 2000;
BA_REL_ "GenSigTimeoutTime" BU_SG_REL_ ICAS1_KommunikationsServer SG_ 1349 AB_SBR_hinten_verbau 2000;
BA_REL_ "GenSigTimeoutTime" BU_SG_REL_ ICAS1_KommunikationsServer SG_ 2527679722 AB_Gurtschloss_Reihe4_FA 2000;
BA_REL_ "GenSigTimeoutTime" BU_SG_REL_ ICAS1_KommunikationsServer SG_ 2527679722 AB_Gurtschloss_Reihe4_BF 2000;
BA_REL_ "GenSigTimeoutTime" BU_SG_REL_ ICAS1_KommunikationsServer SG_ 2527679722 AB_Gurtschloss_Reihe4_MI 2000;
BA_REL_ "GenSigTimeoutTime" BU_SG_REL_ LE1 SG_ 64 Airbag_01_CRC 500;
BA_REL_ "GenSigTimeoutTime" BU_SG_REL_ LE1 SG_ 64 Airbag_01_BZ 500;
BA_REL_ "GenSigTimeoutTime" BU_SG_REL_ LE1 SG_ 64 AB_Deaktivierung_HV 500;
BA_REL_ "GenSigTimeoutTime" BU_SG_REL_ LE1 SG_ 207 BMS_IstModus 500;
BA_REL_ "GenSigTimeoutTime" BU_SG_REL_ LE2 SG_ 64 Airbag_01_CRC 500;
BA_REL_ "GenSigTimeoutTime" BU_SG_REL_ LE2 SG_ 64 Airbag_01_BZ 500;
BA_REL_ "GenSigTimeoutTime" BU_SG_REL_ LE2 SG_ 64 AB_Deaktivierung_HV 500;
BA_REL_ "GenSigTimeoutTime" BU_SG_REL_ LE2 SG_ 207 BMS_IstModus 500;
BA_REL_ "GenSigTimeoutTime" BU_SG_REL_ Motor_BEV SG_ 333 ACC_18_CRC 500;
BA_REL_ "GenSigTimeoutTime" BU_SG_REL_ Motor_BEV SG_ 333 ACC_18_BZ 500;
BA_REL_ "GenSigTimeoutTime" BU_SG_REL_ Motor_BEV SG_ 333 ACC_limitierte_Anfahrdyn 500;
BA_REL_ "GenSigTimeoutTime" BU_SG_REL_ Motor_BEV SG_ 333 ACC_DynErhoehung 500;
BA_REL_ "GenSigTimeoutTime" BU_SG_REL_ Motor_BEV SG_ 333 ACC_Freilaufstrategie_TSK 500;
BA_REL_ "GenSigTimeoutTime" BU_SG_REL_ Motor_BEV SG_ 333 ACC_zul_Regelabw_unten 500;
BA_REL_ "GenSigTimeoutTime" BU_SG_REL_ Motor_BEV SG_ 333 ACC_Sollbeschleunigung_02 500;
BA_REL_ "GenSigTimeoutTime" BU_SG_REL_ Motor_BEV SG_ 333 ACC_zul_Regelabw_oben 500;
BA_REL_ "GenSigTimeoutTime" BU_SG_REL_ Motor_BEV SG_ 333 ACC_neg_Sollbeschl_Grad_02 500;
BA_REL_ "GenSigTimeoutTime" BU_SG_REL_ Motor_BEV SG_ 333 ACC_pos_Sollbeschl_Grad_02 500;
BA_REL_ "GenSigTimeoutTime" BU_SG_REL_ Motor_BEV SG_ 333 ACC_Anfahren 500;
BA_REL_ "GenSigTimeoutTime" BU_SG_REL_ Motor_BEV SG_ 333 ACC_Anhalten 500;
BA_REL_ "GenSigTimeoutTime" BU_SG_REL_ Motor_BEV SG_ 333 ACC_Typ 500;
BA_REL_ "GenSigTimeoutTime" BU_SG_REL_ Motor_BEV SG_ 333 ACC_Status_ACC 500;
BA_REL_ "GenSigTimeoutTime" BU_SG_REL_ Motor_BEV SG_ 333 ACC_Minimale_Bremsung 500;
BA_REL_ "GenSigTimeoutTime" BU_SG_REL_ Motor_BEV SG_ 333 ACC_Folgebeschl 500;
BA_REL_ "GenSigTimeoutTime" BU_SG_REL_ Motor_BEV SG_ 333 ACC_Freilauf_Info 500;
BA_REL_ "GenSigTimeoutTime" BU_SG_REL_ Motor_BEV SG_ 333 ACC_FoD_Status 500;
BA_REL_ "GenSigTimeoutTime" BU_SG_REL_ Motor_BEV SG_ 64 Airbag_01_CRC 500;
BA_REL_ "GenSigTimeoutTime" BU_SG_REL_ Motor_BEV SG_ 64 Airbag_01_BZ 500;
BA_REL_ "GenSigTimeoutTime" BU_SG_REL_ Motor_BEV SG_ 64 AB_Crash_Int 500;
BA_REL_ "GenSigTimeoutTime" BU_SG_REL_ Motor_BEV SG_ 64 AB_Deaktivierung_HV 500;
BA_REL_ "GenSigTimeoutTime" BU_SG_REL_ Motor_BEV SG_ 1312 Airbag_02_CRC 2000;
BA_REL_ "GenSigTimeoutTime" BU_SG_REL_ Motor_BEV SG_ 1312 Airbag_02_BZ 2000;
BA_REL_ "GenSigTimeoutTime" BU_SG_REL_ Motor_BEV SG_ 1312 AB_Gurtschloss_FA 2000;
BA_REL_ "GenSigTimeoutTime" BU_SG_REL_ Motor_BEV SG_ 1633 AAG_Bremsl_durch_ECD 1000;
BA_REL_ "GenSigTimeoutTime" BU_SG_REL_ Motor_BEV SG_ 1633 AAG_Anhaenger_abgesteckt 1000;
BA_REL_ "GenSigTimeoutTime" BU_SG_REL_ Motor_BEV SG_ 1633 AAG_Anhaenger_erkannt 1000;
BA_REL_ "GenSigTimeoutTime" BU_SG_REL_ Motor_BEV SG_ 1633 AAG_Bremslicht_H_def 1000;
BA_REL_ "GenSigTimeoutTime" BU_SG_REL_ Motor_BEV SG_ 345 ARA_Status 1000;
BA_REL_ "GenSigTimeoutTime" BU_SG_REL_ Motor_BEV SG_ 2589283607 AWC_Status_EoHVL 2000;
BA_REL_ "GenSigTimeoutTime" BU_SG_REL_ Motor_BEV SG_ 2536717313 BAP_EfficAssist_ASG_02_Header 800;
BA_REL_ "GenSigTimeoutTime" BU_SG_REL_ Motor_BEV SG_ 2536717314 BAP_EfficAssist_ASG_03_Header 800;
BA_REL_ "GenSigTimeoutTime" BU_SG_REL_ Motor_BEV SG_ 2536709120 BAP_Hybrid_ASG_01_Header 800;
BA_REL_ "GenSigTimeoutTime" BU_SG_REL_ Motor_BEV SG_ 869 BEM_Batt_Ab 500;
BA_REL_ "GenSigTimeoutTime" BU_SG_REL_ Motor_BEV SG_ 1442 BMS_Status_Spgfreiheit 5000;
BA_REL_ "GenSigTimeoutTime" BU_SG_REL_ Motor_BEV SG_ 1442 BMS_OBD_Lampe_Anf 5000;
BA_REL_ "GenSigTimeoutTime" BU_SG_REL_ Motor_BEV SG_ 1442 BMS_Fehlerlampe_Anf 5000;
BA_REL_ "GenSigTimeoutTime" BU_SG_REL_ Motor_BEV SG_ 1442 BMS_Warnlampe_Anf 5000;
BA_REL_ "GenSigTimeoutTime" BU_SG_REL_ Motor_BEV SG_ 1442 BMS_Kl30c_Status 5000;
BA_REL_ "GenSigTimeoutTime" BU_SG_REL_ Motor_BEV SG_ 2527679654 BMS_11_CRC 2000;
BA_REL_ "GenSigTimeoutTime" BU_SG_REL_ Motor_BEV SG_ 2527679654 BMS_11_BZ 2000;
BA_REL_ "GenSigTimeoutTime" BU_SG_REL_ Motor_BEV SG_ 2527679654 BMS_IsoZustand 2000;
BA_REL_ "GenSigTimeoutTime" BU_SG_REL_ Motor_BEV SG_ 2527679654 BMS_IsoFehler 2000;
BA_REL_ "GenSigTimeoutTime" BU_SG_REL_ Motor_BEV SG_ 207 BMS_20_CRC 500;
BA_REL_ "GenSigTimeoutTime" BU_SG_REL_ Motor_BEV SG_ 207 BMS_20_BZ 500;
BA_REL_ "GenSigTimeoutTime" BU_SG_REL_ Motor_BEV SG_ 207 BMS_Fehlerstatus_HV_Schuetze 500;
BA_REL_ "GenSigTimeoutTime" BU_SG_REL_ Motor_BEV SG_ 207 BMS_ErwGrenzen_aktiv 500;
BA_REL_ "GenSigTimeoutTime" BU_SG_REL_ Motor_BEV SG_ 207 BMS_IstModus 500;
BA_REL_ "GenSigTimeoutTime" BU_SG_REL_ Motor_BEV SG_ 207 BMS_HVIL_Status 500;
BA_REL_ "GenSigTimeoutTime" BU_SG_REL_ Motor_BEV SG_ 207 BMS_Fehler_HVBattAbschaltung 500;
BA_REL_ "GenSigTimeoutTime" BU_SG_REL_ Motor_BEV SG_ 207 BMS_Fehler_HVBattAbschaltung_Anf 500;
BA_REL_ "GenSigTimeoutTime" BU_SG_REL_ Motor_BEV SG_ 207 BMS_Fehler_Leistungsred 500;
BA_REL_ "GenSigTimeoutTime" BU_SG_REL_ Motor_BEV SG_ 207 BMS_Strom 500;
BA_REL_ "GenSigTimeoutTime" BU_SG_REL_ Motor_BEV SG_ 207 BMS_Spannung_Zwischenkreis 500;
BA_REL_ "GenSigTimeoutTime" BU_SG_REL_ Motor_BEV SG_ 207 BMS_Spannung 500;
BA_REL_ "GenSigTimeoutTime" BU_SG_REL_ Motor_BEV SG_ 2463978704 BMS_Max_Entladestrom 1000;
BA_REL_ "GenSigTimeoutTime" BU_SG_REL_ Motor_BEV SG_ 2463978704 BMS_Max_Ladestrom 1000;
BA_REL_ "GenSigTimeoutTime" BU_SG_REL_ Motor_BEV SG_ 2463978704 BMS_Max_Entladeleistung 1000;
BA_REL_ "GenSigTimeoutTime" BU_SG_REL_ Motor_BEV SG_ 2463978704 BMS_Max_Ladeleistung 1000;
BA_REL_ "GenSigTimeoutTime" BU_SG_REL_ Motor_BEV SG_ 2463978705 BMS_Status_EoHVL_Heizer 1000;
BA_REL_ "GenSigTimeoutTime" BU_SG_REL_ Motor_BEV SG_ 2463978705 BMS_Ladezustand 1000;
BA_REL_ "GenSigTimeoutTime" BU_SG_REL_ Motor_BEV SG_ 2463978705 BMS_PerfInd_Entladen 1000;
BA_REL_ "GenSigTimeoutTime" BU_SG_REL_ Motor_BEV SG_ 2463978705 BMS_PerfInd_Laden 1000;
BA_REL_ "GenSigTimeoutTime" BU_SG_REL_ Motor_BEV SG_ 2463978705 BMS_Nutzbare_EntladeEnergie 1000;
BA_REL_ "GenSigTimeoutTime" BU_SG_REL_ Motor_BEV SG_ 2589283664 BMS_RIso_Ext 5000;
BA_REL_ "GenSigTimeoutTime" BU_SG_REL_ Motor_BEV SG_ 2589283664 BMS_Min_Ladezustand 5000;
BA_REL_ "GenSigTimeoutTime" BU_SG_REL_ Motor_BEV SG_ 2589283664 BMS_Max_Energie 5000;
BA_REL_ "GenSigTimeoutTime" BU_SG_REL_ Motor_BEV SG_ 2589283664 BMS_Max_Ladezustand 5000;
BA_REL_ "GenSigTimeoutTime" BU_SG_REL_ Motor_BEV SG_ 2589283665 BMS_BattHeizung_VerbautStatus 5000;
BA_REL_ "GenSigTimeoutTime" BU_SG_REL_ Motor_BEV SG_ 2589283665 BMS_Temperierung_Anf 5000;
BA_REL_ "GenSigTimeoutTime" BU_SG_REL_ Motor_BEV SG_ 2589283665 BMS_Status_Ventil1 5000;
BA_REL_ "GenSigTimeoutTime" BU_SG_REL_ Motor_BEV SG_ 2589283665 BMS_Status_Ventil2 5000;
BA_REL_ "GenSigTimeoutTime" BU_SG_REL_ Motor_BEV SG_ 2589283665 BMS_Pumpe1_Ansteuerung 5000;
BA_REL_ "GenSigTimeoutTime" BU_SG_REL_ Motor_BEV SG_ 2589283665 BMS_Pumpe2_Ansteuerung 5000;
BA_REL_ "GenSigTimeoutTime" BU_SG_REL_ Motor_BEV SG_ 2589283665 BMS_VorlaufTemperatur 5000;
BA_REL_ "GenSigTimeoutTime" BU_SG_REL_ Motor_BEV SG_ 2589283665 BMS_Temperatur 5000;
BA_REL_ "GenSigTimeoutTime" BU_SG_REL_ Motor_BEV SG_ 2589283665 BMS_SollVorlauftemperatur 5000;
BA_REL_ "GenSigTimeoutTime" BU_SG_REL_ Motor_BEV SG_ 2589283665 BMS_RuecklaufTemperatur 5000;
BA_REL_ "GenSigTimeoutTime" BU_SG_REL_ Motor_BEV SG_ 2589283760 BMS_Max_Spannung 5000;
BA_REL_ "GenSigTimeoutTime" BU_SG_REL_ Motor_BEV SG_ 2589283760 BMS_Min_Spannung 5000;
BA_REL_ "GenSigTimeoutTime" BU_SG_REL_ Motor_BEV SG_ 2589283760 BMS_Dauer_Entladeleistung 5000;
BA_REL_ "GenSigTimeoutTime" BU_SG_REL_ Motor_BEV SG_ 2589283760 BMS_Dauer_Ladeleistung 5000;
BA_REL_ "GenSigTimeoutTime" BU_SG_REL_ Motor_BEV SG_ 2463978646 CHA_Ziel_FahrPr_ESP 5000;
BA_REL_ "GenSigTimeoutTime" BU_SG_REL_ Motor_BEV SG_ 2463978646 CHA_Fahrer_Umschaltung 5000;
BA_REL_ "GenSigTimeoutTime" BU_SG_REL_ Motor_BEV SG_ 2463978646 CHA_Ziel_FahrPr_MO 5000;
BA_REL_ "GenSigTimeoutTime" BU_SG_REL_ Motor_BEV SG_ 2463978646 CHA_Ziel_FahrPr_ALR 5000;
VAL_ 333 ACC_limitierte_Anfahrdyn 0 "keine_Limitierung" 1 "Limitierung_Anfahrdynamik_angefordert" ;
VAL_ 333 ACC_nachtr_Stopp_Anf 0 "nicht_angefordert" 1 "angefordert" ;
VAL_ 333 ACC_DynErhoehung 0 "normale_Verzoegerungsdynamik" 1 "erhoehte_Verzoegerungsdynamik" ;
VAL_ 333 ACC_Freilaufstrategie_TSK 0 "Freilaufstr_nicht_angefordert" 1 "Freilaufstr_angefordert" ;
VAL_ 333 ACC_StartStopp_Info 0 "Motorlauf_langfristig_nicht_notwendig_Stoppfreigabe" 1 "Motoranlauf_nicht_zwingend_notwendig_Stoppverbot_keine_Startanforderung" 2 "Motoranlauf_zwingend_notwendig_Startanforderung" 3 "Systemfehler" ;
VAL_ 333 ACC_Sollbeschleunigung_02 2046 "Neutralwert" 2047 "Fehler" ;
VAL_ 333 ACC_Anfahren 0 "keine_Anforderung_Anfahren" 1 "Anforderung_Anfahren" ;
VAL_ 333 ACC_Anhalten 0 "kein_Anhalten_gewuenscht" 1 "Anhalten_gewuenscht" ;
VAL_ 333 ACC_Typ 0 "Basis_ACC" 1 "ACC_mit_FollowToStop" 2 "ACC_mit_StopAndGo" 3 "ACC_nicht_codiert" ;
VAL_ 333 ACC_Status_ACC 0 "ACC_OFF_Hauptschalter_aus" 1 "ACC_INIT" 2 "ACC_STANDBY" 3 "ACC_AKTIV_regelt" 4 "ACC_OVERRIDE" 5 "ACC_Abschaltreaktion" 6 "reversibler_Fehler_im_ACC_System" 7 "irreversibler_Fehler_im_ACC_System" ;
VAL_ 333 ACC_Minimale_Bremsung 0 "Anforderung_Minimale_Bremsung_nicht_aktiv" 1 "Anforderung_Minimale_Bremsung_aktiv" ;
VAL_ 333 ACC_Anhalteweg 2046 "Neutralwert" 2047 "Fehler" ;
VAL_ 333 ACC_Boost 0 "Boost_nicht_aktiv" 1 "Boost_aktiv" ;
VAL_ 333 ACC_Freilauf_Anf 0 "keine Freilauf-Anforderung" 1 "Freilauf-Anforderung" ;
VAL_ 333 ACC_Anforderung_HMS 0 "keine_Anforderung" 1 "halten" 2 "parken" 3 "halten_Standby" 4 "anfahren" 5 "Loesen_ueber_Rampe" ;
VAL_ 333 ACC_Folgebeschl 254 "Neutralwert" ;
VAL_ 333 ACC_Freilauf_Info 0 "Freilauf_freigegeben" 1 "kein_Uebergang_in_Freilauf_zulaessig" 2 "Freilauf_nicht_freigegeben" 3 "Freilauf_Anforderung" ;
VAL_ 333 ACC_Tempolimitassistent_Ein 0 "Tempolimitassistent_aus" 1 "Tempolimitassistent_ein" ;
VAL_ 333 ACC_FoD_Status 0 "Init" 1 "Funktion_inaktiv" 2 "Funktion_aktiv" ;
VAL_ 333 vESC_Verz_Anf 8 "Neutralwert" 9 "Init" 10 "Fehler" ;
VAL_ 333 RDR_v_ueber_Grund 4091 "Init" 4092 "temporaer_nicht_verfuegbar" 4093 "Fehler" ;
VAL_ 333 RDR_v_ueber_Grund_Genauigkeit 61 "groesser_6km_h" 62 "Init" 63 "Fehler" ;
VAL_ 333 RDR_v_ueber_Grund_Fahrtrichtung 0 "vorwaerts" 1 "rueckwaerts" 2 "init_unbekannt" ;
VAL_ 2527679682 ACC_ASM_Ereignis 0 "No_Event" 255 "ASM_Trigger" ;
VAL_ 2527679682 ACC_ASM_Zeitstempel 255 "Init" ;
VAL_ 64 AB_RGS_Anst 4 "aktiv_Niveau_1" 5 "aktiv_Niveau_2" 6 "aktiv_Niveau_3" 7 "aktiv_Niveau_4" 8 "deaktiviert" ;
VAL_ 64 AB_Front_Crash 0 "kein_Front_Crash" 1 "Front_Crash" ;
VAL_ 64 AB_Heck_Crash 0 "kein_Heck_Crash" 1 "Heck_Crash" ;
VAL_ 64 AB_SF_Crash 0 "kein_Seiten_Crash_Fahrer" 1 "Seiten_Crash_Fahrer" ;
VAL_ 64 AB_SB_Crash 0 "kein_Seiten_Crash_Beifahrer" 1 "Seiten_Crash_Beifahrer" ;
VAL_ 64 AB_Rollover_Crash 0 "kein_Rollover" 1 "Rollover" ;
VAL_ 64 AB_Crash_Int 0 "kein_Crash" 1 "Crash_Intensitaet_1" 2 "Crash_Intensitaet_2_(nur_Stellgliedtest_MLB_B8)" 3 "Crash_Intensitaet_2_(nur_D4_C7_Colorado_NF_PAG__Crash_im_MLB_B8)" 4 "Crash_Intensitaet_3_(alt_VW/AUDI__Stellgliedtest_MLB_B8)" 5 "Crash_Intensitaet_3_(alt_PAG)" 7 "Crash_Intensitaet_3" ;
VAL_ 64 AB_Lampe 0 "Aus" 1 "Ein" ;
VAL_ 64 AB_Deaktiviert 0 "aktiv" 1 "deaktiviert" ;
VAL_ 64 AB_VB_deaktiviert 0 "Beifahrerairbag_aktiv" 1 "Beifahrerairbag_deaktiviert" ;
VAL_ 64 AB_Systemfehler 0 "kein_Fehler" 1 "Airbag_Systemfehler" ;
VAL_ 64 AB_Diagnose 0 "nicht_in_Diagnose" 1 "in_Diagnose" ;
VAL_ 64 AB_Stellgliedtest 0 "nicht_im_Stellgliedtest" 1 "Airbag_im_Stellgliedtest" ;
VAL_ 64 AB_Erh_Auf_VB 0 "keine_Anzeige" 1 "Beifahrerairbag_deaktiviert" 2 "Beifahrerairbag_aktiviert" 3 "nicht_definiert" ;
VAL_ 64 AB_Gurtwarn_VF 0 "keine_Warnung" 1 "Gurtwarnung_ausloesen" ;
VAL_ 64 AB_Gurtwarn_VB 0 "keine_Warnung" 1 "Gurtwarnung_ausloesen" ;
VAL_ 64 AB_Anzeige_Fussg 0 "keine_FSG_Aktion_ausgeloest" 1 "Motorhaube_offen" 2 "Systemfehler" ;
VAL_ 64 AB_Texte_AKS 0 "keine_AKS_Ausloesung" 1 "AKS_ausgeloest" 2 "AKS_Systemfehler" ;
VAL_ 64 AB_PAO_Leuchte_Anf 0 "Leuchte_ausschalten" 1 "Leuchte_einschalten" ;
VAL_ 64 AB_MKB_gueltig 0 "Multikollisionsbremsung_nicht_freigeschaltet" 1 "Multikollisionsbremsung_freigeschaltet" ;
VAL_ 64 AB_MKB_Anforderung 0 "Multikollisionsbremsung_nicht_angefordert" 1 "Multikollisionsbremsung_angefordert" ;
VAL_ 64 AB_Versorgungsspannung 0 "plausibel" 1 "unplausibel" ;
VAL_ 64 AB_Deaktivierung_HV 0 "keine_Deaktivierung" 1 "Deaktivierung_1" 2 "Deaktivierung_2" 3 "Deaktivierung_3" 4 "Deaktivierung_4" 5 "Deaktivierung_5" 6 "Deaktivierung_6" 7 "Fehler" ;
VAL_ 64 AB_EDR_Trigger 0 "No_Event" 1 "Start_Event" 2 "NonDeployment_Event" 3 "Deployment_Event" ;
VAL_ 64 AB_Belegung_VF 0 "nicht_verfuegbar" 1 "Fehler" 2 "nicht_belegt" 3 "belegt" ;
VAL_ 64 AB_Gurtschloss_FA_ext 0 "nicht_verbaut" 1 "reserviert" 2 "nicht_gesteckt" 3 "gesteckt" 4 "dauerhaft_nicht_gesteckt" 5 "dauerhaft_gesteckt" 6 "Init" 7 "Fehler" ;
VAL_ 64 AB_Belegung_VF_ext 0 "nicht_verbaut" 1 "reserviert" 2 "nicht_belegt" 3 "belegt" 4 "dauerhaft_nicht_belegt" 5 "dauerhaft_belegt" 6 "Init" 7 "Fehler" ;
VAL_ 64 ASM_Masterzeit 255 "Init" ;
VAL_ 1312 LoGeWa_Event_Kombiwarnung 0 "Init" 1 "Unfall" 2 "Traktionsverlust" 3 "Panne" 4 "Sichtbehinderung" 5 "Aquaplaning" ;
VAL_ 1312 AB_Anforderung_eCall 0 "keine_Anforderung" 1 "Anforderung" ;
VAL_ 1312 AB_Anprall_Seite_Beifahrer 0 "kein_Anprall" 1 "Anprall_erkannt" ;
VAL_ 1312 AB_Anprall_Rollover 0 "kein_Anprall" 1 "Anprall_erkannt" ;
VAL_ 1312 AB_Anprall_FGS 0 "kein_Anprall" 1 "Anprall_erkannt" ;
VAL_ 1312 AB_Anprall_Front_Beifahrer 0 "kein_Anprall" 1 "Anprall_erkannt" ;
VAL_ 1312 AB_Anprall_Front_Fahrer 0 "kein_Anprall" 1 "Anprall_erkannt" ;
VAL_ 1312 AB_Anprall_Heck_Beifahrer 0 "kein_Anprall" 1 "Anprall_erkannt" ;
VAL_ 1312 AB_Anprall_Heck_Fahrer 0 "kein_Anprall" 1 "Anprall_erkannt" ;
VAL_ 1312 AB_Wickelklappung_Reihe2_MI 0 "nicht_verbaut" 1 "nicht_verfuegbar__Fehler_oder_Init" 2 "nicht_verriegelt" 3 "verriegelt" ;
VAL_ 1312 AB_Belegung_VB 0 "nicht_verfuegbar" 1 "Fehler" 2 "nicht_belegt" 3 "belegt" ;
VAL_ 1312 AB_Abschaltanf_SIH_BF 0 "Normalbetrieb" 1 "Abschaltung_angefordert" ;
VAL_ 1312 AB_Anprall_Seite_Fahrer 0 "kein_Anprall" 1 "Anprall_erkannt" ;
VAL_ 1312 SC_PAO_Schriftzug_Anf 0 "LED aus" 1 "LED an" 2 "LED blinken" 3 "reserviert" ;
VAL_ 1312 SC_PAO_ON_Anf 0 "LED aus" 1 "LED an" 2 "LED blinken" 3 "reserviert" ;
VAL_ 1312 SC_PAO_OFF_Anf 0 "LED aus" 1 "LED an" 2 "LED blinken" 3 "reserviert" ;
VAL_ 1312 AB_Crashschwere 0 "kein_Ereignis" 1 "Crashschwere_1" 2 "Crashschwere_2" 3 "Crashschwere_3" 4 "Crashschwere_4" 5 "Crashschwere_5" 6 "Crashschwere_2_bis_5" 7 "Fehler" ;
VAL_ 1312 AB_Anforderung_USM 0 "keine_Anforderung" 1 "Anforderung" ;
VAL_ 1312 AB_Gurtschloss_FA 0 "nicht_verbaut" 1 "nicht_verfügbar (Fehler oder Init)" 2 "nicht_gesteckt" 3 "gesteckt" ;
VAL_ 1312 AB_Gurtschloss_BF 0 "nicht_verbaut" 1 "nicht_verfügbar (Fehler oder Init)" 2 "nicht_gesteckt" 3 "gesteckt" ;
VAL_ 1312 AB_Gurtschloss_Reihe2_FA 0 "nicht_verbaut" 1 "nicht_verfügbar (Fehler oder Init)" 2 "nicht_gesteckt" 3 "gesteckt" ;
VAL_ 1312 AB_Gurtschloss_Reihe2_MI 0 "nicht_verbaut" 1 "nicht_verfügbar (Fehler oder Init)" 2 "nicht_gesteckt" 3 "gesteckt" ;
VAL_ 1312 AB_Gurtschloss_Reihe2_BF 0 "nicht_verbaut" 1 "nicht_verfügbar (Fehler oder Init)" 2 "nicht_gesteckt" 3 "gesteckt" ;
VAL_ 1312 AB_Gurtschloss_Reihe3_FA 0 "nicht_verbaut" 1 "nicht_verfügbar (Fehler oder Init)" 2 "nicht_gesteckt" 3 "gesteckt" ;
VAL_ 1312 AB_Gurtschloss_Reihe3_MI 0 "nicht_verbaut" 1 "nicht_verfügbar (Fehler oder Init)" 2 "nicht_gesteckt" 3 "gesteckt" ;
VAL_ 1312 AB_Gurtschloss_Reihe3_BF 0 "nicht_verbaut" 1 "nicht_verfügbar (Fehler oder Init)" 2 "nicht_gesteckt" 3 "gesteckt" ;
VAL_ 1312 AB_Sitzpos_Sens_FA 0 "nicht verfügbar" 1 "Fehler" 2 "Sitz nicht vorne" 3 "Sitz vorne" ;
VAL_ 1312 AB_Sitzpos_Sens_BF 0 "nicht verfügbar" 1 "Fehler" 2 "Sitz nicht vorne" 3 "Sitz vorne" ;
VAL_ 1312 AB_Wickelklappung_Reihe2_BF 0 "nicht_verbaut" 1 "nicht_verfuegbar__Fehler_oder_Init" 2 "nicht_verriegelt" 3 "verriegelt" ;
VAL_ 1312 AB_Wickelklappung_Reihe2_FA 0 "nicht_verbaut" 1 "nicht_verfuegbar__Fehler_oder_Init" 2 "nicht_verriegelt" 3 "verriegelt" ;
VAL_ 65 AB_MKB_Safing 0 "Multikollisionsbremsung_nicht_bestaetigt" 1 "Multikollisionsbremsung_bestaetigt" ;
VAL_ 1349 AB_Gurtwarn_Reihe4_FA 0 "nicht_verbaut" 1 "keine_Gurtwarnung_Sitz_leer" 2 "keine_Gurtwarnung_Sitz_belegt" 3 "Gurtwarnung_Sitz_belegt" ;
VAL_ 1349 AB_Gurtwarn_Reihe4_BF 0 "nicht_verbaut" 1 "keine_Gurtwarnung_Sitz_leer" 2 "keine_Gurtwarnung_Sitz_belegt" 3 "Gurtwarnung_Sitz_belegt" ;
VAL_ 1349 AB_Gurtwarn_Reihe4_MI 0 "nicht_verbaut" 1 "keine_Gurtwarnung_Sitz_leer" 2 "keine_Gurtwarnung_Sitz_belegt" 3 "Gurtwarnung_Sitz_belegt" ;
VAL_ 1349 AB_Gurtwarn_Reihe2_FA 0 "nicht_verbaut" 1 "keine_Gurtwarnung_Sitz_leer" 2 "keine_Gurtwarnung_Sitz_belegt" 3 "Gurtwarnung_Sitz_belegt" ;
VAL_ 1349 AB_Gurtwarn_Reihe2_BF 0 "nicht_verbaut" 1 "keine_Gurtwarnung_Sitz_leer" 2 "keine_Gurtwarnung_Sitz_belegt" 3 "Gurtwarnung_Sitz_belegt" ;
VAL_ 1349 AbstWarn_MV_FAS_Fkt_Status 0 "Init" 1 "Funktion_Ist_Ein" 2 "Funktion_Ist_Aus" 3 "Fehler" ;
VAL_ 1349 WarnBrems_Charisma_Status 0 "Init" 1 "verfügbar" 2 "nicht verfügbar" 3 "asynchron durch Fahrerwunsch" ;
VAL_ 1349 WarnBrems_Charisma_FahrPr 0 "keine_Funktion" 1 "Programm_1" 2 "Programm_2" 3 "Programm_3" 4 "Programm_4" 5 "Programm_5" 6 "Programm_6" 7 "Programm_7" 8 "Programm_8" 9 "Programm_9" 10 "Programm_10" 11 "Programm_11" 12 "Programm_12" 13 "Programm_13" 14 "Programm_14" 15 "Programm_15" ;
VAL_ 1349 AB_Gurtwarn_Reihe2_MI 0 "nicht_verbaut" 1 "keine_Gurtwarnung_Sitz_leer" 2 "keine_Gurtwarnung_Sitz_belegt" 3 "Gurtwarnung_Sitz_belegt" ;
VAL_ 1349 AB_Gurtwarn_Reihe3_FA 0 "nicht_verbaut" 1 "keine_Gurtwarnung_Sitz_leer" 2 "keine_Gurtwarnung_Sitz_belegt" 3 "Gurtwarnung_Sitz_belegt" ;
VAL_ 1349 AB_Gurtwarn_Reihe3_MI 0 "nicht_verbaut" 1 "keine_Gurtwarnung_Sitz_leer" 2 "keine_Gurtwarnung_Sitz_belegt" 3 "Gurtwarnung_Sitz_belegt" ;
VAL_ 1349 AB_Gurtwarn_Reihe3_BF 0 "nicht_verbaut" 1 "keine_Gurtwarnung_Sitz_leer" 2 "keine_Gurtwarnung_Sitz_belegt" 3 "Gurtwarnung_Sitz_belegt" ;
VAL_ 1349 LGI_FAS_Fkt_Status 0 "Init" 1 "Funktion_Ist_Ein" 2 "Funktion_Ist_Aus" 3 "Fehler" ;
VAL_ 1349 PreCrash_FAS_Fkt_Status 0 "Init" 1 "Funktion_Ist_Ein" 2 "Funktion_Ist_Aus" 3 "Fehler" ;
VAL_ 1349 AB_SBR_hinten_verbau 0 "ohne_SBR_hinten" 1 "mit_SBR_hinten" 2 "nicht_definiert" 3 "Init" ;
VAL_ 1349 AWV_Einstellung_System_ASG 0 "deaktiviert" 1 "aktiviert" ;
VAL_ 1349 AWV_Einstellung_Warnung_ASG 0 "Aus" 1 "Setting_2" 2 "Setting_3" 3 "Setting_4" 4 "Setting_5" 5 "Ein" ;
VAL_ 1349 SC_PreSense_Modus_Warnung_NV 0 "Aus" 1 "Setting_2" 2 "Setting_3" 3 "Setting_4" 4 "Setting_5" 5 "Ein" ;
VAL_ 1349 SC_PreSense_Modus_Warnung_MV 0 "Aus" 1 "Setting_2" 2 "Setting_3" 3 "Setting_4" 4 "Setting_5" 5 "Ein" ;
VAL_ 1349 SC_PreSense_Modus_System_MV 0 "deaktiviert" 1 "aktiviert" ;
VAL_ 1349 SC_PreSense_Modus_System_NV 0 "deaktiviert" 1 "aktiviert" ;
VAL_ 1349 SC_PreSense_Modus_System_KAS 0 "deaktiviert" 1 "aktiviert" ;
VAL_ 2527679722 AB_Gurtschloss_Reihe4_FA 0 "nicht_verbaut" 1 "nicht_verfügbar (Fehler oder Init)" 2 "nicht_gesteckt" 3 "gesteckt" ;
VAL_ 2527679722 AB_Gurtschloss_Reihe4_BF 0 "nicht_verbaut" 1 "nicht_verfügbar (Fehler oder Init)" 2 "nicht_gesteckt" 3 "gesteckt" ;
VAL_ 2527679722 AB_Gurtschloss_Reihe4_MI 0 "nicht_verbaut" 1 "nicht_verfügbar (Fehler oder Init)" 2 "nicht_gesteckt" 3 "gesteckt" ;
VAL_ 1633 AAG_AVS_Fehler_02_inv 0 "Fehler" 1 "kein_Fehler" ;
VAL_ 1633 AAG_Bremsl_durch_ECD 0 "Bremslicht_ist_aus" 1 "Bremslicht_durch_ECD_aktiv" ;
VAL_ 1633 AAG_Anhaenger_abgesteckt 1 "Anhaenger_wurde_bei_KL15_aus_abgesteckt" ;
VAL_ 1633 AAG_NSL_aktiv 1 "Anhaenger_Nebelschusslicht_aktiv" ;
VAL_ 1633 AAG_Anhaenger_erkannt 0 "kein_Anhaenger_erkannt" 1 "AAG_Anhaenger_erkannt" ;
VAL_ 1633 AAG_Blinker_H_aktiv 1 "Anhaenger_Blinker_aktiv" ;
VAL_ 1633 AAG_Blinker_HL_def 1 "Anhaenger_Blinker_links_defekt" ;
VAL_ 1633 AAG_Blinker_HR_def 1 "Anhaenger_Blinker_rechts_defekt" ;
VAL_ 1633 AAG_Bremslicht_H_def 1 "Anhaenger_Bremslicht_defekt" ;
VAL_ 1633 AAG_Schlusslicht_HL_def 1 "Anhaenger_Schlusslicht_links_defekt" ;
VAL_ 1633 AAG_Schlusslicht_HR_def 1 "Anhaenger_Schlusslicht_rechts_defekt" ;
VAL_ 1633 AAG_Bremslicht_Reku 0 "inaktiv" 1 "aktiv" ;
VAL_ 1633 AAG_AVS_Fehler_02 0 "kein_Fehler" 1 "Fehler" ;
VAL_ 1633 AAG_LED_aktiv 0 "Lampen" 1 "LED" ;
VAL_ 1633 AAG_AVS_Stati 0 "endlage eingefahren erreicht" 1 "endlage ausgefahren erreicht" 2 "ausfahren automatik " 3 "einfahren automatik" 4 "ausfahren manuell " 5 "einfahren manuell" 6 "zwischenposition" 7 "nicht initialisiert" ;
VAL_ 345 ARA_Anf_Meldungen 0 "keine_Meldung" 1 "trailer_assist_temp_notAvailable" 2 "pressBrake_toReleaseParkingBrak" 3 "trailDetNotFinishedMoveStraight" 4 "trailDetecNotFinishedReducedFctn" 5 "parkAsNotFuncRackOnTrailTowHitch" 6 "aborted_trailNotDetec_emergBrake" 7 "aborted_trailer_is_not_detected" 8 "standstill_to_act_trailerAssist" 9 "duringAutomSteering_actNotAvail" 10 "standstill_time_not_long_enough" 11 "press_PLA_BTN_toActTrailerAssist" 12 "Temporary_not_available_ESP_off" 13 "traject_forward_path_suggestion" 14 "traject_backing_up_is_possible" 15 "traject_towing_fwd_canB_finished" 16 "trailerAsNotAvail_acivateMirrors" 17 "mirrors_are_closing" 18 "trailerAsNotAvailable_close_door" 19 "trailerAs_aborted_driverDoorOpen" 20 "trailerAsNotAvailable_closeTrunk" 21 "aborted_trunk_door_is_open" 22 "trailerAsNotAvail_cleanRearCam" 23 "aborted_clean_rear_camera" 24 "trailerAs_check_trailerConnector" 25 "trajectory_finished" 128 "steeringAsAct_brakeByYourself" 129 "trailer_assist_is_finished" 130 "SteerIntervenDriverEmergBrakeAct" 131 "stabilityCtrl_emergencyBrake_act" 132 "maxAngleExeeded_EmergBrakeAct" 133 "sysErrorEmergBrakeContactService" 134 "system_error_contact_service" 135 "aborted_trailNotDetec_emergBrake" 136 "aborted_trailerNotDetecRsmeSteer" 137 "system_error_braking_byYourself" 138 "trajectFwdSteerAsActBrakeYourslf" 139 "SteeringAs_notAct_resumeSteering" 140 "trailerAs_aborted_resumeSteering" ;
VAL_ 345 ARA_Knickwinkel_konfidenz 126 "Init" 127 "Fehler" ;
VAL_ 345 ARA_Texte 0 "kein Text/Akustik" 63 "Fehler" ;
VAL_ 345 ARA_Modus 0 "Knickwinkelmodus" 1 "Trajektorienmodus" ;
VAL_ 345 ARA_Aktiver_Grafikmodus 0 "keine_Grafik" 1 "Grafikmodus_aktiv" ;
VAL_ 345 ARA_Deaktivierung_sperren 0 "nicht_gesperrt" 1 "gesperrt" ;
VAL_ 345 ARA_Modus_Anf 0 "ARA Modus nicht im TSG angefordert" 1 "ARA Modus im TSG angefordert" ;
VAL_ 345 ARA_Bremsfuss 0 "kein Bremsfuss" 1 "Bremsfuss angefordert" ;
VAL_ 345 ARA_Sensor_Aktivierung 0 "Knickwinkelsensor deaktivieren" 1 "Knickwinkelsensor aktivieren" ;
VAL_ 345 ARA_Knickwinkel_Komfort 62 "Init" 63 "Fehler" ;
VAL_ 345 ARA_Status 0 "ARA_Status_inaktiv" 1 "ARA_Status_init" 2 "Fehler" 3 "ARA_Status_Start" 4 "ARA_Status_aktiv" 6 "ARA_Status_Regelung_aktiv" 8 "ARA_Status_betriebsbereit" 9 "ARA_Status_Klemmtraeger_erkannt" 10 "ARA_Status_Abbruch" 11 "ARA_Status_nicht_betriebsbereit" ;
VAL_ 345 ARA_Knickwinkel_Max 126 "Init" 127 "Fehler" ;
VAL_ 345 ARA_Knickwinkel_Soll 254 "Init" 255 "Fehler" ;
VAL_ 345 ARA_Knickwinkel_Ist 254 "Init" 255 "Fehler" ;
VAL_ 2589283607 AWC_Status_EoHVL 0 "Init" 1 "Keine_offene_HV_Leitung_erkannt" 2 "offene_HV_Leitung_erkannt" 3 "Fehler" ;
VAL_ 2589283607 AWC_Status_Spgfreiheit 0 "Init" 1 "HV_Komponente_spannungsfrei" 2 "HV_Komp_nicht_spannungsfrei" 3 "Fehler_nicht_spannungsfrei" ;
VAL_ 2589283607 AWC_IstSpannung 1022 "Init" 1023 "Fehler" ;
VAL_ 2589283607 AWC_Fehlerstatus 0 "Komponente_IO" 1 "Eingeschr_KompFkt_AWC_Lad_NIO" 2 "Eingeschr_KompFkt_reserve" 3 "Eingeschr_KompFkt_Interlock" 4 "Eingeschr_KompFkt_reserve" 5 "Eingeschr_KompFkt_reserve" 6 "Keine_Komponentenfunktion" 7 "Init" ;
VAL_ 2589283607 AWC_IstModus 0 "Standby_AWCLaden_inaktiv" 1 "AWCLaden_aktiv" 2 "AWCLaden_Verzoegerung" 3 "AWCLaden_Deaktiviert" 6 "Init" 7 "Ladefehler" ;
VAL_ 2589283607 AWC_IstStrom 510 "Init" 511 "Fehler" ;
VAL_ 2589283607 AWC_MaxLadLeistung 510 "Init" 511 "Fehler" ;
VAL_ 219 PCF_Freigabe 0 "keine_Freigabe_PreCrashFront" 1 "Freigabe_PreCrashFront" ;
VAL_ 219 SDF_PSF_Objektstatus 0 "kein_relevantes_Obj" 1 "relevantes_Obj_vorausfahrend" 2 "relevantes_Obj_stehend" 3 "relevantes_Obj_angehalten" 4 "relevantes_Obj_entgegenkommend" 5 "relevantes_Obj_querend" 7 "Fehler" ;
VAL_ 219 SDF_PSF_CU_Status 0 "Kollision_vermeidbar" 1 "Kollision_unvermeidbar" ;
VAL_ 219 SDF_PSF_CW 126 "Init" 127 "Fehler" ;
VAL_ 219 SDF_PSF_Fahrer_aktiv 0 "Fahrer_nicht_aktiv" 1 "Fahrer_aktiv" ;
VAL_ 219 SDF_PSF_Guete 0 "Modellguete_niO_keine_Plausi" 1 "Modellguete_niO_plausibilisiert" 2 "Modellguete_iO_keine_Plausi" 3 "Modellguete_iO_plausibilisiert" ;
VAL_ 219 SDF_PSF_Kollisionsueberdeckung 0 "Keine_Ueberdeckung" 29 "Ueberdeckung_groesser_Maximalwert" 30 "Init" 31 "Fehler" ;
VAL_ 219 SDF_PSF_Time_To_Collision 254 "Init" 255 "Fehler" ;
VAL_ 219 SDF_PSF_v_rel 0 "Objektstatus_0" 254 "Init" 255 "Fehler" ;
VAL_ 219 AWV_Eingriff_Sendeart 0 "langsamer_Zyklus" 1 "schneller_Zyklus" ;
VAL_ 219 AWV_Verz_Freigabe 0 "Verzoegerung_nicht_freigeben" 1 "Verzoegerung_freigeben" ;
VAL_ 219 AWV_Verz_Anf 1023 "keine_Anforderung" ;
VAL_ 219 AWV_Anf_Prefill 0 "Keine_Anforderung" 1 "Prefill_aktivieren" ;
VAL_ 219 AWV_Ruckprofil 0 "kein_Ruck" 1 "schwacher_Ruck" 2 "mittlerer_Ruck" 3 "starker_Ruck" ;
VAL_ 219 AWV_Time_to_collision 253 "Wert_groesser_max" 254 "Unbekannt" 255 "Init" ;
VAL_ 219 AWV_HBA_Param 0 "Defaultparametersatz" 1 "leicht_erhoeht" 2 "erhoeht" 3 "hoechst" ;
VAL_ 219 AWV_Verz_Anf_ASIL 0 "QM" 1 "A" 2 "B" 3 "C" ;
VAL_ 219 AWV_Time_to_brake 125 "Wert_groesser_max" 126 "unbekannt" 127 "Init" ;
VAL_ 219 AWV_Zielobjekttyp 0 "Unbekannt" 1 "Fussgaenger" 2 "Zweirad" 3 "PKW" 4 "LKW" 5 "reserviert" 6 "reserviert" 7 "reserviert" 8 "reserviert" 9 "reserviert" 10 "reserviert" 11 "reserviert" 12 "reserviert" 13 "reserviert" 14 "reserviert" 15 "init" ;
VAL_ 219 AWV_QFK_KruemmSoll_VZ 0 "positiv" 1 "negativ" ;
VAL_ 219 AWV_QFK_AnfStat 1 "Init" 2 "Bereit" 4 "Eingriff" ;
VAL_ 869 BEM_UBDM 0 "Init" 255 "Fehler" ;
VAL_ 869 NVEM_Ladefreigabe 0 "kein_Freigabe" 1 "Freigabe_Stufe_1" 2 "Freigabe_Stufe_2" 3 "Uneingeschraenkte_Freigabe" ;
VAL_ 869 NVEM_FMAus_Info 0 "Motorlauf_langfristig_nicht_notwendig_FMAus_Freigabe" 1 "Motoranlauf_nicht_zwingend_notwendig_Stoppverbot_keine_Startanforderung" 2 "Motoranlauf_zwingend_notwendig_Startanforderung" 3 "Systemfehler" ;
VAL_ 869 NVEM_PTC_Sollstufe 0 "Aus" 1 "Stufe_1" 2 "Stufe_2" 3 "Stufe_3" ;
VAL_ 869 NVEM_P_Generator_Status 0 "gefiltert" 1 "ungefiltert" ;
VAL_ 869 BEM_P_Generator 255 "Fehler" ;
VAL_ 869 BEM_n_LLA 0 "keine_Erhoehung" 1 "Stufe_1" 2 "Stufe_2" 3 "Stufe_3" ;
VAL_ 869 BEM_01_Abschaltstufen 0 "Stufe_0_keine_Einschraenkung" 1 "Stufe_1" 2 "Stufe_2" 3 "Stufe_3" 4 "Transportmodus" 7 "Ruhestrommessmodus" ;
VAL_ 869 BEM_Anf_KL 0 "keine Anforderung" 1 "Anforderung Kühlerlüfter Ansteuerung" ;
VAL_ 869 BEM_StartStopp_Info 0 "Motorlauf_nicht_notwendig_(Stoppfreigabe)" 1 "Motoranlauf_nicht_zwingend_notwendig_(Stoppverbot,keine_Startanforderung)" 2 "Motoranlauf_zwingend_notwendig_(Startanforderung)" 3 "Systemfehler" ;
VAL_ 869 BEM_EMLIN_ungueltig 0 "Signale_gueltig" 1 "Signale_ungueltig" ;
VAL_ 869 BEM_Batt_Ab 0 "verbunden" 1 "nicht_verbunden" ;
VAL_ 869 NVEM_FMAus_I_Verbrauch 30 "Init" 31 "Fehler" ;
VAL_ 869 NVEM_Freilauf_Info 0 "Freilauf_freigegeben" 1 "Weiches_Veto_uebertippbar" 2 "Hartes_Veto_Abbruch" 3 "Freilauf_Anforderung" ;
VAL_ 869 BEM_NV_NachladAnf 0 "keine_Anforderung" 1 "Anforderung_NV_Nachladung" 2 "Wunsch_NV_Nachladung" 3 "Fehler" ;
VAL_ 869 BEM_Segel_Info 0 "keine_Anforderung" 1 "Mindestdrehzahl_1" 2 "Mindestdrehzahl_2" 3 "Segelveto" ;
VAL_ 869 BEM_HYB_DC_uMinLV 254 "Init" 255 "Fehler" ;
VAL_ 1442 BMS_Fehler_Pilot 0 "geschlossen" 1 "Unterbrechung" ;
VAL_ 1442 BMS_Status_ServiceDisconnect 0 "gesteckt" 1 "gezogen" ;
VAL_ 1442 BMS_Status_Spgfreiheit 0 "Init" 1 "HV_Komponente_spannungsfrei" 2 "HV_Komp_nicht_spannungsfrei" 3 "Fehler_nicht_spannungsfrei" ;
VAL_ 1442 BMS_OBD_Lampe_Anf 0 "kein_MIL_Request" 1 "MIL_Request" ;
VAL_ 1442 BMS_Fehlerstatus 0 "Komponente_IO" 1 "Eingeschr_KompFkt_Isofehler_I" 2 "Eingeschr_KompFkt_Isofehler_II" 3 "Eingeschr_KompFkt_Interlock" 4 "Eingeschr_KompFkt_SD" 5 "Eingeschr_KompFkt_Leistungsred" 6 "Keine_Komponentenfunktion" 7 "Init" ;
VAL_ 1442 BMS_Kapazitaet_02 2047 "Init" ;
VAL_ 1442 BMS_Fehlerlampe_Anf 1 "RedLED_Request" ;
VAL_ 1442 BMS_Warnlampe_Anf 1 "YellowLED_Request" ;
VAL_ 1442 BMS_Kl30c_Status 0 "Init" 1 "geschlossen" 2 "offen" 3 "Fehler" ;
VAL_ 2527679654 BMS_IsoZustand 0 "Init" 1 "groesser_Schwelle_1" 2 "kleiner_Schwelle_1_gesamt" 3 "kleiner_Schwelle_1_intern" 4 "kleiner_Schwelle_2_gesamt" 5 "kleiner_Schwelle_2_intern" 6 "kein_Messwert" 7 "Messung_aktiv" ;
VAL_ 2527679654 BMS_IsoFehler 0 "Init" 1 "kein_IsoFehler" 2 "IsoFehler_Schwelle_1" 3 "IsoFehler_Schwelle_2" 4 "IWU_defekt" 5 "reserviert" 6 "reserviert" 7 "reserviert" ;
VAL_ 2527679654 BMS_IstTemperatur_hoechste 253 "reserviert" 254 "Init" 255 "Fehler" ;
VAL_ 2527679654 BMS_IstTemperatur_niedrigste 253 "reserviert" 254 "Init" 255 "Fehler" ;
VAL_ 2527679654 BMS_IstZellspannung_hoechste 4092 "reserviert" 4093 "reserviert" 4094 "Init" 4095 "Fehler" ;
VAL_ 2527679654 BMS_IstZellspannung_niedrigste 4092 "reserviert" 4093 "reserviert" 4094 "Init" 4095 "Fehler" ;
VAL_ 207 BMS_Fehlerstatus_HV_Schuetze 0 "Init_kein_Diagnoseergebnis" 1 "kein_Schuetz_verschweisst" 2 "mind_1_Schuetz_verschweisst" 3 "Fehler_Schuetzstatuserkennung" ;
VAL_ 207 BMS_ErwGrenzen_aktiv 0 "Init" 1 "extended_Range" ;
VAL_ 207 BMS_IstModus 0 "HV_inaktiv" 1 "Fahren_HV_aktiv" 2 "stBalancing" 3 "externes_Laden" 4 "AC_Laden" 5 "Error_Batt" 6 "DC_Laden" 7 "Init" ;
VAL_ 207 BMS_HVIL_Status 0 "Init" 1 "geschlossen" 2 "offen" 3 "Fehler" ;
VAL_ 207 BMS_Fehler_HVBattAbschaltung 1 "Err_ShutOff" ;
VAL_ 207 BMS_Fehler_HVBattAbschaltung_Anf 1 "Err_ShutOffRequest" ;
VAL_ 207 BMS_Fehler_Leistungsred 0 "keine_Leistungseinschraenkung" 1 "Leistungseinschraenkung" ;
VAL_ 207 BMS_Strom 32765 "nicht_messbar" 32766 "Init" 32767 "Fehler" ;
VAL_ 207 BMS_Fehler_Notabschaltung_Crash 1 "Err_EmergcyShtOffCrash" ;
VAL_ 207 BMS_Spannung_Zwischenkreis 4093 "nicht_messbar" 4094 "Init" 4095 "Fehler" ;
VAL_ 207 BMS_Spannung 4093 "nicht_messbar" 4094 "Init" 4095 "Fehler" ;
VAL_ 2463978704 BMS_Max_Entladestrom 8190 "Init" ;
VAL_ 2463978704 BMS_Max_Ladestrom 8190 "Init" ;
VAL_ 2463978704 BMS_Max_Entladeleistung 8190 "Init" ;
VAL_ 2463978704 BMS_Max_Ladeleistung 8190 "Init" ;
VAL_ 2463978705 BMS_Status_EoHVL_Heizer 0 "Init" 1 "Keine_offene_HV_Leitung_erkannt" 2 "offene_HV_Leitung_erkannt" 3 "Fehler" ;
VAL_ 2463978705 BMS_Ladezustand 2046 "Init" 2047 "Fehler" ;
VAL_ 2463978705 BMS_PerfInd_Entladen 1022 "Init" ;
VAL_ 2463978705 BMS_PerfInd_Laden 1022 "Init" ;
VAL_ 2463978705 BMS_Nutzbare_EntladeEnergie 65534 "Init" 65535 "Fehler" ;
VAL_ 2589283664 BMS_Balancing_Aktiv 0 "Init" 1 "aktiv" 2 "nicht_aktiv" ;
VAL_ 2589283664 BMS_Ladevorgang_aktiv 0 "inaktiv" 1 "aktiv" ;
VAL_ 2589283664 BMS_RIso_Ext 4094 "Init" 4095 "Fehler" ;
VAL_ 2589283664 BMS_Min_Ladezustand 2046 "Init" ;
VAL_ 2589283664 BMS_Max_Energie 8190 "Init" ;
VAL_ 2589283664 BMS_Max_Ladezustand 2046 "Init" ;
VAL_ 2589283665 BMS_BattHeizung_VerbautStatus 0 "nicht_verbaut" 1 "verbaut" ;
VAL_ 2589283665 BMS_Fehler_NTKreis 0 "kein_Fehler" 1 "Fehler" ;
VAL_ 2589283665 BMS_Temperierung_Anf 0 "hoher_Kuehlbedarf" 1 "mittlerer_Kuehlbedarf" 2 "niedriger_Kuehlbedarf" 3 "kein_Temperierungsbedarf_Init" 4 "niedriger_Heizbedarf" 5 "mittlerer_Heizbedarf" 6 "hoher_Heizbedarf" 7 "Umwaelzungsbedarf" ;
VAL_ 2589283665 BMS_Status_Ventil1 0 "Ventil_nicht_angesteuert" 1 "Ventil_angesteuert" 2 "reserviert" 3 "reserviert" 4 "reserviert" 5 "Ventil_nicht_verbaut" 6 "Init" 7 "Fehler" ;
VAL_ 2589283665 BMS_Status_Ventil2 0 "Ventil_nicht_angesteuert" 1 "Ventil_angesteuert" 2 "reserviert" 3 "reserviert" 4 "reserviert" 5 "Ventil_nicht_verbaut" 6 "Init" 7 "Fehler" ;
VAL_ 2589283665 BMS_Pumpe1_Ansteuerung 13 "nicht_verbaut" 14 "Init" 15 "Fehler" ;
VAL_ 2589283665 BMS_Pumpe2_Ansteuerung 13 "nicht_verbaut" 14 "Init" 15 "Fehler" ;
VAL_ 2589283665 BMS_VorlaufTemperatur 253 "nicht_verbaut" 254 "Init" 255 "Fehler" ;
VAL_ 2589283665 BMS_Temperatur 254 "Init" 255 "Fehler" ;
VAL_ 2589283665 BMS_SollVorlauftemperatur 254 "Init" 255 "Fehler" ;
VAL_ 2589283665 BMS_RuecklaufTemperatur 253 "nicht_verbaut" 254 "Init" 255 "Fehler" ;
VAL_ 2589283760 BMS_Max_Spannung 1022 "Init" ;
VAL_ 2589283760 BMS_Min_Spannung 1022 "Init" ;
VAL_ 2589283760 BMS_Dauer_Entladeleistung 4094 "Init" ;
VAL_ 2589283760 BMS_Dauer_Ladeleistung 4094 "Init" ;
VAL_ 2463978646 CHA_Ziel_FahrPr_AGA 0 "keine_Funktion" 1 "Programm_1" 2 "Programm_2" 3 "Programm_3" 4 "Programm_4" 5 "Programm_5" 6 "Programm_6" 7 "Programm_7" 8 "Programm_8" 9 "Programm_9" 10 "Programm_10" 11 "Programm_11" 12 "Programm_12" 13 "Programm_13" 14 "Programm_14" 15 "Programm_15" ;
VAL_ 2463978646 CHA_Ziel_FahrPr_ESP 0 "keine_Funktion" 1 "Programm_1" 2 "Programm_2" 3 "Programm_3" 4 "Programm_4" 5 "Programm_5" 6 "Programm_6" 7 "Programm_7" 8 "Programm_8" 9 "Programm_9" 10 "Programm_10" 11 "Programm_11" 12 "Programm_12" 13 "Programm_13" 14 "Programm_14" 15 "Programm_15" ;
VAL_ 2463978646 CHA_Ziel_FahrPr_Freilauf 0 "keine_Funktion" 1 "Programm_1" 2 "Programm_2" 3 "Programm_3" 4 "Programm_4" 5 "Programm_5" 6 "Programm_6" 7 "Programm_7" 8 "Programm_8" 9 "Programm_9" 10 "Programm_10" 11 "Programm_11" 12 "Programm_12" 13 "Programm_13" 14 "Programm_14" 15 "Programm_15" ;
VAL_ 2463978646 CHA_Fahrer_Umschaltung 0 "keine_oder_automatische_Umschaltung" 1 "manuelle_Umschaltung" ;
VAL_ 2463978646 CHA_Fahrer_Umschaltung_BMA 0 "keine_oder_autom_Umschaltung" 1 "manuelle_Umschaltung" ;
VAL_ 2463978646 CHA_Ziel_FahrPr_MO 0 "keine_Funktion" 1 "Programm_1" 2 "Programm_2" 3 "Programm_3" 4 "Programm_4" 5 "Programm_5" 6 "Programm_6" 7 "Programm_7" 8 "Programm_8" 9 "Programm_9" 10 "Programm_10" 11 "Programm_11" 12 "Programm_12" 13 "Programm_13" 14 "Programm_14" 15 "Programm_15" ;
VAL_ 2463978646 CHA_Ziel_FahrPr_GE 0 "keine_Funktion" 1 "Programm_1" 2 "Programm_2" 3 "Programm_3" 4 "Programm_4" 5 "Programm_5" 6 "Programm_6" 7 "Programm_7" 8 "Programm_8" 9 "Programm_9" 10 "Programm_10" 11 "Programm_11" 12 "Programm_12" 13 "Programm_13" 14 "Programm_14" 15 "Programm_15" ;
VAL_ 2463978646 CHA_Ziel_FahrPr_ALR 0 "keine_Funktion" 1 "Programm_1" 2 "Programm_2" 3 "Programm_3" 4 "Programm_4" 5 "Programm_5" 6 "Programm_6" 7 "Programm_7" 8 "Programm_8" 9 "Programm_9" 10 "Programm_10" 11 "Programm_11" 12 "Programm_12" 13 "Programm_13" 14 "Programm_14" 15 "Programm_15" ;
VAL_ 2463978646 CHA_Ziel_FahrPr_MO_BZS 0 "keine_Funktion" 1 "Programm_1" 2 "Programm_2" 3 "Programm_3" 4 "Programm_4" 5 "Programm_5" 6 "Programm_6" 7 "Programm_7" 8 "Programm_8" 9 "Programm_9" 10 "Programm_10" 11 "Programm_11" 12 "Programm_12" 13 "Programm_13" 14 "Programm_14" 15 "Programm_15" ;
VAL_ 2463978646 CHA_Ziel_FahrPr_DR 0 "keine_Funktion" 1 "Programm_1" 2 "Programm_2" 3 "Programm_3" 4 "Programm_4" 5 "Programm_5" 6 "Programm_6" 7 "Programm_7" 8 "Programm_8" 9 "Programm_9" 10 "Programm_10" 11 "Programm_11" 12 "Programm_12" 13 "Programm_13" 14 "Programm_14" 15 "Programm_15" ;
VAL_ 2463978646 CHA_Ziel_FahrPr_VAQ 0 "keine_Funktion" 1 "Programm_1" 2 "Programm_2" 3 "Programm_3" 4 "Programm_4" 5 "Programm_5" 6 "Programm_6" 7 "Programm_7" 8 "Programm_8" 9 "Programm_9" 10 "Programm_10" 11 "Programm_11" 12 "Programm_12" 13 "Programm_13" 14 "Programm_14" 15 "Programm_15" ;
VAL_ 2463978646 CHA_Ziel_FahrPr_AFS 0 "keine_Funktion" 1 "Programm_1" 2 "Programm_2" 3 "Programm_3" 4 "Programm_4" 5 "Programm_5" 6 "Programm_6" 7 "Programm_7" 8 "Programm_8" 9 "Programm_9" 10 "Programm_10" 11 "Programm_11" 12 "Programm_12" 13 "Programm_13" 14 "Programm_14" 15 "Programm_15" ;
VAL_ 2463978646 CHA_Ziel_FahrPr_PreCrash 0 "keine_Funktion" 1 "Programm_1" 2 "Programm_2" 3 "Programm_3" 4 "Programm_4" 5 "Programm_5" 6 "Programm_6" 7 "Programm_7" 8 "Programm_8" 9 "Programm_9" 10 "Programm_10" 11 "Programm_11" 12 "Programm_12" 13 "Programm_13" 14 "Programm_14" 15 "Programm_15" ;
VAL_ 2463978646 CHA_Ziel_FahrPr_EPS 0 "keine_Funktion" 1 "Programm_1" 2 "Programm_2" 3 "Programm_3" 4 "Programm_4" 5 "Programm_5" 6 "Programm_6" 7 "Programm_7" 8 "Programm_8" 9 "Programm_9" 10 "Programm_10" 11 "Programm_11" 12 "Programm_12" 13 "Programm_13" 14 "Programm_14" 15 "Programm_15" ;
VAL_ 2463978646 CHA_Ziel_FahrPr_ACC 0 "keine_Funktion" 1 "Programm_1" 2 "Programm_2" 3 "Programm_3" 4 "Programm_4" 5 "Programm_5" 6 "Programm_6" 7 "Programm_7" 8 "Programm_8" 9 "Programm_9" 10 "Programm_10" 11 "Programm_11" 12 "Programm_12" 13 "Programm_13" 14 "Programm_14" 15 "Programm_15" ;
VAL_ 2463978646 CHA_Ziel_FahrPr_SAK 0 "keine_Funktion" 1 "Programm_1" 2 "Programm_2" 3 "Programm_3" 4 "Programm_4" 5 "Programm_5" 6 "Programm_6" 7 "Programm_7" 8 "Programm_8" 9 "Programm_9" 10 "Programm_10" 11 "Programm_11" 12 "Programm_12" 13 "Programm_13" 14 "Programm_14" 15 "Programm_15" ;
VAL_ 2463978646 CHA_Ziel_FahrPr_MO_StSt 0 "keine_Funktion" 1 "Programm_1" 2 "Programm_2" 3 "Programm_3" 4 "Programm_4" 5 "Programm_5" 6 "Programm_6" 7 "Programm_7" 8 "Programm_8" 9 "Programm_9" 10 "Programm_10" 11 "Programm_11" 12 "Programm_12" 13 "Programm_13" 14 "Programm_14" 15 "Programm_15" ;
VAL_ 2463978646 CHA_Ziel_FahrPr_EBKV 0 "keine_Funktion" 1 "Programm_1" 2 "Programm_2" 3 "Programm_3" 4 "Programm_4" 5 "Programm_5" 6 "Programm_6" 7 "Programm_7" 8 "Programm_8" 9 "Programm_9" 10 "Programm_10" 11 "Programm_11" 12 "Programm_12" 13 "Programm_13" 14 "Programm_14" 15 "Programm_15" ;
VAL_ 2463978646 CHA_Ziel_FahrPr_IL 0 "keine_Funktion" 1 "Programm_1" 2 "Programm_2" 3 "Programm_3" 4 "Programm_4" 5 "Programm_5" 6 "Programm_6" 7 "Programm_7" 8 "Programm_8" 9 "Programm_9" 10 "Programm_10" 11 "Programm_11" 12 "Programm_12" 13 "Programm_13" 14 "Programm_14" 15 "Programm_15" ;
VAL_ 2463978646 CHA_Current_Mode 0 "keine_Funktion" 1 "Programm_1" 2 "Programm_2" 3 "Programm_3" 4 "Programm_4" 5 "Programm_5" 6 "Programm_6" 7 "Programm_7" 8 "Programm_8" 9 "Programm_9" 10 "Programm_10" 11 "Programm_11" 12 "Programm_12" 13 "Programm_13" 14 "Programm_14" 15 "Programm_15" ;
VAL_ 2463978646 CHA_Ziel_FahrPr_QS 0 "keine_Funktion" 1 "Programm_1" 2 "Programm_2" 3 "Programm_3" 4 "Programm_4" 5 "Programm_5" 6 "Programm_6" 7 "Programm_7" 8 "Programm_8" 9 "Programm_9" 10 "Programm_10" 11 "Programm_11" 12 "Programm_12" 13 "Programm_13" 14 "Programm_14" 15 "Programm_15" ;
VAL_ 2463978646 CHA_Ziel_FahrPr_SCU 0 "keine_Funktion" 1 "Programm_1" 2 "Programm_2" 3 "Programm_3" 4 "Programm_4" 5 "Programm_5" 6 "Programm_6" 7 "Programm_7" 8 "Programm_8" 9 "Programm_9" 10 "Programm_10" 11 "Programm_11" 12 "Programm_12" 13 "Programm_13" 14 "Programm_14" 15 "Programm_15" ;
VAL_ 2463978646 CHA_Ziel_FahrPr_HAL 0 "keine_Funktion" 1 "Programm_1" 2 "Programm_2" 3 "Programm_3" 4 "Programm_4" 5 "Programm_5" 6 "Programm_6" 7 "Programm_7" 8 "Programm_8" 9 "Programm_9" 10 "Programm_10" 11 "Programm_11" 12 "Programm_12" 13 "Programm_13" 14 "Programm_14" 15 "Programm_15" ;
VAL_ 2463978646 CHA_Ziel_FahrPr_NR 0 "keine_Funktion" 1 "Programm_1" 2 "Programm_2" 3 "Programm_3" 4 "Programm_4" 5 "Programm_5" 6 "Programm_6" 7 "Programm_7" 8 "Programm_8" 9 "Programm_9" 10 "Programm_10" 11 "Programm_11" 12 "Programm_12" 13 "Programm_13" 14 "Programm_14" 15 "Programm_15" ;
VAL_ 2463978646 CHA_Ziel_FahrPr_AV 0 "keine_Funktion" 1 "Programm_1" 2 "Programm_2" 3 "Programm_3" 4 "Programm_4" 5 "Programm_5" 6 "Programm_6" 7 "Programm_7" 8 "Programm_8" 9 "Programm_9" 10 "Programm_10" 11 "Programm_11" 12 "Programm_12" 13 "Programm_13" 14 "Programm_14" 15 "Programm_15" ;
VAL_ 2463978646 CHA_Ziel_FahrPr_MXB 0 "keine_Funktion" 1 "Programm_1" 2 "Programm_2" 3 "Programm_3" 4 "Programm_4" 5 "Programm_5" 6 "Programm_6" 7 "Programm_7" 8 "Programm_8" 9 "Programm_9" 10 "Programm_10" 11 "Programm_11" 12 "Programm_12" 13 "Programm_13" 14 "Programm_14" 15 "Programm_15" ;
VAL_ 2463978646 CHA_Ziel_FahrPr_AFR 0 "keine_Funktion" 1 "Programm_1" 2 "Programm_2" 3 "Programm_3" 4 "Programm_4" 5 "Programm_5" 6 "Programm_6" 7 "Programm_7" 8 "Programm_8" 9 "Programm_9" 10 "Programm_10" 11 "Programm_11" 12 "Programm_12" 13 "Programm_13" 14 "Programm_14" 15 "Programm_15" ;
VAL_ 2463978646 CHA_Ziel_FahrPr_HDC 0 "keine_Funktion" 1 "Programm_1" 2 "Programm_2" 3 "Programm_3" 4 "Programm_4" 5 "Programm_5" 6 "Programm_6" 7 "Programm_7" 8 "Programm_8" 9 "Programm_9" 10 "Programm_10" 11 "Programm_11" 12 "Programm_12" 13 "Programm_13" 14 "Programm_14" 15 "Programm_15" ;
VAL_ 2463978646 CHA_Ziel_FahrPr_EAR 0 "keine_Funktion" 1 "Programm_1" 2 "Programm_2" 3 "Programm_3" 4 "Programm_4" 5 "Programm_5" 6 "Programm_6" 7 "Programm_7" 8 "Programm_8" 9 "Programm_9" 10 "Programm_10" 11 "Programm_11" 12 "Programm_12" 13 "Programm_13" 14 "Programm_14" 15 "Programm_15" ;
VAL_ 2463978646 CHA_Ziel_FahrPr_AEB 0 "keine_Funktion" 1 "Programm_1" 2 "Programm_2" 3 "Programm_3" 4 "Programm_4" 5 "Programm_5" 6 "Programm_6" 7 "Programm_7" 8 "Programm_8" 9 "Programm_9" 10 "Programm_10" 11 "Programm_11" 12 "Programm_12" 13 "Programm_13" 14 "Programm_14" 15 "Programm_15" ;
VAL_ 2463978646 CHA_Ziel_FahrPr_FCWO 0 "keine_Funktion" 1 "Programm_1" 2 "Programm_2" 3 "Programm_3" 4 "Programm_4" 5 "Programm_5" 6 "Programm_6" 7 "Programm_7" 8 "Programm_8" 9 "Programm_9" 10 "Programm_10" 11 "Programm_11" 12 "Programm_12" 13 "Programm_13" 14 "Programm_14" 15 "Programm_15" ;
VAL_ 2463978646 CHA_Ziel_FahrPr_FCWP 0 "keine_Funktion" 1 "Programm_1" 2 "Programm_2" 3 "Programm_3" 4 "Programm_4" 5 "Programm_5" 6 "Programm_6" 7 "Programm_7" 8 "Programm_8" 9 "Programm_9" 10 "Programm_10" 11 "Programm_11" 12 "Programm_12" 13 "Programm_13" 14 "Programm_14" 15 "Programm_15" ;
VAL_ 2463978646 CHA_Ziel_FahrPr_ToS_laengs 0 "keine_Funktion" 1 "Programm_1" 2 "Programm_2" 3 "Programm_3" 4 "Programm_4" 5 "Programm_5" 6 "Programm_6" 7 "Programm_7" 8 "Programm_8" 9 "Programm_9" 10 "Programm_10" 11 "Programm_11" 12 "Programm_12" 13 "Programm_13" 14 "Programm_14" 15 "Programm_15" ;
VAL_ 2463978646 CHA_Ziel_FahrPr_ToS_quer 0 "keine_Funktion" 1 "Programm_1" 2 "Programm_2" 3 "Programm_3" 4 "Programm_4" 5 "Programm_5" 6 "Programm_6" 7 "Programm_7" 8 "Programm_8" 9 "Programm_9" 10 "Programm_10" 11 "Programm_11" 12 "Programm_12" 13 "Programm_13" 14 "Programm_14" 15 "Programm_15" ;
VAL_ 2463978646 CHA_Ziel_FahrPr_mFDR 0 "keine_Funktion" 1 "Programm_1" 2 "Programm_2" 3 "Programm_3" 4 "Programm_4" 5 "Programm_5" 6 "Programm_6" 7 "Programm_7" 8 "Programm_8" 9 "Programm_9" 10 "Programm_10" 11 "Programm_11" 12 "Programm_12" 13 "Programm_13" 14 "Programm_14" 15 "Programm_15" ;
VAL_ 2463978646 CHA_Ziel_FahrPr_Reku_ZwGas 0 "kein_Funktion" 1 "Programm_1" 2 "Programm_2" 3 "Programm_3" 4 "Programm_4" 5 "Programm_5" 6 "Programm_6" 7 "Programm_7" 8 "Programm_8" 9 "Programm_9" 10 "Programm_10" 11 "Programm_11" 12 "Programm_12" 13 "Programm_13" 14 "Programm_14" 15 "Programm_15" ;
VAL_ 2463978646 CHA_Ziel_FahrPr_MO_Freilauf 0 "keine_Funktion" 1 "Programm_1" 2 "Programm_2" 3 "Programm_3" 4 "Programm_4" 5 "Programm_5" 6 "Programm_6" 7 "Programm_7" 8 "Programm_8" 9 "Programm_9" 10 "Programm_10" 11 "Programm_11" 12 "Programm_12" 13 "Programm_13" 14 "Programm_14" 15 "Programm_15" ;
VAL_ 2463978646 CHA_Ziel_FahrPr_BMS 0 "keine_Funktion" 1 "Programm_1" 2 "Programm_2" 3 "Programm_3" 4 "Programm_4" 5 "Programm_5" 6 "Programm_6" 7 "Programm_7" 8 "Programm_8" 9 "Programm_9" 10 "Programm_10" 11 "Programm_11" 12 "Programm_12" 13 "Programm_13" 14 "Programm_14" 15 "Programm_15" ;
VAL_ 2463978646 CHA_Current_Mode_BMA 0 "keine_Funktion" 1 "Programm_1" 2 "Programm_2" 3 "Programm_3" 4 "Programm_4" 5 "Programm_5" 6 "Programm_6" 7 "Programm_7" 8 "Programm_8" 9 "Programm_9" 10 "Programm_10" 11 "Programm_11" 12 "Programm_12" 13 "Programm_13" 14 "Programm_14" 15 "Programm_15" ;
VAL_ 2463978646 CHA_Ziel_FahrPr_PDC 0 "keine_Funktion" 1 "Programm_1" 2 "Programm_2" 3 "Programm_3" 4 "Programm_4" 5 "Programm_5" 6 "Programm_6" 7 "Programm_7" 8 "Programm_8" 9 "Programm_9" 10 "Programm_10" 11 "Programm_11" 12 "Programm_12" 13 "Programm_13" 14 "Programm_14" 15 "Programm_15" ;
VAL_ 2463978646 CHA_Ziel_FahrPr_HHC 0 "keine_Funktion" 1 "Programm_1" 2 "Programm_2" 3 "Programm_3" 4 "Programm_4" 5 "Programm_5" 6 "Programm_6" 7 "Programm_7" 8 "Programm_8" 9 "Programm_9" 10 "Programm_10" 11 "Programm_11" 12 "Programm_12" 13 "Programm_13" 14 "Programm_14" 15 "Programm_15" ;
VAL_ 2463978646 CHA_Ziel_FahrPr_EDS 0 "keine_Funktion" 1 "Programm_1" 2 "Programm_2" 3 "Programm_3" 4 "Programm_4" 5 "Programm_5" 6 "Programm_6" 7 "Programm_7" 8 "Programm_8" 9 "Programm_9" 10 "Programm_10" 11 "Programm_11" 12 "Programm_12" 13 "Programm_13" 14 "Programm_14" 15 "Programm_15" ;
VAL_ 2463978646 CHA_Ziel_FahrPr_PACC 0 "keine_Funktion" 1 "Programm_1" 2 "Programm_2" 3 "Programm_3" 4 "Programm_4" 5 "Programm_5" 6 "Programm_6" 7 "Programm_7" 8 "Programm_8" 9 "Programm_9" 10 "Programm_10" 11 "Programm_11" 12 "Programm_12" 13 "Programm_13" 14 "Programm_14" 15 "Programm_15" ;
VAL_ 2463978646 CHA_Ziel_FahrPr_AGK 0 "keine_Funktion" 1 "Programm_1" 2 "Programm_2" 3 "Programm_3" 4 "Programm_4" 5 "Programm_5" 6 "Programm_6" 7 "Programm_7" 8 "Programm_8" 9 "Programm_9" 10 "Programm_10" 11 "Programm_11" 12 "Programm_12" 13 "Programm_13" 14 "Programm_14" 15 "Programm_15" ;
